VERSION "created by canmatrix"

NS_ :

BS_:

BU_: CEM HUT GW T_BOX XBOX_D DVR Tester

BO_ 482 HCU_HC8: 8 GW
 SG_ HCU_PhoneChrgnModeResp : 15|1@0+ (1,0) [0|1] ""  T_BOX
 SG_ HCU_PhoneChrgnReqResp : 14|1@0+ (1,0) [0|1] ""  T_BOX
 SG_ HCU_HUTChrgnModeResp : 13|1@0+ (1,0) [0|1] ""  T_BOX
 SG_ HCU_HUTChrgnReqResp : 12|1@0+ (1,0) [0|1] ""  T_BOX
 SG_ HCU_TboxEngStrtReq : 11|1@0+ (1,0) [0|1] ""  T_BOX
 SG_ HCU_TotalScore : 23|3@0+ (1,0) [0|5] ""  HUT
 SG_ HCU_HC8_0x1E2 : 0|64@1+ (1,0) [0|0] ""  HUT

BO_ 483 BMS_FD14: 8 GW
 SG_ BMS_ChrgTimResp : 9|1@0+ (1,0) [0|1] ""  HUT,T_BOX
 SG_ BMS_FD14_0x1E3 : 0|64@1+ (1,0) [0|0] ""  HUT

BO_ 510 T_BOX_FD9: 8 T_BOX
 SG_ T_BOX_RemtDrvSeatHeatgLvlSet_Nin : 11|4@0+ (1,0) [0|15] ""  CEM
 SG_ T_BOX_RemtPassSeatHeatgLvlSet_Ni : 15|4@0+ (1,0) [0|15] ""  CEM
 SG_ T_BOX_RemtSecRowLeSeatHeatgLvlSe : 19|4@0+ (1,0) [0|15] ""  CEM
 SG_ T_BOX_RemtSecRowRiSeatHeatgLvlSe : 23|4@0+ (1,0) [0|15] ""  CEM
 SG_ T_BOX_ChrgTim_Hour : 39|5@0+ (1,0) [0|31] ""  GW
 SG_ T_BOX_ChrgTim_Minutes : 34|6@0+ (1,0) [0|63] ""  GW
 SG_ T_BOX_ChrgTim_Second : 44|6@0+ (1,0) [0|63] ""  GW
 SG_ T_BOX_ChrgTim_Year_Left : 31|4@0+ (1,0) [0|15] ""  GW
 SG_ T_BOX_ChrgTim_Year_Right : 27|4@0+ (1,0) [0|15] ""  GW
 SG_ T_BOX_ChrgTim_Month : 54|4@0+ (1,0) [0|15] ""  GW
 SG_ T_BOX_ChrgTim_Day : 50|5@0+ (1,0) [0|31] ""  GW,HUT
 SG_ T_BOX_FD9_0x1FE : 0|64@1+ (1,0) [0|0] ""  HUT

BO_ 513 HCU_HP5: 8 GW
 SG_ HCU_V2LReminder : 19|2@0+ (1,0) [0|3] ""  HUT
 SG_ HCU_SOCMngmntSts : 55|1@0+ (1,0) [0|1] ""  HUT
 SG_ HCU_ARFSts : 54|1@0+ (1,0) [0|1] ""  HUT
 SG_ HCU_ASFCSts : 53|1@0+ (1,0) [0|1] ""  HUT
 SG_ HCU_AGSSts : 52|1@0+ (1,0) [0|1] ""  HUT
 SG_ PDCU_AvailabilityOfARF : 51|4@0+ (1,0) [0|5] ""  HUT
 SG_ PDCU_lossenPedalPrompt : 63|1@0+ (1,0) [0|1] ""  HUT
 SG_ PDCU_EvSave_disl : 62|1@0+ (1,0) [0|1] ""  HUT
 SG_ HCU_HP5_0x201 : 0|64@1+ (1,0) [0|0] ""  HUT

BO_ 515 HUT_FD2: 64 HUT
 SG_ HUT_OD_Obj0_ID : 15|4@0+ (1,0) [0|9] "" Vector__XXX
 SG_ HUT_OD_Obj0_type : 23|3@0+ (1,0) [0|7] "" Vector__XXX
 SG_ HUT_OD_Obj0_Confidence : 11|4@0+ (0.1,0) [0|1] "" Vector__XXX
 SG_ HUT_OD_Obj0_width : 20|7@0+ (0.1,0) [0|12.6] "m" Vector__XXX
 SG_ HUT_OD_Obj0_Ground_Pos_X : 39|12@0+ (0.01,0) [0|40] "m" Vector__XXX
 SG_ HUT_OD_Obj0_Ground_Pos_Y : 43|12@0+ (0.01,-20) [-20|20] "m" Vector__XXX
 SG_ HTU_OD_Obj1_ID : 79|4@0+ (1,0) [0|9] "" Vector__XXX
 SG_ HUT_OD_Obj1_type : 87|3@0+ (1,0) [0|7] "" Vector__XXX
 SG_ HUT_OD_Obj1_Confidence : 75|4@0+ (0.1,0) [0|1] "" Vector__XXX
 SG_ HUT_OD_Obj1_width : 84|7@0+ (0.1,0) [0|12.6] "m" Vector__XXX
 SG_ HUT_OD_Obj1_Ground_Pos_X : 103|12@0+ (0.01,0) [0|40] "m" Vector__XXX
 SG_ HUT_OD_Obj1_Ground_Pos_Y : 107|12@0+ (0.01,-20) [-20|20] "m" Vector__XXX
 SG_ HUT_OD_Obj2_ID : 143|4@0+ (1,0) [0|9] "" Vector__XXX
 SG_ HUT_OD_Obj2_type : 151|3@0+ (1,0) [0|7] "" Vector__XXX
 SG_ HUT_OD_Obj2_Confidence : 139|4@0+ (0.1,0) [0|1] "" Vector__XXX
 SG_ HUT_OD_Obj2_width : 148|7@0+ (0.1,0) [0|12.6] "m" Vector__XXX
 SG_ HUT_OD_Obj2_Ground_Pos_X : 167|12@0+ (0.01,0) [0|40] "m" Vector__XXX
 SG_ HUT_OD_Obj2_Ground_Pos_Y : 171|12@0+ (0.01,-20) [-20|20] "m" Vector__XXX
 SG_ HUT_OD_Obj3_ID : 207|4@0+ (1,0) [0|9] "" Vector__XXX
 SG_ HUT_OD_Obj3_type : 215|3@0+ (1,0) [0|7] "" Vector__XXX
 SG_ HUT_OD_Obj3_Confidence : 203|4@0+ (0.1,0) [0|1] "" Vector__XXX
 SG_ HUT_OD_Obj3_width : 212|7@0+ (0.1,0) [0|12.6] "m" Vector__XXX
 SG_ HUT_OD_Obj3_Ground_Pos_X : 231|12@0+ (0.01,0) [0|40] "m" Vector__XXX
 SG_ HUT_OD_Obj3_Ground_Pos_Y : 235|12@0+ (0.01,-20) [-20|20] "m" Vector__XXX
 SG_ HUT_OD_Obj4_ID : 271|4@0+ (1,0) [0|9] "" Vector__XXX
 SG_ HUT_OD_Obj4_type : 279|3@0+ (1,0) [0|7] "" Vector__XXX
 SG_ HUT_OD_Obj4_Confidence : 267|4@0+ (0.1,0) [0|1] "" Vector__XXX
 SG_ HUT_OD_Obj4_width : 276|7@0+ (0.1,0) [0|12.6] "m" Vector__XXX
 SG_ HUT_OD_Obj4_Ground_Pos_X : 295|12@0+ (0.01,0) [0|40] "m" Vector__XXX
 SG_ HUT_OD_Obj4_Ground_Pos_Y : 299|12@0+ (0.01,-20) [-20|20] "m" Vector__XXX
 SG_ HUT_OD_Obj5_ID : 335|4@0+ (1,0) [0|9] "" Vector__XXX
 SG_ HUT_OD_Obj5_type : 343|3@0+ (1,0) [0|7] "" Vector__XXX
 SG_ HUT_OD_Obj5_Confidence : 331|4@0+ (0.1,0) [0|1] "" Vector__XXX
 SG_ HUT_OD_Obj5_width : 340|7@0+ (0.1,0) [0|12.6] "m" Vector__XXX
 SG_ HUT_OD_Obj5_Ground_Pos_X : 359|12@0+ (0.01,0) [0|40] "m" Vector__XXX
 SG_ HUT_OD_Obj5_Ground_Pos_Y : 363|12@0+ (0.01,-20) [-20|20] "m" Vector__XXX
 SG_ HUT_OD_Obj6_ID : 399|4@0+ (1,0) [0|9] "" Vector__XXX
 SG_ HUT_OD_Obj6_type : 407|3@0+ (1,0) [0|7] "" Vector__XXX
 SG_ HUT_OD_Obj6_Confidence : 395|4@0+ (0.1,0) [0|1] "" Vector__XXX
 SG_ HUT_OD_Obj6_width : 404|7@0+ (0.1,0) [0|12.6] "m" Vector__XXX
 SG_ HUT_OD_Obj6_Ground_Pos_X : 423|12@0+ (0.01,0) [0|40] "m" Vector__XXX
 SG_ HUT_OD_Obj6_Ground_Pos_Y : 427|12@0+ (0.01,-20) [-20|20] "m" Vector__XXX
 SG_ HUT_FD2_0x203 : 0|512@1+ (1,0) [0|0] "" Vector__XXX

BO_ 616 HCU_HC3: 8 GW
 SG_ HCU_ChrgDchrgSts : 39|2@0+ (1,0) [0|3] ""  T_BOX
 SG_ HCU_BattLowTempWarn : 51|2@0+ (1,0) [0|3] ""  HUT
 SG_ HCU_BattLowTempHeatSts : 49|2@0+ (1,0) [0|3] ""  HUT
 SG_ HCU_HC3_0x268 : 0|64@1+ (1,0) [0|0] ""  HUT

BO_ 645 BMS8: 8 GW
 SG_ BMS_BattHeatRunaway : 61|2@0+ (1,0) [0|3] ""  HUT,T_BOX
 SG_ BMS_DisSOC1 : 31|8@0+ (1,0) [0|100] "%"  HUT,T_BOX
 SG_ BMS8_0x285 : 0|64@1+ (1,0) [0|0] ""  HUT

BO_ 690 HUT27: 8 HUT
 SG_ ExpertModReq_HUT_HCU : 62|2@0+ (1,0) [0|3] ""  GW
 SG_ HUT27_0x2B2 : 0|64@1+ (1,0) [0|0] "" Vector__XXX

BO_ 708 BMS35: 8 GW
 SG_ BMS_BattSOCLimResp : 42|3@0+ (1,0) [0|7] ""  HUT
 SG_ BMS35_0x2C4 : 0|64@1+ (1,0) [0|0] ""  HUT

BO_ 743 BCM10: 16 CEM
 SG_ RFPosnLmpWorkCmd : 15|1@0+ (1,0) [0|1] ""  T_BOX
 SG_ LFPosnLmpWorkCmd : 12|1@0+ (1,0) [0|1] ""  T_BOX
 SG_ HiBeamWorkCmd : 11|1@0+ (1,0) [0|1] ""  T_BOX
 SG_ LowBeamWorkCmd : 10|1@0+ (1,0) [0|1] ""  T_BOX
 SG_ RTurnLmpWorkCmd : 9|1@0+ (1,0) [0|1] ""  T_BOX
 SG_ LTurnLampWorkCmd : 8|1@0+ (1,0) [0|1] ""  T_BOX
 SG_ RDayRunngLmpWorkCmd : 21|1@0+ (1,0) [0|1] ""  T_BOX
 SG_ LDayRunngLmpWorkCmd : 20|1@0+ (1,0) [0|1] ""  T_BOX
 SG_ RFFogLmpWorkCmd : 19|1@0+ (1,0) [0|1] ""  T_BOX
 SG_ LFFogLmpWorkCmd : 18|1@0+ (1,0) [0|1] ""  T_BOX
 SG_ LicPlateLmpWorkCmd : 27|1@0+ (1,0) [0|1] ""  T_BOX
 SG_ ReversLampWorkCmd : 26|1@0+ (1,0) [0|1] ""  T_BOX
 SG_ BrkLmpWorkCmd : 25|1@0+ (1,0) [0|1] ""  T_BOX
 SG_ RFogLmpWorkCmd : 24|1@0+ (1,0) [0|1] ""  T_BOX
 SG_ RRPosnLmpWorkCmd : 47|1@0+ (1,0) [0|1] ""  T_BOX
 SG_ LRPosnLmpWorkCmd : 46|1@0+ (1,0) [0|1] ""  T_BOX

BO_ 788 HCU_HC6: 8 GW
 SG_ HCU_ACLineDisconnect : 33|2@0+ (1,0) [0|3] ""  HUT,T_BOX
 SG_ HCU_ChargSts : 47|3@0+ (1,0) [0|7] ""  HUT,T_BOX
 SG_ HCU_IntelBattTempMagSts : 37|1@0+ (1,0) [0|1] ""  HUT
 SG_ HCU_HC6_0x314 : 0|64@1+ (1,0) [0|0] ""  HUT

BO_ 790 OBC1: 8 GW
 SG_ OBC_ModSts : 19|4@0+ (1,0) [0|15] ""  HUT
 SG_ OBC1_0x316 : 0|64@1+ (1,0) [0|0] ""  HUT

BO_ 791 OBC2: 8 GW
 SG_ OBC_ConnectSts : 15|2@0+ (1,0) [0|3] ""  HUT,T_BOX
 SG_ OBC2_0x317 : 0|64@1+ (1,0) [0|0] ""  HUT

BO_ 829 T_BOX_FD6: 16 T_BOX
 SG_ T_BOX_RemtLRTempSet : 21|6@0+ (0.5,16) [16.5|31.5] "Ã‚Â°C"  GW
 SG_ T_BOX_RemtRRTempSet : 29|6@0+ (0.5,16) [16.5|31.5] "Ã‚Â°C" Vector__XXX
 SG_ T_BOX_RemtRearAutoCtrl : 47|2@0+ (1,0) [0|3] ""  GW
 SG_ T_BOX_RemtSecRowLeSeatVentnLvlSe : 10|3@0+ (1,0) [0|7] ""  CEM
 SG_ T_BOX_RemtSecRowRiSeatVentnLvlSe : 13|3@0+ (1,0) [0|7] ""  CEM
 SG_ T_BOX_MbrMonrEnReq : 35|2@0+ (1,0) [0|3] "" Vector__XXX
 SG_ ReleAlarm_APP : 33|2@0+ (1,0) [0|3] "" Vector__XXX
 SG_ T_BOX_RemtSteerWheelHeatCtrl : 15|2@0+ (1,0) [0|3] ""  GW
 SG_ T_BOX_AVPActvReq : 3|2@0+ (1,0) [0|3] ""  GW

BO_ 850 BMS19: 8 GW
 SG_ BMS_IntelEngIdlChrgnSts : 45|2@0+ (1,0) [0|3] ""  HUT
 SG_ BMS_BattKeepTempSts : 18|1@0+ (1,0) [0|1] ""  HUT
 SG_ BMS19_0x352 : 0|64@1+ (1,0) [0|0] ""  HUT

BO_ 865 HCU_FD6: 64 GW
 SG_ HCU_HVILSts : 218|2@0+ (1,0) [0|3] ""  T_BOX
 SG_ HCU_BMSSleepCmd : 216|1@0+ (1,0) [0|1] ""  T_BOX
 SG_ HCU_P2MActHvDcCurr_RM : 263|16@0+ (0.1,-1000) [-1000|1000] "A"  T_BOX
 SG_ HCU_P2MActHvDcVolt_RM : 279|16@0+ (0.1,0) [0|6000] "V"  T_BOX
 SG_ HCU_DTCNumber1 : 295|10@0+ (1,0) [0|1023] ""  T_BOX
 SG_ HCU_DTCNumber2 : 301|10@0+ (1,0) [0|1023] ""  T_BOX
 SG_ HCU_MotorAmount_RM : 335|8@0+ (1,0) [1|253] ""  T_BOX

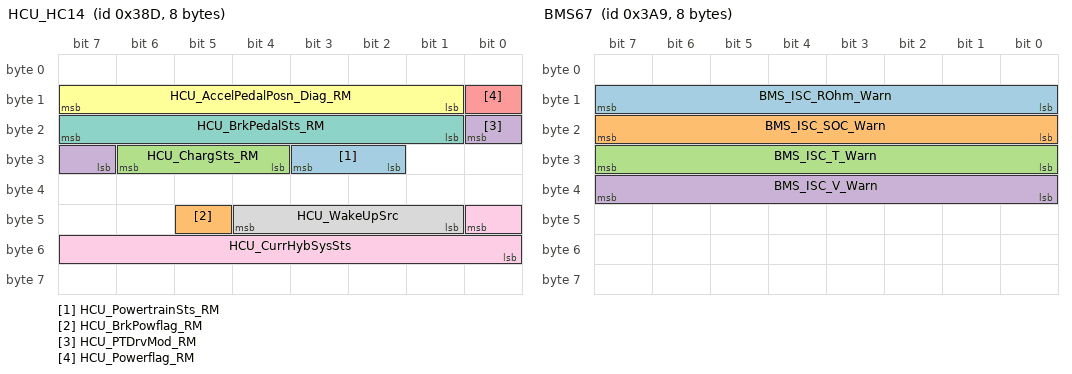
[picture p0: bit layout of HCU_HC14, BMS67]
BO_ 909 HCU_HC14: 8 GW
 SG_ HCU_PowertrainSts_RM : 27|2@0+ (1,0) [0|3] ""  T_BOX
 SG_ HCU_BrkPowflag_RM : 45|1@0+ (1,0) [0|1] ""  T_BOX
 SG_ HCU_ChargSts_RM : 30|3@0+ (1,0) [0|7] ""  T_BOX
 SG_ HCU_PTDrvMod_RM : 16|2@0+ (1,0) [0|3] ""  T_BOX
 SG_ HCU_Powerflag_RM : 8|1@0+ (1,0) [0|1] ""  T_BOX
 SG_ HCU_AccelPedalPosn_Diag_RM : 15|7@0+ (1,0) [0|100] "%"  T_BOX
 SG_ HCU_BrkPedalSts_RM : 23|7@0+ (1,0) [0|101] ""  T_BOX
 SG_ HCU_WakeUpSrc : 44|4@0+ (1,0) [0|15] ""  T_BOX
 SG_ HCU_CurrHybSysSts : 40|9@0+ (1,0) [0|500] ""  T_BOX

BO_ 937 BMS67: 8 GW
 SG_ BMS_ISC_ROhm_Warn : 15|8@0+ (0.1,0) [0|5] ""  T_BOX
 SG_ BMS_ISC_SOC_Warn : 23|8@0+ (1,0) [0|100] ""  T_BOX
 SG_ BMS_ISC_T_Warn : 31|8@0+ (1,-40) [-40|125] "Ã‚Â°C"  T_BOX
 SG_ BMS_ISC_V_Warn : 39|8@0+ (0.1,0) [0|5] "V"  T_BOX

BO_ 942 BMS66: 8 GW
 SG_ BMS_SocJumpWarn_RM : 7|1@0+ (1,0) [0|1] ""  HUT,T_BOX
 SG_ BMS_PackOverChrgWarn_RM : 6|1@0+ (1,0) [0|1] ""  HUT,T_BOX
 SG_ BMS_ChrgSts_RM : 5|3@0+ (1,0) [0|7] ""  HUT,T_BOX
 SG_ BMS_IsolationRValue_RM : 15|16@0+ (1,0) [0|60000] "Kohm"  HUT,T_BOX
 SG_ BMS_PackCurr_RM : 31|15@0+ (0.1,-1000) [-1000|1000] "A"  HUT,T_BOX
 SG_ BMS_SocOverWarn_RM : 32|1@0+ (1,0) [0|1] ""  HUT,T_BOX
 SG_ BMS_BattOverTempRank_RM : 47|1@0+ (1,0) [0|1] ""  HUT,T_BOX
 SG_ BMS_BattOverVoltRank_RM : 46|1@0+ (1,0) [0|1] ""  HUT,T_BOX
 SG_ BMS_BattSOCLowRank_RM : 45|1@0+ (1,0) [0|1] ""  HUT,T_BOX
 SG_ BMS_VCUIsolateErr_RM : 44|1@0+ (1,0) [0|1] ""  HUT,T_BOX
 SG_ BMS_BattUnderVoltRank_RM : 43|1@0+ (1,0) [0|1] ""  HUT,T_BOX
 SG_ BMS_CellDeltaVoltRank_RM : 42|1@0+ (1,0) [0|1] ""  HUT,T_BOX
 SG_ BMS_CellOverVoltRank_RM : 41|1@0+ (1,0) [0|1] ""  HUT,T_BOX
 SG_ BMS_CellUnderVoltRank_RM : 40|1@0+ (1,0) [0|1] ""  HUT,T_BOX
 SG_ BMS_DeltaTempRank_RM : 55|1@0+ (1,0) [0|1] ""  HUT,T_BOX
 SG_ BMS_PackMismatchWarn_RM : 54|1@0+ (1,0) [0|1] ""  HUT,T_BOX
 SG_ BMS_PackVolt_RM : 53|14@0+ (0.1,0) [0|1000] "V"  HUT,T_BOX
 SG_ BMS66_0x3AE : 0|64@1+ (1,0) [0|0] ""  HUT

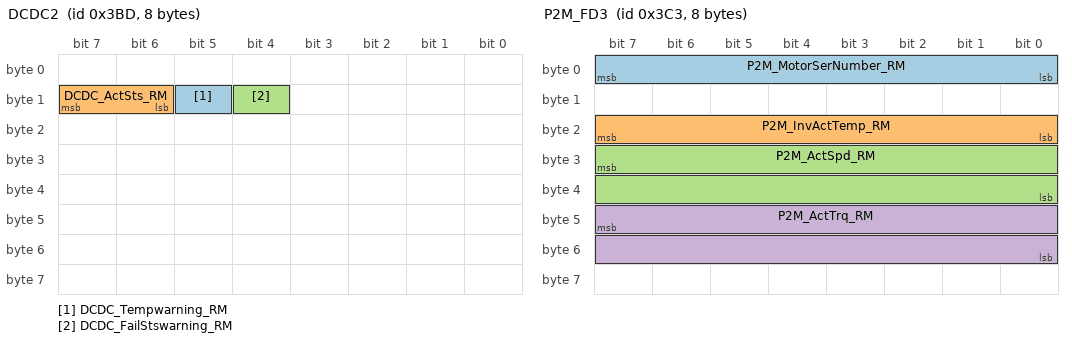
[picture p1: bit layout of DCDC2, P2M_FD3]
BO_ 957 DCDC2: 8 GW
 SG_ DCDC_Tempwarning_RM : 13|1@0+ (1,0) [0|1] ""  T_BOX
 SG_ DCDC_ActSts_RM : 15|2@0+ (1,0) [0|3] ""  T_BOX
 SG_ DCDC_FailStswarning_RM : 12|1@0+ (1,0) [0|1] ""  T_BOX

BO_ 959 BMS22: 8 GW
 SG_ BMS_ChrgDurationTime : 47|10@0+ (1,0) [0|1022] "minute"  HUT,T_BOX
 SG_ BMS22_0x3BF : 0|64@1+ (1,0) [0|0] ""  HUT

BO_ 963 P2M_FD3: 8 GW
 SG_ P2M_MotorSerNumber_RM : 7|8@0+ (1,0) [1|253] ""  T_BOX
 SG_ P2M_InvActTemp_RM : 23|8@0+ (1,-40) [-40|210] "Ã‚Â°C"  T_BOX
 SG_ P2M_ActSpd_RM : 31|16@0+ (1,-20000) [-20000|45531] "rpm"  T_BOX
 SG_ P2M_ActTrq_RM : 47|16@0+ (0.1,-2000) [-2000|4553.1] "Nm"  T_BOX

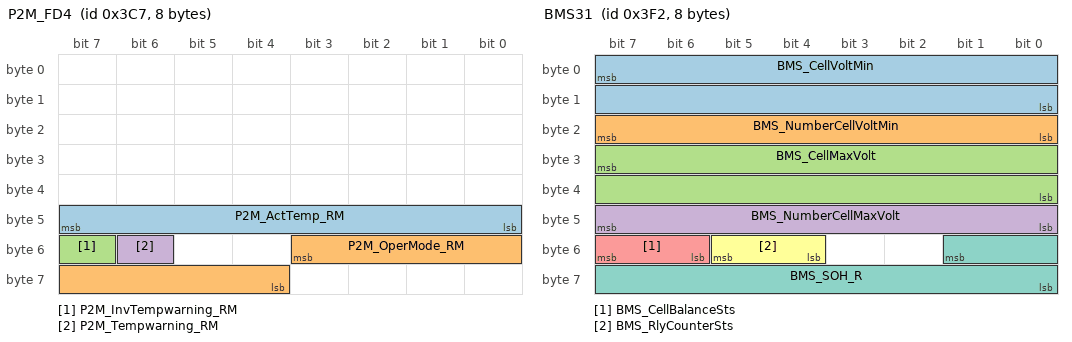
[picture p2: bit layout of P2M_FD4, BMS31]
BO_ 967 P2M_FD4: 8 GW
 SG_ P2M_ActTemp_RM : 47|8@0+ (1,-40) [-40|210] "Ã‚Â°C"  T_BOX
 SG_ P2M_OperMode_RM : 51|8@0+ (1,0) [0|255] ""  T_BOX
 SG_ P2M_InvTempwarning_RM : 55|1@0+ (1,0) [0|1] ""  T_BOX
 SG_ P2M_Tempwarning_RM : 54|1@0+ (1,0) [0|1] ""  T_BOX

BO_ 976 BMS26: 8 GW
 SG_ BMS_BattTempMax : 15|8@0+ (1,-40) [-40|90] "Ã‚Â°C"  T_BOX
 SG_ BMS_BattTempMin : 23|8@0+ (1,-40) [-40|90] "Ã‚Â°C"  T_BOX

BO_ 977 BMS_FD5: 64 GW
 SG_ BMS_SingleCellVolt_1 : 263|16@0+ (0.001,0) [0|60] "V"  T_BOX
 SG_ BMS_SingleCellVolt_2 : 279|16@0+ (0.001,0) [0|60] "V"  T_BOX
 SG_ BMS_SingleCellVolt_3 : 295|16@0+ (0.001,0) [0|60] "V"  T_BOX
 SG_ BMS_SingleCellVolt_4 : 311|16@0+ (0.001,0) [0|60] "V"  T_BOX
 SG_ BMS_SingleCellVolt_5 : 327|16@0+ (0.001,0) [0|60] "V"  T_BOX
 SG_ BMS_SingleCellVolt_6 : 343|16@0+ (0.001,0) [0|60] "V"  T_BOX
 SG_ BMS_SingleCellVolt_7 : 359|16@0+ (0.001,0) [0|60] "V"  T_BOX
 SG_ BMS_SingleCellVolt_8 : 375|16@0+ (0.001,0) [0|60] "V"  T_BOX
 SG_ BMS_SingleCellVolt_9 : 391|16@0+ (0.001,0) [0|60] "V"  T_BOX
 SG_ BMS_SingleCellVolt_10 : 407|16@0+ (0.001,0) [0|60] "V"  T_BOX
 SG_ BMS_SingleCellVolt_11 : 423|16@0+ (0.001,0) [0|60] "V"  T_BOX
 SG_ BMS_SingleCellVolt_12 : 439|16@0+ (0.001,0) [0|60] "V"  T_BOX
 SG_ BMS_BattModuleTe_11 : 135|8@0+ (1,-40) [-40|125] "Ã‚Â°C"  T_BOX
 SG_ BMS_BattModuleTe_12 : 143|8@0+ (1,-40) [-40|125] "Ã‚Â°C"  T_BOX
 SG_ BMS_BattModuleTe_21 : 151|8@0+ (1,-40) [-40|125] "Ã‚Â°C"  T_BOX
 SG_ BMS_BattModuleTe_22 : 159|8@0+ (1,-40) [-40|125] "Ã‚Â°C"  T_BOX
 SG_ BMS_BattModuleTe_31 : 167|8@0+ (1,-40) [-40|125] "Ã‚Â°C"  T_BOX
 SG_ BMS_BattModuleTe_32 : 175|8@0+ (1,-40) [-40|125] "Ã‚Â°C"  T_BOX
 SG_ BMS_BattModuleTe_41 : 183|8@0+ (1,-40) [-40|125] "Ã‚Â°C"  T_BOX
 SG_ BMS_BattModuleTe_42 : 191|8@0+ (1,-40) [-40|125] "Ã‚Â°C"  T_BOX
 SG_ BMS_BattModuleTe_51 : 71|8@0+ (1,-40) [-40|125] "Ã‚ÂºC"  T_BOX
 SG_ BMS_BattModuleTe_52 : 79|8@0+ (1,-40) [-40|125] "Ã‚ÂºC"  T_BOX
 SG_ BMS_BattModuleTe_61 : 87|8@0+ (1,-40) [-40|125] "Ã‚ÂºC"  T_BOX
 SG_ BMS_BattModuleTe_62 : 95|8@0+ (1,-40) [-40|125] "Ã‚ÂºC"  T_BOX
 SG_ BMS_BattModuleTe_71 : 103|8@0+ (1,-40) [-40|125] "Ã‚ÂºC"  T_BOX
 SG_ BMS_BattModuleTe_72 : 111|8@0+ (1,-40) [-40|125] "Ã‚ÂºC"  T_BOX
 SG_ BMS_BattModuleTe_81 : 119|8@0+ (1,-40) [-40|125] "Ã‚ÂºC"  T_BOX
 SG_ BMS_BattModuleTe_82 : 127|8@0+ (1,-40) [-40|125] "Ã‚ÂºC"  T_BOX

BO_ 978 BMS_FD6: 64 GW
 SG_ BMS_SingleCellVolt_13 : 7|16@0+ (0.001,0) [0|60] "V"  T_BOX
 SG_ BMS_SingleCellVolt_14 : 23|16@0+ (0.001,0) [0|60] "V"  T_BOX
 SG_ BMS_SingleCellVolt_15 : 39|16@0+ (0.001,0) [0|60] "V"  T_BOX
 SG_ BMS_SingleCellVolt_16 : 55|16@0+ (0.001,0) [0|60] "V"  T_BOX
 SG_ BMS_SingleCellVolt_17 : 71|16@0+ (0.001,0) [0|60] "V"  T_BOX
 SG_ BMS_SingleCellVolt_18 : 87|16@0+ (0.001,0) [0|60] "V"  T_BOX
 SG_ BMS_SingleCellVolt_19 : 103|16@0+ (0.001,0) [0|60] "V"  T_BOX
 SG_ BMS_SingleCellVolt_20 : 119|16@0+ (0.001,0) [0|60] "V"  T_BOX
 SG_ BMS_SingleCellVolt_21 : 135|16@0+ (0.001,0) [0|60] "V"  T_BOX
 SG_ BMS_SingleCellVolt_22 : 151|16@0+ (0.001,0) [0|60] "V"  T_BOX
 SG_ BMS_SingleCellVolt_23 : 167|16@0+ (0.001,0) [0|60] "V"  T_BOX
 SG_ BMS_SingleCellVolt_24 : 183|16@0+ (0.001,0) [0|60] "V"  T_BOX
 SG_ BMS_SingleCellVolt_25 : 199|16@0+ (0.001,0) [0|60] "V"  T_BOX
 SG_ BMS_SingleCellVolt_26 : 215|16@0+ (0.001,0) [0|60] "V"  T_BOX
 SG_ BMS_SingleCellVolt_27 : 231|16@0+ (0.001,0) [0|60] "V"  T_BOX
 SG_ BMS_SingleCellVolt_28 : 247|16@0+ (0.001,0) [0|60] "V"  T_BOX
 SG_ BMS_SingleCellVolt_29 : 263|16@0+ (0.001,0) [0|60] "V"  T_BOX
 SG_ BMS_SingleCellVolt_30 : 279|16@0+ (0.001,0) [0|60] "V"  T_BOX
 SG_ BMS_SingleCellVolt_31 : 295|16@0+ (0.001,0) [0|60] "V"  T_BOX
 SG_ BMS_SingleCellVolt_32 : 311|16@0+ (0.001,0) [0|60] "V"  T_BOX
 SG_ BMS_SingleCellVolt_33 : 327|16@0+ (0.001,0) [0|60] "V"  T_BOX
 SG_ BMS_SingleCellVolt_34 : 343|16@0+ (0.001,0) [0|60] "V"  T_BOX
 SG_ BMS_SingleCellVolt_35 : 359|16@0+ (0.001,0) [0|60] "V"  T_BOX
 SG_ BMS_SingleCellVolt_36 : 375|16@0+ (0.001,0) [0|60] "V"  T_BOX
 SG_ BMS_SingleCellVolt_37 : 391|16@0+ (0.001,0) [0|60] "V"  T_BOX
 SG_ BMS_SingleCellVolt_38 : 407|16@0+ (0.001,0) [0|60] "V"  T_BOX
 SG_ BMS_SingleCellVolt_39 : 423|16@0+ (0.001,0) [0|60] "V"  T_BOX
 SG_ BMS_SingleCellVolt_40 : 439|16@0+ (0.001,0) [0|60] "V"  T_BOX

BO_ 979 BMS_FD7: 64 GW
 SG_ BMS_SingleCellVolt_41 : 7|16@0+ (0.001,0) [0|60] "V"  T_BOX
 SG_ BMS_SingleCellVolt_42 : 23|16@0+ (0.001,0) [0|60] "V"  T_BOX
 SG_ BMS_SingleCellVolt_43 : 39|16@0+ (0.001,0) [0|60] "V"  T_BOX
 SG_ BMS_SingleCellVolt_44 : 55|16@0+ (0.001,0) [0|60] "V"  T_BOX
 SG_ BMS_SingleCellVolt_45 : 71|16@0+ (0.001,0) [0|60] "V"  T_BOX
 SG_ BMS_SingleCellVolt_46 : 87|16@0+ (0.001,0) [0|60] "V"  T_BOX
 SG_ BMS_SingleCellVolt_47 : 103|16@0+ (0.001,0) [0|60] "V"  T_BOX
 SG_ BMS_SingleCellVolt_48 : 119|16@0+ (0.001,0) [0|60] "V"  T_BOX
 SG_ BMS_SingleCellVolt_49 : 135|16@0+ (0.001,0) [0|60] "V"  T_BOX
 SG_ BMS_SingleCellVolt_50 : 151|16@0+ (0.001,0) [0|60] "V"  T_BOX
 SG_ BMS_SingleCellVolt_51 : 167|16@0+ (0.001,0) [0|60] "V"  T_BOX
 SG_ BMS_SingleCellVolt_52 : 183|16@0+ (0.001,0) [0|60] "V"  T_BOX
 SG_ BMS_SingleCellVolt_53 : 199|16@0+ (0.001,0) [0|60] "V"  T_BOX
 SG_ BMS_SingleCellVolt_54 : 215|16@0+ (0.001,0) [0|60] "V"  T_BOX
 SG_ BMS_SingleCellVolt_55 : 231|16@0+ (0.001,0) [0|60] "V"  T_BOX
 SG_ BMS_SingleCellVolt_56 : 247|16@0+ (0.001,0) [0|60] "V"  T_BOX
 SG_ BMS_SingleCellVolt_57 : 263|16@0+ (0.001,0) [0|60] "V"  T_BOX
 SG_ BMS_SingleCellVolt_58 : 279|16@0+ (0.001,0) [0|60] "V"  T_BOX
 SG_ BMS_SingleCellVolt_59 : 295|16@0+ (0.001,0) [0|60] "V"  T_BOX
 SG_ BMS_SingleCellVolt_60 : 311|16@0+ (0.001,0) [0|60] "V"  T_BOX
 SG_ BMS_SingleCellVolt_61 : 327|16@0+ (0.001,0) [0|60] "V"  T_BOX
 SG_ BMS_SingleCellVolt_62 : 343|16@0+ (0.001,0) [0|60] "V"  T_BOX
 SG_ BMS_SingleCellVolt_63 : 359|16@0+ (0.001,0) [0|60] "V"  T_BOX
 SG_ BMS_SingleCellVolt_64 : 375|16@0+ (0.001,0) [0|60] "V"  T_BOX
 SG_ BMS_SingleCellVolt_65 : 391|16@0+ (0.001,0) [0|60] "V"  T_BOX
 SG_ BMS_SingleCellVolt_66 : 407|16@0+ (0.001,0) [0|60] "V"  T_BOX
 SG_ BMS_SingleCellVolt_67 : 423|16@0+ (0.001,0) [0|60] "V"  T_BOX
 SG_ BMS_SingleCellVolt_68 : 439|16@0+ (0.001,0) [0|60] "V"  T_BOX

BO_ 980 BMS_FD8: 64 GW
 SG_ BMS_SingleCellVolt_69 : 7|16@0+ (0.001,0) [0|60] "V"  T_BOX
 SG_ BMS_SingleCellVolt_70 : 23|16@0+ (0.001,0) [0|60] "V"  T_BOX
 SG_ BMS_SingleCellVolt_71 : 39|16@0+ (0.001,0) [0|60] "V"  T_BOX
 SG_ BMS_SingleCellVolt_72 : 55|16@0+ (0.001,0) [0|60] "V"  T_BOX
 SG_ BMS_SingleCellVolt_73 : 71|16@0+ (0.001,0) [0|60] "V"  T_BOX
 SG_ BMS_SingleCellVolt_74 : 87|16@0+ (0.001,0) [0|60] "V"  T_BOX
 SG_ BMS_SingleCellVolt_75 : 103|16@0+ (0.001,0) [0|60] "V"  T_BOX
 SG_ BMS_SingleCellVolt_76 : 119|16@0+ (0.001,0) [0|60] "V"  T_BOX
 SG_ BMS_SingleCellVolt_77 : 135|16@0+ (0.001,0) [0|60] "V"  T_BOX
 SG_ BMS_SingleCellVolt_78 : 151|16@0+ (0.001,0) [0|60] "V"  T_BOX
 SG_ BMS_SingleCellVolt_79 : 167|16@0+ (0.001,0) [0|60] "V"  T_BOX
 SG_ BMS_SingleCellVolt_80 : 183|16@0+ (0.001,0) [0|60] "V"  T_BOX
 SG_ BMS_SingleCellVolt_81 : 199|16@0+ (0.001,0) [0|60] "V"  T_BOX
 SG_ BMS_SingleCellVolt_82 : 215|16@0+ (0.001,0) [0|60] "V"  T_BOX
 SG_ BMS_SingleCellVolt_83 : 231|16@0+ (0.001,0) [0|60] "V"  T_BOX
 SG_ BMS_SingleCellVolt_84 : 247|16@0+ (0.001,0) [0|60] "V"  T_BOX
 SG_ BMS_SingleCellVolt_85 : 263|16@0+ (0.001,0) [0|60] "V"  T_BOX
 SG_ BMS_SingleCellVolt_86 : 279|16@0+ (0.001,0) [0|60] "V"  T_BOX
 SG_ BMS_SingleCellVolt_87 : 295|16@0+ (0.001,0) [0|60] "V"  T_BOX
 SG_ BMS_SingleCellVolt_88 : 311|16@0+ (0.001,0) [0|60] "V"  T_BOX
 SG_ BMS_SingleCellVolt_89 : 327|16@0+ (0.001,0) [0|60] "V"  T_BOX
 SG_ BMS_SingleCellVolt_90 : 343|16@0+ (0.001,0) [0|60] "V"  T_BOX
 SG_ BMS_SingleCellVolt_91 : 359|16@0+ (0.001,0) [0|60] "V"  T_BOX
 SG_ BMS_SingleCellVolt_92 : 375|16@0+ (0.001,0) [0|60] "V"  T_BOX
 SG_ BMS_SingleCellVolt_93 : 391|16@0+ (0.001,0) [0|60] "V"  T_BOX
 SG_ BMS_SingleCellVolt_94 : 407|16@0+ (0.001,0) [0|60] "V"  T_BOX
 SG_ BMS_SingleCellVolt_95 : 423|16@0+ (0.001,0) [0|60] "V"  T_BOX
 SG_ BMS_SingleCellVolt_96 : 439|16@0+ (0.001,0) [0|60] "V"  T_BOX

BO_ 981 BMS_FD9: 64 GW
 SG_ BMS_SingleCellVolt_97 : 7|16@0+ (0.001,0) [0|60] "V"  T_BOX
 SG_ BMS_SingleCellVolt_98 : 23|16@0+ (0.001,0) [0|60] "V"  T_BOX
 SG_ BMS_SingleCellVolt_99 : 39|16@0+ (0.001,0) [0|60] "V"  T_BOX
 SG_ BMS_SingleCellVolt_100 : 55|16@0+ (0.001,0) [0|60] "V"  T_BOX
 SG_ BMS_SingleCellVolt_101 : 71|16@0+ (0.001,0) [0|60] "V"  T_BOX
 SG_ BMS_SingleCellVolt_102 : 87|16@0+ (0.001,0) [0|60] "V"  T_BOX
 SG_ BMS_SingleCellVolt_103 : 103|16@0+ (0.001,0) [0|60] "V"  T_BOX
 SG_ BMS_SingleCellVolt_104 : 119|16@0+ (0.001,0) [0|60] "V"  T_BOX
 SG_ BMS_SingleCellVolt_105 : 135|16@0+ (0.001,0) [0|60] "V"  T_BOX
 SG_ BMS_SingleCellVolt_106 : 151|16@0+ (0.001,0) [0|60] "V"  T_BOX
 SG_ BMS_SingleCellVolt_107 : 167|16@0+ (0.001,0) [0|60] "V"  T_BOX
 SG_ BMS_SingleCellVolt_108 : 183|16@0+ (0.001,0) [0|60] "V"  T_BOX
 SG_ BMS_BattModuleTe_13 : 391|8@0+ (1,-40) [-40|125] "Ã‚Â°C"  T_BOX
 SG_ BMS_BattModuleTe_23 : 399|8@0+ (1,-40) [-40|125] "Ã‚Â°C"  T_BOX
 SG_ BMS_BattModuleTe_33 : 407|8@0+ (1,-40) [-40|125] "Ã‚Â°C"  T_BOX
 SG_ BMS_DTCNumber : 279|9@0+ (1,0) [0|501] ""  T_BOX
 SG_ BMS_BattModuleTe_91 : 263|8@0+ (1,-40) [-40|125] "Ã‚Â°C"  T_BOX
 SG_ BMS_BattModuleTe_92 : 271|8@0+ (1,-40) [-40|125] "Ã‚Â°C"  T_BOX
 SG_ BMS_DTCNumber1 : 335|9@0+ (1,0) [0|500] ""  T_BOX
 SG_ BMS_DTCNumber2 : 342|9@0+ (1,0) [0|500] ""  T_BOX

BO_ 1009 BMS30: 8 GW
 SG_ BMS_SOCLowWarn : 31|1@0+ (1,0) [0|1] ""  HUT
 SG_ BMS_CellUnderVolt : 15|1@0+ (1,0) [0|1] ""  T_BOX
 SG_ BMS_CellOverVolt : 14|1@0+ (1,0) [0|1] ""  T_BOX
 SG_ BMS_CellDeltaVolt : 13|1@0+ (1,0) [0|1] ""  T_BOX
 SG_ BMS_BattUnderVolt : 12|1@0+ (1,0) [0|1] ""  T_BOX
 SG_ BMS_BattOverVolt : 11|1@0+ (1,0) [0|1] ""  T_BOX
 SG_ BMS_BattUnderTemp : 10|1@0+ (1,0) [0|1] ""  T_BOX
 SG_ BMS_SOC_Plaucheck : 9|1@0+ (1,0) [0|1] ""  T_BOX
 SG_ BMS_DeltaTemp : 8|1@0+ (1,0) [0|1] ""  T_BOX
 SG_ BMS_CANComErr : 23|1@0+ (1,0) [0|1] ""  T_BOX
 SG_ BMS_BattSOCLow : 22|1@0+ (1,0) [0|1] ""  T_BOX
 SG_ BMS_BattSOCTooLow : 21|1@0+ (1,0) [0|1] ""  T_BOX
 SG_ BMS_BattSOCHigh : 20|1@0+ (1,0) [0|1] ""  T_BOX
 SG_ BMS_ChrgnCurrLager : 19|1@0+ (1,0) [0|1] ""  T_BOX
 SG_ BMS_DischrgnCurrLager : 18|1@0+ (1,0) [0|1] ""  T_BOX
 SG_ BMS_ModuleMismatchWarn : 17|1@0+ (1,0) [0|1] ""  T_BOX
 SG_ BMS_cohrnc : 16|1@0+ (1,0) [0|1] ""  T_BOX
 SG_ BMS_moduleNumber : 43|4@0+ (1,1) [1|8] ""  T_BOX
 SG_ BMS_NumModuleTempSnsr : 28|5@0+ (1,1) [1|15] ""  T_BOX
 SG_ BMS_NumCell : 39|8@0+ (1,1) [1|108] ""  T_BOX
 SG_ BMS30_0x3F1 : 0|64@1+ (1,0) [0|0] ""  HUT

BO_ 1010 BMS31: 8 GW
 SG_ BMS_CellVoltMin : 7|16@0+ (0.001,0) [0|5] "V"  T_BOX
 SG_ BMS_NumberCellVoltMin : 23|8@0+ (1,1) [1|108] ""  T_BOX
 SG_ BMS_CellMaxVolt : 31|16@0+ (0.001,0) [0|5] "V"  T_BOX
 SG_ BMS_NumberCellMaxVolt : 47|8@0+ (1,1) [1|108] ""  T_BOX
 SG_ BMS_CellBalanceSts : 55|2@0+ (1,0) [0|1] ""  T_BOX
 SG_ BMS_RlyCounterSts : 53|2@0+ (1,0) [0|3] ""  T_BOX
 SG_ BMS_SOH_R : 49|10@0+ (0.1,100) [100|200] "%"  T_BOX

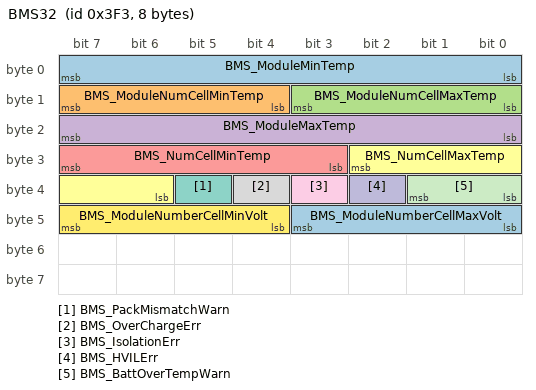
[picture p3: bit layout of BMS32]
BO_ 1011 BMS32: 8 GW
 SG_ BMS_ModuleMinTemp : 7|8@0+ (1,-40) [-40|90] "Ã‚ÂºC"  T_BOX
 SG_ BMS_ModuleNumCellMinTemp : 15|4@0+ (1,1) [1|9] ""  T_BOX
 SG_ BMS_ModuleNumCellMaxTemp : 11|4@0+ (1,1) [1|9] ""  T_BOX
 SG_ BMS_ModuleMaxTemp : 23|8@0+ (1,-40) [-40|90] "Ã‚ÂºC"  T_BOX
 SG_ BMS_NumCellMinTemp : 31|5@0+ (1,1) [1|18] "_"  T_BOX
 SG_ BMS_NumCellMaxTemp : 26|5@0+ (1,1) [1|18] "_"  T_BOX
 SG_ BMS_PackMismatchWarn : 37|1@0+ (1,0) [0|1] ""  T_BOX
 SG_ BMS_OverChargeErr : 36|1@0+ (1,0) [0|1] ""  T_BOX
 SG_ BMS_IsolationErr : 35|1@0+ (1,0) [0|1] ""  T_BOX
 SG_ BMS_HVILErr : 34|1@0+ (1,0) [0|1] ""  T_BOX
 SG_ BMS_BattOverTempWarn : 33|2@0+ (1,0) [0|3] ""  T_BOX
 SG_ BMS_ModuleNumberCellMinVolt : 47|4@0+ (1,1) [1|9] ""  T_BOX
 SG_ BMS_ModuleNumberCellMaxVolt : 43|4@0+ (1,1) [1|9] ""  T_BOX

BO_ 130 ECM4: 8 GW
 SG_ NetEngTrq : 15|16@0+ (0.0030518,-100) [-100|99.9966612] "%"  HUT
 SG_ DrvEngTrqReq : 31|16@0+ (0.0030518,-100) [-100|99.999713] "%"  HUT
 SG_ ECM4_0x82 : 0|64@1+ (1,0) [0|0] ""  HUT

BO_ 132 ECM7: 8 GW
 SG_ HCU_RaceLaunchAvail_0x84 : 61|2@0+ (1,0) [0|3] ""  HUT
 SG_ HCU_RaceLaunchSts_0x84 : 23|3@0+ (1,0) [0|7] ""  HUT
 SG_ ECM7_0x84 : 0|64@1+ (1,0) [0|0] ""  HUT

BO_ 158 HCU_HC16: 8 GW
 SG_ HCU_PowertrainSts_0x9e : 33|4@0+ (1,0) [0|15] ""  HUT,T_BOX
 SG_ HCU_TotDrvReqPower_0x9e : 25|8@0+ (1,-100) [-100|100] "%"  HUT
 SG_ TgtRcprtnTrqSts : 45|2@0+ (1,0) [0|3] ""  HUT
 SG_ HCU_HC16_0x9E : 0|64@1+ (1,0) [0|0] ""  HUT

BO_ 258 ECM9: 8 GW
 SG_ AccelPedlPosnDiagc : 39|8@0+ (0.3937,0) [0|100.3935] "%"  HUT
 SG_ ECM9_0x102 : 0|64@1+ (1,0) [0|0] ""  HUT

BO_ 335 BMS65: 8 GW
 SG_ BMS_BattSOC_P0 : 33|10@0+ (0.1,0) [0|100] "%"  HUT
 SG_ BMS65_0x14F : 0|64@1+ (1,0) [0|0] ""  HUT

BO_ 486 HUT36: 8 HUT
 SG_ MultiColorNr1 : 7|7@0+ (1,0) [0|64] ""  CEM
 SG_ MultiColorNr2 : 15|7@0+ (1,0) [0|64] ""  CEM
 SG_ MultiColorNr3 : 23|7@0+ (1,0) [0|64] ""  CEM
 SG_ MultiColorNr4 : 31|7@0+ (1,0) [0|64] ""  CEM
 SG_ MultiColorNr5 : 39|7@0+ (1,0) [0|64] ""  CEM
 SG_ MultiColorNr6 : 47|7@0+ (1,0) [0|64] ""  CEM
 SG_ MultiColorNr7 : 55|7@0+ (1,0) [0|64] ""  CEM
 SG_ MultiColorNr8 : 63|7@0+ (1,0) [0|64] ""  CEM
 SG_ HUT36_0x1E6 : 0|64@1+ (1,0) [0|0] "" Vector__XXX

BO_ 492 HUT37: 8 HUT
 SG_ MultiColorNr9 : 7|7@0+ (1,0) [0|64] ""  CEM
 SG_ MultiColorNr10 : 15|7@0+ (1,0) [0|64] ""  CEM
 SG_ MultiColorNr11 : 23|7@0+ (1,0) [0|64] ""  CEM
 SG_ MultiColorNr12 : 31|7@0+ (1,0) [0|64] ""  CEM
 SG_ MultiColorNr13 : 39|7@0+ (1,0) [0|64] ""  CEM
 SG_ MultiColorNr14 : 47|7@0+ (1,0) [0|64] ""  CEM
 SG_ MultiColorNr15 : 55|7@0+ (1,0) [0|64] ""  CEM
 SG_ MultiColorNr16 : 63|7@0+ (1,0) [0|64] ""  CEM
 SG_ HUT37_0x1EC : 0|64@1+ (1,0) [0|0] "" Vector__XXX

BO_ 724 ECM16: 8 GW
 SG_ DPF_Warning : 62|3@0+ (1,0) [0|7] ""  HUT
 SG_ WIFSensorFailSts : 51|2@0+ (1,0) [0|3] ""  HUT
 SG_ GlowPlugLmpCmd : 53|2@0+ (1,0) [0|3] ""  HUT
 SG_ UreaLampCmd : 27|2@0+ (1,0) [0|3] ""  HUT
 SG_ Urea_Level : 39|5@0+ (5,0) [0|100] "%"  HUT
 SG_ UreaRemainDist : 11|12@0+ (1,0) [0|4095] "Km"  HUT
 SG_ SCRSysWarnDisplay : 31|4@0+ (1,0) [0|15] ""  HUT
 SG_ WIFFullLmpCmd : 25|2@0+ (1,0) [0|3] ""  HUT
 SG_ DPF_Activation : 55|2@0+ (1,0) [0|3] ""  HUT
 SG_ ECM16_0x2D4 : 0|64@1+ (1,0) [0|0] ""  HUT

BO_ 763 VMDR1: 8 GW
 SG_ VMDR_TmpMonFctnSts : 29|1@0+ (1,0) [0|1] ""  HUT
 SG_ VMDR_InitAlarmDlySetSts : 28|1@0+ (1,0) [0|1] ""  HUT
 SG_ VMDR_FctnSts : 26|2@0+ (1,0) [0|3] ""  HUT
 SG_ VMDR1_0x2FB : 0|64@1+ (1,0) [0|0] ""  HUT

BO_ 848 ECM24: 8 GW
 SG_ EngOilLvlWrn : 31|2@0+ (1,0) [0|3] ""  HUT
 SG_ EngOilLowPresWrn : 16|1@0+ (1,0) [0|1] ""  HUT
 SG_ EngOilPres : 23|7@0+ (0.1,0) [0|12] "Bar"  HUT
 SG_ EngOilTemp : 15|8@0+ (1,-40) [-40|160] "Ã¢Â„Âƒ"  HUT
 SG_ ECM24_0x350 : 0|64@1+ (1,0) [0|0] ""  HUT

BO_ 1560 DVR_Phy_Req: 8 Tester
 SG_ DVR_Phy_Req : 7|64@0+ (1,0) [0|1.84467440737096E+019] ""  GW,DVR

BO_ 1561 DVR_Phy_Resp: 8 DVR
 SG_ DVR_Phy_Resp : 7|64@0+ (1,0) [0|1.84467440737096E+019] ""  GW,Tester

BO_ 1303 DVR_NM: 8 DVR
 SG_ Destination_DVR_NM : 7|8@0+ (1,0) [0|255] ""  CEM,T_BOX,XBOX_D,HUT
 SG_ OpCode_DVR_NM : 15|8@0+ (1,0) [0|255] ""  CEM,T_BOX,XBOX_D,HUT

CM_ SG_ 482 HCU_PhoneChrgnModeResp "After HCU received signal\"Phone_ChrgnMode\" , HCU shall make a Response to TBOX to confirm wether received successful or not";
CM_ SG_ 482 HCU_PhoneChrgnReqResp "After HCU received signal\"Phone_ChrgnReq\" , HCU shall make a Response to TBOX to confirm wether received successful or not";
CM_ SG_ 482 HCU_HUTChrgnModeResp "After HCU received signal\"HUT_ChrgnMode\" , HCU shall make a Response to TBOX to confirm wether received successful or not";
CM_ SG_ 482 HCU_HUTChrgnReqResp "After HCU received signal\"HUT_ChrgnReq\" , HCU shall make a Response to TBOX to confirm wether received successful or not";
CM_ SG_ 482 HCU_TboxEngStrtReq "Start engine request by Cellphone operation for Intelligent Engine";
CM_ SG_ 482 HCU_TotalScore "the Total score of the  driverÃ¢Â€Â˜s drive style and  energy consumption in this dirve cycle";
CM_ SG_ 483 BMS_ChrgTimResp "Charg Time Response";
CM_ SG_ 510 T_BOX_RemtDrvSeatHeatgLvlSet_Nin "Remote driver seat heating 9 level  set";
CM_ SG_ 510 T_BOX_RemtPassSeatHeatgLvlSet_Ni "Remote passenger seat heating 9 level  set";
CM_ SG_ 510 T_BOX_RemtSecRowLeSeatHeatgLvlSe "Remote second row left seat heating 9 level set";
CM_ SG_ 510 T_BOX_RemtSecRowRiSeatHeatgLvlSe "Remote second row right seat  heating  9 level set";
CM_ SG_ 510 T_BOX_ChrgTim_Hour "The Charge Time for hoursHC_CAN:To PDCU";
CM_ SG_ 510 T_BOX_ChrgTim_Minutes "The Charge Time for minutesHC_CAN:To PDCU";
CM_ SG_ 510 T_BOX_ChrgTim_Second "The Charge Time for secondsHC_CAN:To PDCU";
CM_ SG_ 510 T_BOX_ChrgTim_Year_Left "The Charge Time for yearsHC_CAN:To PDCU";
CM_ SG_ 510 T_BOX_ChrgTim_Year_Right "The Charge Time for yearsHC_CAN:To PDCU";
CM_ SG_ 510 T_BOX_ChrgTim_Month "The Charge Time for monthsHC_CAN:To PDCU";
CM_ SG_ 510 T_BOX_ChrgTim_Day "The Charge Time for daysHC_CAN:To PDCU";
CM_ SG_ 513 HCU_V2LReminder "V2L relevant
tips";
CM_ SG_ 513 HCU_SOCMngmntSts "The status of Soc management function";
CM_ SG_ 513 HCU_ARFSts "The status of adaptive recuperation function";
CM_ SG_ 513 HCU_ASFCSts "The status of adaptive startstop control function";
CM_ SG_ 513 HCU_AGSSts "The status of adaptive gear shifting function";
CM_ SG_ 513 PDCU_AvailabilityOfARF "the current availability status of the ARF function for display";
CM_ SG_ 513 PDCU_lossenPedalPrompt "the display signal about loosenthe accelerator pedal to IP for display at prompt time";
CM_ SG_ 513 PDCU_EvSave_disl "Inform the driver of Currently in 4L mode,EVSAVE mode is not availableÃ¢Â€Â";
CM_ SG_ 515 HUT_OD_Obj0_ID "ID of the Target obstacle";
CM_ SG_ 515 HUT_OD_Obj0_type "OD_typeADAS-CANFD To:PAS,RPAS";
CM_ SG_ 515 HUT_OD_Obj0_Confidence "Confidence of the Target obstacleADAS-CANFD To:PAS,RPAS";
CM_ SG_ 515 HUT_OD_Obj0_width "Width of the Target obstacleADAS-CANFD To:PAS,RPAS";
CM_ SG_ 515 HUT_OD_Obj0_Ground_Pos_X "X-Axis Position of the Target obstacleADAS-CANFD To:PAS,RPAS";
CM_ SG_ 515 HUT_OD_Obj0_Ground_Pos_Y "Y-Axis Position of the Target obstacleADAS-CANFD To:PAS,RPAS";
CM_ SG_ 515 HTU_OD_Obj1_ID "ID of the Target obstacleADAS-CANFD To:PAS,RPAS";
CM_ SG_ 515 HUT_OD_Obj1_type "OD_typeADAS-CANFD To:PAS,RPAS";
CM_ SG_ 515 HUT_OD_Obj1_Confidence "Confidence of the Target obstacleADAS-CANFD To:PAS,RPAS";
CM_ SG_ 515 HUT_OD_Obj1_width "Width of the Target obstacleADAS-CANFD To:PAS,RPAS";
CM_ SG_ 515 HUT_OD_Obj1_Ground_Pos_X "X-Axis Position of the Target obstacleADAS-CANFD To:PAS,RPAS";
CM_ SG_ 515 HUT_OD_Obj1_Ground_Pos_Y "Y-Axis Position of the Target obstacleADAS-CANFD To:PAS,RPAS";
CM_ SG_ 515 HUT_OD_Obj2_ID "ID of the Target obstacleADAS-CANFD To:PAS,RPAS";
CM_ SG_ 515 HUT_OD_Obj2_type "OD_typeADAS-CANFD To:PAS,RPAS";
CM_ SG_ 515 HUT_OD_Obj2_Confidence "Confidence of the Target obstacleADAS-CANFD To:PAS,RPAS";
CM_ SG_ 515 HUT_OD_Obj2_width "Width of the Target obstacleADAS-CANFD To:PAS,RPAS";
CM_ SG_ 515 HUT_OD_Obj2_Ground_Pos_X "X-Axis Position of the Target obstacleADAS-CANFD To:PAS,RPAS";
CM_ SG_ 515 HUT_OD_Obj2_Ground_Pos_Y "Y-Axis Position of the Target obstacleADAS-CANFD To:PAS,RPAS";
CM_ SG_ 515 HUT_OD_Obj3_ID "ID of the Target obstacleADAS-CANFD To:PAS,RPAS";
CM_ SG_ 515 HUT_OD_Obj3_type "OD_typeADAS-CANFD To:PAS,RPAS";
CM_ SG_ 515 HUT_OD_Obj3_Confidence "Confidence of the Target obstacleADAS-CANFD To:PAS,RPAS";
CM_ SG_ 515 HUT_OD_Obj3_width "Width of the Target obstacleADAS-CANFD To:PAS,RPAS";
CM_ SG_ 515 HUT_OD_Obj3_Ground_Pos_X "X-Axis Position of the Target obstacleADAS-CANFD To:PAS,RPAS";
CM_ SG_ 515 HUT_OD_Obj3_Ground_Pos_Y "Y-Axis Position of the Target obstacleADAS-CANFD To:PAS,RPAS";
CM_ SG_ 515 HUT_OD_Obj4_ID "ID of the Target obstacleADAS-CANFD To:PAS,RPAS";
CM_ SG_ 515 HUT_OD_Obj4_type "OD_typeADAS-CANFD To:PAS,RPAS";
CM_ SG_ 515 HUT_OD_Obj4_Confidence "Confidence of the Target obstacleADAS-CANFD To:PAS,RPAS";
CM_ SG_ 515 HUT_OD_Obj4_width "Width of the Target obstacleADAS-CANFD To:PAS,RPAS";
CM_ SG_ 515 HUT_OD_Obj4_Ground_Pos_X "X-Axis Position of the Target obstacleADAS-CANFD To:PAS,RPAS";
CM_ SG_ 515 HUT_OD_Obj4_Ground_Pos_Y "Y-Axis Position of the Target obstacleADAS-CANFD To:PAS,RPAS";
CM_ SG_ 515 HUT_OD_Obj5_ID "ID of the Target obstacleADAS-CANFD To:PAS,RPAS";
CM_ SG_ 515 HUT_OD_Obj5_type "OD_typeADAS-CANFD To:PAS,RPAS";
CM_ SG_ 515 HUT_OD_Obj5_Confidence "Confidence of the Target obstacleADAS-CANFD To:PAS,RPAS";
CM_ SG_ 515 HUT_OD_Obj5_width "Width of the Target obstacleADAS-CANFD To:PAS,RPAS";
CM_ SG_ 515 HUT_OD_Obj5_Ground_Pos_X "X-Axis Position of the Target obstacleADAS-CANFD To:PAS,RPAS";
CM_ SG_ 515 HUT_OD_Obj5_Ground_Pos_Y "Y-Axis Position of the Target obstacleADAS-CANFD To:PAS,RPAS";
CM_ SG_ 515 HUT_OD_Obj6_ID "ID of the Target obstacleADAS-CANFD To:PAS,RPAS";
CM_ SG_ 515 HUT_OD_Obj6_type "OD_typeADAS-CANFD To:PAS,RPAS";
CM_ SG_ 515 HUT_OD_Obj6_Confidence "Confidence of the Target obstacleADAS-CANFD To:PAS,RPAS";
CM_ SG_ 515 HUT_OD_Obj6_width "Width of the Target obstacleADAS-CANFD To:PAS,RPAS";
CM_ SG_ 515 HUT_OD_Obj6_Ground_Pos_X "X-Axis Position of the Target obstacleADAS-CANFD To:PAS,RPAS";
CM_ SG_ 515 HUT_OD_Obj6_Ground_Pos_Y "Y-Axis Position of the Target obstacleADAS-CANFD To:PAS,RPAS";
CM_ SG_ 616 HCU_ChrgDchrgSts "Chargingdischarging status";
CM_ SG_ 616 HCU_BattLowTempWarn "Battery low temperature low warn";
CM_ SG_ 616 HCU_BattLowTempHeatSts "Low temperature heating state of battery";
CM_ SG_ 645 BMS_BattHeatRunaway "Battery  Heat  Runaway";
CM_ SG_ 645 BMS_DisSOC1 "display battery SOC";
CM_ SG_ 690 ExpertModReq_HUT_HCU "HCU mode  request by HUTPT_CAN:To PDCU";
CM_ SG_ 708 BMS_BattSOCLimResp "After BMS received signal\"BattSOCLim\" , BMS shall make a Response to confirm wether received successful or not";
CM_ SG_ 743 RFPosnLmpWorkCmd "Right front position lamp work command";
CM_ SG_ 743 LFPosnLmpWorkCmd "Left front position lamp work command";
CM_ SG_ 743 HiBeamWorkCmd "High Beam Command";
CM_ SG_ 743 LowBeamWorkCmd "Low Beam Command";
CM_ SG_ 743 RTurnLmpWorkCmd "Right turn lamp command request";
CM_ SG_ 743 LTurnLampWorkCmd "Left turn lamp command request";
CM_ SG_ 743 RDayRunngLmpWorkCmd "Right day run lamp work command";
CM_ SG_ 743 LDayRunngLmpWorkCmd "Left day run lamp work command";
CM_ SG_ 743 RFFogLmpWorkCmd "Right front fog lamp work command";
CM_ SG_ 743 LFFogLmpWorkCmd "Left front fog lamp work command";
CM_ SG_ 743 LicPlateLmpWorkCmd "License plate lamp work command";
CM_ SG_ 743 ReversLampWorkCmd "Revers Lamp Work  command";
CM_ SG_ 743 BrkLmpWorkCmd "Brake Lamp Work command";
CM_ SG_ 743 RFogLmpWorkCmd "rear  fog lamp work command";
CM_ SG_ 743 RRPosnLmpWorkCmd "Right rear position lamp work command";
CM_ SG_ 743 LRPosnLmpWorkCmd "Left rear position lamp work command";
CM_ SG_ 788 HCU_ACLineDisconnect "AC Line Disconnect";
CM_ SG_ 788 HCU_ChargSts "Charging  statue  displayIPHUT Received";
CM_ SG_ 788 HCU_IntelBattTempMagSts "Intelligent Battery Temperature Management stateSC_CAN:To HUT";
CM_ SG_ 790 OBC_ModSts "mode status of charger";
CM_ SG_ 791 OBC_ConnectSts "OBC charge connect statusIP Received";
CM_ SG_ 829 T_BOX_RemtLRTempSet "Remote Left  Rear side temperature setBD1_CAN:To AC";
CM_ SG_ 829 T_BOX_RemtRRTempSet "Remote  Right Rear side temperature set";
CM_ SG_ 829 T_BOX_RemtRearAutoCtrl "Remote Rear auto mode controlBD1_CAN:To AC";
CM_ SG_ 829 T_BOX_RemtSecRowLeSeatVentnLvlSe "Remote second row left seat ventilation set";
CM_ SG_ 829 T_BOX_RemtSecRowRiSeatVentnLvlSe "Remote second row right seat ventilation set";
CM_ SG_ 829 T_BOX_MbrMonrEnReq "Member monitoring enable request from TBOX";
CM_ SG_ 829 ReleAlarm_APP "Relieve  alarm form app";
CM_ SG_ 829 T_BOX_RemtSteerWheelHeatCtrl "Remote  Steer Wheel Heat ControlBD1-CAN To:CSA";
CM_ SG_ 829 T_BOX_AVPActvReq "T_BOX AVP Active RequestADAS_CAN:To IDC1.5";
CM_ SG_ 850 BMS_IntelEngIdlChrgnSts "Intelligent Engine Idle Charging statusSC_CAN:To HUT";
CM_ SG_ 850 BMS_BattKeepTempSts "Battery Keep Temperature stateSC_CAN:To HUT";
CM_ SG_ 865 HCU_HVILSts "Hcu HVIL(High voltage interaction loop) statusTSP signal";
CM_ SG_ 865 HCU_BMSSleepCmd "sleep command during power down processTSP signal";
CM_ SG_ 865 HCU_P2MActHvDcCurr_RM "Actual HV DC(High Voltage Direct Current link) Current of P2MTSP signal";
CM_ SG_ 865 HCU_P2MActHvDcVolt_RM "Actual HV DC(High Voltage Direct Current) voltage of P2MTSP signal";
CM_ SG_ 865 HCU_DTCNumber1 "HCU DTC number";
CM_ SG_ 865 HCU_DTCNumber2 "HCU DTC number";
CM_ SG_ 865 HCU_MotorAmount_RM "Actual amount of E-motor for  remote monitorTSP signal";
CM_ SG_ 909 HCU_PowertrainSts_RM "Powertrain Status.";
CM_ SG_ 909 HCU_BrkPowflag_RM "Brake Power flag to Tbox";
CM_ SG_ 909 HCU_ChargSts_RM "Charging  statue";
CM_ SG_ 909 HCU_PTDrvMod_RM "Powertrain current drive mode";
CM_ SG_ 909 HCU_Powerflag_RM "Power flag";
CM_ SG_ 909 HCU_AccelPedalPosn_Diag_RM "Physical acceleration pedal position.
it represents the physical value of acceleration pedal even in CCACC case, in which case normal acceleration pedal is replaced by virtual pedal position.";
CM_ SG_ 909 HCU_BrkPedalSts_RM "indicates the brake pedal is pressed or not or incorrect for
plausibility check.";
CM_ SG_ 909 HCU_WakeUpSrc "the wake up source of power up";
CM_ SG_ 909 HCU_CurrHybSysSts "Current vehicle hybrid system status";
CM_ SG_ 937 BMS_ISC_ROhm_Warn "Battery Internal short circuit of resistance";
CM_ SG_ 937 BMS_ISC_SOC_Warn "Battery Internal short circuit of SOC";
CM_ SG_ 937 BMS_ISC_T_Warn "Battery Internal short circuit of Temperature";
CM_ SG_ 937 BMS_ISC_V_Warn "Battery Internal short circuit of Voltage";
CM_ SG_ 942 BMS_SocJumpWarn_RM "BMS_SocJumpWarn Rank";
CM_ SG_ 942 BMS_PackOverChrgWarn_RM "BMS_Pack Over Charge warning Rank";
CM_ SG_ 942 BMS_ChrgSts_RM "BMS Charge status";
CM_ SG_ 942 BMS_IsolationRValue_RM "Isolation resistance value";
CM_ SG_ 942 BMS_PackCurr_RM "Pack Current";
CM_ SG_ 942 BMS_SocOverWarn_RM "BMS_Soc over warning Rank";
CM_ SG_ 942 BMS_BattOverTempRank_RM "battery temperature is too higher";
CM_ SG_ 942 BMS_BattOverVoltRank_RM "battery pack over voltage Rank";
CM_ SG_ 942 BMS_BattSOCLowRank_RM "SOC low Rank";
CM_ SG_ 942 BMS_VCUIsolateErr_RM "BMS_VCU Isolate  Error";
CM_ SG_ 942 BMS_BattUnderVoltRank_RM "battery pack under voltage Rank";
CM_ SG_ 942 BMS_CellDeltaVoltRank_RM "cell delta voltage Rank";
CM_ SG_ 942 BMS_CellOverVoltRank_RM "cell over voltage Rank";
CM_ SG_ 942 BMS_CellUnderVoltRank_RM "cell under voltage Rank";
CM_ SG_ 942 BMS_DeltaTempRank_RM "delta temperature Rank";
CM_ SG_ 942 BMS_PackMismatchWarn_RM "BMS_Pack Mismatchwarning Rank";
CM_ SG_ 942 BMS_PackVolt_RM "Pack Voltage";
CM_ SG_ 957 DCDC_Tempwarning_RM "DCDC temperapure warning for  remote monitor";
CM_ SG_ 957 DCDC_ActSts_RM "DCDC states";
CM_ SG_ 957 DCDC_FailStswarning_RM "DCDC state warning for  remote monitor";
CM_ SG_ 959 BMS_ChrgDurationTime "Charge Duration Time in minute";
CM_ SG_ 963 P2M_MotorSerNumber_RM "Actual serial number of E-motor for  remote monitor";
CM_ SG_ 963 P2M_InvActTemp_RM "Actual Virtual Junction Temperature state of hottest Inverter Power-Semiconductor";
CM_ SG_ 963 P2M_ActSpd_RM "Actual mechanical speed of EM(Electric Motor)";
CM_ SG_ 963 P2M_ActTrq_RM "Actual torque at EM(Electric Motor)   shaft";
CM_ SG_ 967 P2M_ActTemp_RM "Actual Temperature of hottest sensor element in EM(Electric Motor)  Winding";
CM_ SG_ 967 P2M_OperMode_RM "Actual operation mode of Actuation Motor";
CM_ SG_ 967 P2M_InvTempwarning_RM "Actual Temperature warrning of hottest sensor element in EM Inverter(Electric Motor)  Winding";
CM_ SG_ 967 P2M_Tempwarning_RM "Actual Temperature warrning of hottest sensor element in EM(Electric Motor)  Winding";
CM_ SG_ 976 BMS_BattTempMax "Battery max temperature of module temperature";
CM_ SG_ 976 BMS_BattTempMin "Battery min temperature of module temperature";
CM_ SG_ 977 BMS_SingleCellVolt_1 "Single cell vlotage of power battery1";
CM_ SG_ 977 BMS_SingleCellVolt_2 "Single cell vlotage of power battery2";
CM_ SG_ 977 BMS_SingleCellVolt_3 "Single cell vlotage of power battery3";
CM_ SG_ 977 BMS_SingleCellVolt_4 "Single cell vlotage of power battery4";
CM_ SG_ 977 BMS_SingleCellVolt_5 "Single cell vlotage of power battery5";
CM_ SG_ 977 BMS_SingleCellVolt_6 "Single cell vlotage of power battery6";
CM_ SG_ 977 BMS_SingleCellVolt_7 "Single cell vlotage of power battery7";
CM_ SG_ 977 BMS_SingleCellVolt_8 "Single cell vlotage of power battery8";
CM_ SG_ 977 BMS_SingleCellVolt_9 "Single cell vlotage of power battery9";
CM_ SG_ 977 BMS_SingleCellVolt_10 "Single cell vlotage of power battery10";
CM_ SG_ 977 BMS_SingleCellVolt_11 "Single cell vlotage of power battery11";
CM_ SG_ 977 BMS_SingleCellVolt_12 "Single cell vlotage of power battery12";
CM_ SG_ 977 BMS_BattModuleTe_11 "module temperature of power battery_1";
CM_ SG_ 977 BMS_BattModuleTe_12 "module temperature of power battery_1";
CM_ SG_ 977 BMS_BattModuleTe_21 "module temperature of power battery_2";
CM_ SG_ 977 BMS_BattModuleTe_22 "module temperature of power battery_2";
CM_ SG_ 977 BMS_BattModuleTe_31 "module temperature of power battery_3";
CM_ SG_ 977 BMS_BattModuleTe_32 "module temperature of power battery_3";
CM_ SG_ 977 BMS_BattModuleTe_41 "module temperature of power battery_4";
CM_ SG_ 977 BMS_BattModuleTe_42 "module temperature of power battery_4";
CM_ SG_ 977 BMS_BattModuleTe_51 "module temperature of power battery_5";
CM_ SG_ 977 BMS_BattModuleTe_52 "module temperature of power battery_5";
CM_ SG_ 977 BMS_BattModuleTe_61 "module temperature of power battery_6";
CM_ SG_ 977 BMS_BattModuleTe_62 "module temperature of power battery_6";
CM_ SG_ 977 BMS_BattModuleTe_71 "module temperature of power battery_7";
CM_ SG_ 977 BMS_BattModuleTe_72 "module temperature of power battery_7";
CM_ SG_ 977 BMS_BattModuleTe_81 "module temperature of power battery_8";
CM_ SG_ 977 BMS_BattModuleTe_82 "module temperature of power battery_8";
CM_ SG_ 978 BMS_SingleCellVolt_13 "Single cell vlotage of power battery13";
CM_ SG_ 978 BMS_SingleCellVolt_14 "Single cell vlotage of power battery14";
CM_ SG_ 978 BMS_SingleCellVolt_15 "Single cell vlotage of power battery15";
CM_ SG_ 978 BMS_SingleCellVolt_16 "Single cell vlotage of power battery16";
CM_ SG_ 978 BMS_SingleCellVolt_17 "Single cell vlotage of power battery17";
CM_ SG_ 978 BMS_SingleCellVolt_18 "Single cell vlotage of power battery18";
CM_ SG_ 978 BMS_SingleCellVolt_19 "Single cell vlotage of power battery19";
CM_ SG_ 978 BMS_SingleCellVolt_20 "Single cell vlotage of power battery20";
CM_ SG_ 978 BMS_SingleCellVolt_21 "Single cell vlotage of power battery21";
CM_ SG_ 978 BMS_SingleCellVolt_22 "Single cell vlotage of power battery22";
CM_ SG_ 978 BMS_SingleCellVolt_23 "Single cell vlotage of power battery23";
CM_ SG_ 978 BMS_SingleCellVolt_24 "Single cell vlotage of power battery24";
CM_ SG_ 978 BMS_SingleCellVolt_25 "Single cell vlotage of power battery25";
CM_ SG_ 978 BMS_SingleCellVolt_26 "Single cell vlotage of power battery26";
CM_ SG_ 978 BMS_SingleCellVolt_27 "Single cell vlotage of power battery27";
CM_ SG_ 978 BMS_SingleCellVolt_28 "Single cell vlotage of power battery28";
CM_ SG_ 978 BMS_SingleCellVolt_29 "Single cell vlotage of power battery29";
CM_ SG_ 978 BMS_SingleCellVolt_30 "Single cell vlotage of power battery30";
CM_ SG_ 978 BMS_SingleCellVolt_31 "Single cell vlotage of power battery31";
CM_ SG_ 978 BMS_SingleCellVolt_32 "Single cell vlotage of power battery32";
CM_ SG_ 978 BMS_SingleCellVolt_33 "Single cell vlotage of power battery33";
CM_ SG_ 978 BMS_SingleCellVolt_34 "Single cell vlotage of power battery34";
CM_ SG_ 978 BMS_SingleCellVolt_35 "Single cell vlotage of power battery35";
CM_ SG_ 978 BMS_SingleCellVolt_36 "Single cell vlotage of power battery36";
CM_ SG_ 978 BMS_SingleCellVolt_37 "Single cell vlotage of power battery37";
CM_ SG_ 978 BMS_SingleCellVolt_38 "Single cell vlotage of power battery38";
CM_ SG_ 978 BMS_SingleCellVolt_39 "Single cell vlotage of power battery39";
CM_ SG_ 978 BMS_SingleCellVolt_40 "Single cell vlotage of power battery40";
CM_ SG_ 979 BMS_SingleCellVolt_41 "Single cell vlotage of power battery41";
CM_ SG_ 979 BMS_SingleCellVolt_42 "Single cell vlotage of power battery42";
CM_ SG_ 979 BMS_SingleCellVolt_43 "Single cell vlotage of power battery43";
CM_ SG_ 979 BMS_SingleCellVolt_44 "Single cell vlotage of power battery44";
CM_ SG_ 979 BMS_SingleCellVolt_45 "Single cell vlotage of power battery45";
CM_ SG_ 979 BMS_SingleCellVolt_46 "Single cell vlotage of power battery46";
CM_ SG_ 979 BMS_SingleCellVolt_47 "Single cell vlotage of power battery47";
CM_ SG_ 979 BMS_SingleCellVolt_48 "Single cell vlotage of power battery48";
CM_ SG_ 979 BMS_SingleCellVolt_49 "Single cell vlotage of power battery49";
CM_ SG_ 979 BMS_SingleCellVolt_50 "Single cell vlotage of power battery50";
CM_ SG_ 979 BMS_SingleCellVolt_51 "Single cell vlotage of power battery51";
CM_ SG_ 979 BMS_SingleCellVolt_52 "Single cell vlotage of power battery52";
CM_ SG_ 979 BMS_SingleCellVolt_53 "Single cell vlotage of power battery53";
CM_ SG_ 979 BMS_SingleCellVolt_54 "Single cell vlotage of power battery54";
CM_ SG_ 979 BMS_SingleCellVolt_55 "Single cell vlotage of power battery55";
CM_ SG_ 979 BMS_SingleCellVolt_56 "Single cell vlotage of power battery56";
CM_ SG_ 979 BMS_SingleCellVolt_57 "Single cell vlotage of power battery57";
CM_ SG_ 979 BMS_SingleCellVolt_58 "Single cell vlotage of power battery58";
CM_ SG_ 979 BMS_SingleCellVolt_59 "Single cell vlotage of power battery59";
CM_ SG_ 979 BMS_SingleCellVolt_60 "Single cell vlotage of power battery60";
CM_ SG_ 979 BMS_SingleCellVolt_61 "Single cell vlotage of power battery61";
CM_ SG_ 979 BMS_SingleCellVolt_62 "Single cell vlotage of power battery62";
CM_ SG_ 979 BMS_SingleCellVolt_63 "Single cell vlotage of power battery63";
CM_ SG_ 979 BMS_SingleCellVolt_64 "Single cell vlotage of power battery64";
CM_ SG_ 979 BMS_SingleCellVolt_65 "Single cell vlotage of power battery65";
CM_ SG_ 979 BMS_SingleCellVolt_66 "Single cell vlotage of power battery66";
CM_ SG_ 979 BMS_SingleCellVolt_67 "Single cell vlotage of power battery67";
CM_ SG_ 979 BMS_SingleCellVolt_68 "Single cell vlotage of power battery68";
CM_ SG_ 980 BMS_SingleCellVolt_69 "Single cell vlotage of power battery69";
CM_ SG_ 980 BMS_SingleCellVolt_70 "Single cell vlotage of power battery70";
CM_ SG_ 980 BMS_SingleCellVolt_71 "Single cell vlotage of power battery71";
CM_ SG_ 980 BMS_SingleCellVolt_72 "Single cell vlotage of power battery72";
CM_ SG_ 980 BMS_SingleCellVolt_73 "Single cell vlotage of power battery73";
CM_ SG_ 980 BMS_SingleCellVolt_74 "Single cell vlotage of power battery74";
CM_ SG_ 980 BMS_SingleCellVolt_75 "Single cell vlotage of power battery75";
CM_ SG_ 980 BMS_SingleCellVolt_76 "Single cell vlotage of power battery76";
CM_ SG_ 980 BMS_SingleCellVolt_77 "Single cell vlotage of power battery77";
CM_ SG_ 980 BMS_SingleCellVolt_78 "Single cell vlotage of power battery78";
CM_ SG_ 980 BMS_SingleCellVolt_79 "Single cell vlotage of power battery79";
CM_ SG_ 980 BMS_SingleCellVolt_80 "Single cell vlotage of power battery80";
CM_ SG_ 980 BMS_SingleCellVolt_81 "Single cell vlotage of power battery81";
CM_ SG_ 980 BMS_SingleCellVolt_82 "Single cell vlotage of power battery82";
CM_ SG_ 980 BMS_SingleCellVolt_83 "Single cell vlotage of power battery83";
CM_ SG_ 980 BMS_SingleCellVolt_84 "Single cell vlotage of power battery84";
CM_ SG_ 980 BMS_SingleCellVolt_85 "Single cell vlotage of power battery85";
CM_ SG_ 980 BMS_SingleCellVolt_86 "Single cell vlotage of power battery86";
CM_ SG_ 980 BMS_SingleCellVolt_87 "Single cell vlotage of power battery87";
CM_ SG_ 980 BMS_SingleCellVolt_88 "Single cell vlotage of power battery88";
CM_ SG_ 980 BMS_SingleCellVolt_89 "Single cell vlotage of power battery89";
CM_ SG_ 980 BMS_SingleCellVolt_90 "Single cell vlotage of power battery90";
CM_ SG_ 980 BMS_SingleCellVolt_91 "Single cell vlotage of power battery91";
CM_ SG_ 980 BMS_SingleCellVolt_92 "Single cell vlotage of power battery92";
CM_ SG_ 980 BMS_SingleCellVolt_93 "Single cell vlotage of power battery93";
CM_ SG_ 980 BMS_SingleCellVolt_94 "Single cell vlotage of power battery94";
CM_ SG_ 980 BMS_SingleCellVolt_95 "Single cell vlotage of power battery95";
CM_ SG_ 980 BMS_SingleCellVolt_96 "Single cell vlotage of power battery96";
CM_ SG_ 981 BMS_SingleCellVolt_97 "Single cell vlotage of power battery97";
CM_ SG_ 981 BMS_SingleCellVolt_98 "Single cell vlotage of power battery98";
CM_ SG_ 981 BMS_SingleCellVolt_99 "Single cell vlotage of power battery99";
CM_ SG_ 981 BMS_SingleCellVolt_100 "Single cell vlotage of power battery100";
CM_ SG_ 981 BMS_SingleCellVolt_101 "Single cell vlotage of power battery101";
CM_ SG_ 981 BMS_SingleCellVolt_102 "Single cell vlotage of power battery102";
CM_ SG_ 981 BMS_SingleCellVolt_103 "Single cell vlotage of power battery103";
CM_ SG_ 981 BMS_SingleCellVolt_104 "Single cell vlotage of power battery104";
CM_ SG_ 981 BMS_SingleCellVolt_105 "Single cell vlotage of power battery105";
CM_ SG_ 981 BMS_SingleCellVolt_106 "Single cell vlotage of power battery106";
CM_ SG_ 981 BMS_SingleCellVolt_107 "Single cell vlotage of power battery107";
CM_ SG_ 981 BMS_SingleCellVolt_108 "Single cell vlotage of power battery108";
CM_ SG_ 981 BMS_BattModuleTe_13 "module temperature of power battery_1";
CM_ SG_ 981 BMS_BattModuleTe_23 "module temperature of power battery_2";
CM_ SG_ 981 BMS_BattModuleTe_33 "module temperature of power battery_3";
CM_ SG_ 981 BMS_DTCNumber "BMS DTC Number
Ã§Â”ÂµÃ¦Â±Â Ã¤Â¸ÂŠÃ¦ÂŠÂ¥Ã§ÂšÂ„DTCÃ§ÂŠÂ¶Ã¦Â€Â";
CM_ SG_ 981 BMS_BattModuleTe_91 "module temperature of power battery_9";
CM_ SG_ 981 BMS_BattModuleTe_92 "module temperature of power battery_9";
CM_ SG_ 981 BMS_DTCNumber1 "BMS_DTCNumber1";
CM_ SG_ 981 BMS_DTCNumber2 "BMS_DTCNumber2";
CM_ SG_ 1009 BMS_SOCLowWarn "SOC is too low,need to charge,IP need light the lamp.IP receive";
CM_ SG_ 1009 BMS_CellUnderVolt "cell under voltage";
CM_ SG_ 1009 BMS_CellOverVolt "cell over voltage warning";
CM_ SG_ 1009 BMS_CellDeltaVolt "cell delta voltage is too larger";
CM_ SG_ 1009 BMS_BattUnderVolt "pack under voltage";
CM_ SG_ 1009 BMS_BattOverVolt "pack over voltage";
CM_ SG_ 1009 BMS_BattUnderTemp "battery temperature is too lower";
CM_ SG_ 1009 BMS_SOC_Plaucheck "Compared with last cycle SOC";
CM_ SG_ 1009 BMS_DeltaTemp "delta temperature is too big";
CM_ SG_ 1009 BMS_CANComErr "BMS CAN communication fault";
CM_ SG_ 1009 BMS_BattSOCLow "SOC is lower";
CM_ SG_ 1009 BMS_BattSOCTooLow "SOC is too lower";
CM_ SG_ 1009 BMS_BattSOCHigh "SOC is too higher";
CM_ SG_ 1009 BMS_ChrgnCurrLager "charging current is too larger";
CM_ SG_ 1009 BMS_DischrgnCurrLager "discharging current is too larger";
CM_ SG_ 1009 BMS_ModuleMismatchWarn "mismatch warning of module";
CM_ SG_ 1009 BMS_cohrnc "coherence of power battery is bad";
CM_ SG_ 1009 BMS_moduleNumber "number of module";
CM_ SG_ 1009 BMS_NumModuleTempSnsr "number of module temperature sensor";
CM_ SG_ 1009 BMS_NumCell "number of cell";
CM_ SG_ 1010 BMS_CellVoltMin "minimal voltage of cell";
CM_ SG_ 1010 BMS_NumberCellVoltMin "number of minimal voltage of cell";
CM_ SG_ 1010 BMS_CellMaxVolt "maximal voltage of cell";
CM_ SG_ 1010 BMS_NumberCellMaxVolt "number of maximal voltage of cell";
CM_ SG_ 1010 BMS_CellBalanceSts "cell balance state";
CM_ SG_ 1010 BMS_RlyCounterSts "BMS relay counter status";
CM_ SG_ 1010 BMS_SOH_R "SOH( resistance) value";
CM_ SG_ 1011 BMS_ModuleMinTemp "minimal temperature of module";
CM_ SG_ 1011 BMS_ModuleNumCellMinTemp "module number of minimal temperature of cell";
CM_ SG_ 1011 BMS_ModuleNumCellMaxTemp "module number of maximal temperature of cell";
CM_ SG_ 1011 BMS_ModuleMaxTemp "maximal temperature of module";
CM_ SG_ 1011 BMS_NumCellMinTemp "number of minimal temperature of Cell";
CM_ SG_ 1011 BMS_NumCellMaxTemp "number of maximal temperature of Cell";
CM_ SG_ 1011 BMS_PackMismatchWarn "Pack mismatch warning of module";
CM_ SG_ 1011 BMS_OverChargeErr "Battery over charging error";
CM_ SG_ 1011 BMS_IsolationErr "Isolation resistance error";
CM_ SG_ 1011 BMS_HVILErr "HVIL(High voltage interaction loop) error";
CM_ SG_ 1011 BMS_BattOverTempWarn "battery temperature is too higher";
CM_ SG_ 1011 BMS_ModuleNumberCellMinVolt "module number of minimal voltage of cell";
CM_ SG_ 1011 BMS_ModuleNumberCellMaxVolt "module number of minimal voltage of cell";
CM_ SG_ 130 NetEngTrq "Current engine flywheel torque.";
CM_ SG_ 130 DrvEngTrqReq "Torque request from ACCeleration pedal or from CCACC.
It is burning torque, without any torque limitation, without filtering, without  consideration of external intervention, with idle controller, no torque intervention, not minus engine loss.Sub_CAN:To HUD";
CM_ SG_ 132 HCU_RaceLaunchAvail_0x84 "HCU Race Launch Avail";
CM_ SG_ 132 HCU_RaceLaunchSts_0x84 "Race Launch function is active or deactivate";
CM_ SG_ 158 HCU_PowertrainSts_0x9e "Powertrain Status.";
CM_ SG_ 158 HCU_TotDrvReqPower_0x9e "total driver request PowerIP Received";
CM_ SG_ 158 TgtRcprtnTrqSts "Status of Target Recuperation torque of Generator";
CM_ SG_ 258 AccelPedlPosnDiagc "Physical acceleration pedal position.IP Received";
CM_ SG_ 335 BMS_BattSOC_P0 "Battery SOCIP Received";
CM_ SG_ 486 MultiColorNr1 "Multi color number1";
CM_ SG_ 486 MultiColorNr2 "Multi color number2";
CM_ SG_ 486 MultiColorNr3 "Multi color number3";
CM_ SG_ 486 MultiColorNr4 "Multi color number4";
CM_ SG_ 486 MultiColorNr5 "Multi color number5";
CM_ SG_ 486 MultiColorNr6 "Multi color number6";
CM_ SG_ 486 MultiColorNr7 "Multi color number7";
CM_ SG_ 486 MultiColorNr8 "Multi color number8";
CM_ SG_ 492 MultiColorNr9 "Multi color number9";
CM_ SG_ 492 MultiColorNr10 "Multi color number10";
CM_ SG_ 492 MultiColorNr11 "Multi color number11";
CM_ SG_ 492 MultiColorNr12 "Multi color number12";
CM_ SG_ 492 MultiColorNr13 "Multi color number13";
CM_ SG_ 492 MultiColorNr14 "Multi color number14";
CM_ SG_ 492 MultiColorNr15 "Multi color number15";
CM_ SG_ 492 MultiColorNr16 "Multi color number16";
CM_ SG_ 724 DPF_Warning "This signal is used for IP to dispalay the regeneration state of the DPF(Disel Particulate Filter).IP Received";
CM_ SG_ 724 WIFSensorFailSts "Fuel water box sensor failure statusIP Received";
CM_ SG_ 724 GlowPlugLmpCmd "Glow plug working statusIP Received";
CM_ SG_ 724 UreaLampCmd "This signal is a indicator to display the AUS system working stateIP Received";
CM_ SG_ 724 Urea_Level "This signal is a indicator to display the remain AUS solution in the tank. This signal is from ECU, and in ECU It is computed throuth the AUS tank volume and the signal from DCU.
The level display will be 0%Ã£Â€Â5%Ã£Â€Â10%Ã£Â€Â15%Ã£Â€Â20%Ã£Â€Â25%Ã£Â€Â30%Ã£Â€Â35%Ã£Â€Â40%Ã£Â€Â45%Ã£Â€Â50%Ã£Â€Â55%Ã£Â€Â60%Ã£Â€Â65%Ã£Â€Â70%Ã£Â€Â75%Ã£Â€Â80%Ã£Â€Â85%Ã£Â€Â90%Ã£Â€Â95%Ã£Â€Â100%IP Received";
CM_ SG_ 724 UreaRemainDist "This signal is used to display the estimated remain distance due to the Urea volume in tank.IP Received";
CM_ SG_ 724 SCRSysWarnDisplay "This signal is used to display the messages of SCR system failure mode,to inform the driver to operate in time to avold system damage and keep the vehicle performance.IP Received";
CM_ SG_ 724 WIFFullLmpCmd "Fuel water box statusIP Received";
CM_ SG_ 724 DPF_Activation "This signal is used for HUT to activate the regeneration keys of the DPF(Diesel Particulate Filter)";
CM_ SG_ 763 VMDR_TmpMonFctnSts "VMDR Temporary monitoring function status";
CM_ SG_ 763 VMDR_InitAlarmDlySetSts "VMDR Initial alarm delay set status";
CM_ SG_ 763 VMDR_FctnSts "VMDR Function status";
CM_ SG_ 848 EngOilLvlWrn "Engine oil  warning";
CM_ SG_ 848 EngOilLowPresWrn "Engine oil low pressure warning";
CM_ SG_ 848 EngOilPres "Engine oil pressure";
CM_ SG_ 848 EngOilTemp "Engine oil temperature";
BA_DEF_ BO_  "DiagRequest" ENUM  "No","Yes";
BA_DEF_ BO_  "DiagResponse" ENUM  "No","Yes";
BA_DEF_ BO_  "DiagState" ENUM  "No","Yes";
BA_DEF_ BO_  "GenMsgCycleTime" INT 0 65535;
BA_DEF_ BO_  "GenMsgCycleTimeFast" INT 0 65535;
BA_DEF_ BO_  "GenMsgILSupport" ENUM  "No","Yes";
BA_DEF_ BO_  "GenMsgNrOfRepetition" INT 0 65535;
BA_DEF_ BO_  "GenMsgSendType" ENUM  "Cyclic","CyclicAndSpontanX","Event";
BA_DEF_ BO_  "NmAsrMessage" ENUM  "No","Yes";
BA_DEF_ BO_  "OriginFrame" STRING ;
BA_DEF_ BO_  "SCP_AuthInfoTxLength" INT 0 512;
BA_DEF_ BO_  "SCP_DataId" INT 0 65535;
BA_DEF_ BO_  "SCP_FreshnessValueLength" INT 0 512;
BA_DEF_ BO_  "SCP_FreshnessValueTxLength" INT 0 512;
BA_DEF_ BO_  "SC_Message" ENUM  "NO","YES";
BA_DEF_ BO_  "VFrameFormat" ENUM  "StandardCAN","ExtendedCAN","reserved","reserved","reserved","reserved","reserved","reserved","reserved","reserved","reserved","reserved","reserved","reserved","StandardCAN_FD","ExtendedCAN_FD";
BA_DEF_ SG_  "GenSigCycleTime" INT 0 65535;
BA_DEF_ SG_  "GenSigSendType" ENUM  "Cyclic","OnWrite","OnWriteWithRepetition","OnChange","OnChangeWithRepetition","NotUsed","NotUsed","NoSigSendType";
BA_DEF_ SG_  "GenSigStartValue" FLOAT 0 100000000000;
BA_DEF_ SG_  "Match" STRING ;
BA_DEF_ SG_  "Origin" STRING ;
BA_DEF_ SG_  "TransparentInitValue" STRING ;
BA_DEF_ SG_  "SystemSignalLongSymbol" STRING ;
BA_DEF_DEF_  "DiagRequest" "No";
BA_DEF_DEF_  "DiagResponse" "No";
BA_DEF_DEF_  "DiagState" "No";
BA_DEF_DEF_  "GenMsgCycleTime" 0;
BA_DEF_DEF_  "GenMsgCycleTimeFast" 0;
BA_DEF_DEF_  "GenMsgILSupport" "No";
BA_DEF_DEF_  "GenMsgNrOfRepetition" 0;
BA_DEF_DEF_  "GenMsgSendType" "Cyclic";
BA_DEF_DEF_  "NmAsrMessage" "No";
BA_DEF_DEF_  "OriginFrame" "";
BA_DEF_DEF_  "SCP_AuthInfoTxLength" 0;
BA_DEF_DEF_  "SCP_DataId" 0;
BA_DEF_DEF_  "SCP_FreshnessValueLength" 0;
BA_DEF_DEF_  "SCP_FreshnessValueTxLength" 0;
BA_DEF_DEF_  "SC_Message" "NO";
BA_DEF_DEF_  "VFrameFormat" "";
BA_DEF_DEF_  "GenSigCycleTime" 0;
BA_DEF_DEF_  "GenSigSendType" "Cyclic";
BA_DEF_DEF_  "GenSigStartValue" 0;
BA_DEF_DEF_  "Match" "";
BA_DEF_DEF_  "Origin" "";
BA_DEF_DEF_  "TransparentInitValue" "";
BA_DEF_DEF_  "SystemSignalLongSymbol" "";
BA_ "OriginFrame" BO_ 482 "ev";
BA_ "GenMsgSendType" BO_ 482 2;
BA_ "GenMsgNrOfRepetition" BO_ 482 5;
BA_ "GenMsgILSupport" BO_ 482 1;
BA_ "GenMsgCycleTimeFast" BO_ 482 20;
BA_ "VFrameFormat" BO_ 482 14;
BA_ "OriginFrame" BO_ 483 "ev";
BA_ "GenMsgSendType" BO_ 483 2;
BA_ "GenMsgNrOfRepetition" BO_ 483 5;
BA_ "GenMsgILSupport" BO_ 483 1;
BA_ "GenMsgCycleTimeFast" BO_ 483 20;
BA_ "VFrameFormat" BO_ 483 14;
BA_ "OriginFrame" BO_ 510 "ev";
BA_ "GenMsgSendType" BO_ 510 2;
BA_ "GenMsgNrOfRepetition" BO_ 510 5;
BA_ "GenMsgILSupport" BO_ 510 1;
BA_ "GenMsgCycleTimeFast" BO_ 510 20;
BA_ "VFrameFormat" BO_ 510 14;
BA_ "OriginFrame" BO_ 513 "ev";
BA_ "GenMsgILSupport" BO_ 513 1;
BA_ "GenMsgCycleTime" BO_ 513 50;
BA_ "VFrameFormat" BO_ 513 14;
BA_ "OriginFrame" BO_ 515 "ev";
BA_ "GenMsgILSupport" BO_ 515 1;
BA_ "GenMsgCycleTime" BO_ 515 50;
BA_ "VFrameFormat" BO_ 515 14;
BA_ "OriginFrame" BO_ 616 "ev";
BA_ "GenMsgILSupport" BO_ 616 1;
BA_ "GenMsgCycleTime" BO_ 616 50;
BA_ "VFrameFormat" BO_ 616 14;
BA_ "OriginFrame" BO_ 645 "ev";
BA_ "GenMsgILSupport" BO_ 645 1;
BA_ "GenMsgCycleTime" BO_ 645 100;
BA_ "VFrameFormat" BO_ 645 14;
BA_ "OriginFrame" BO_ 690 "ev";
BA_ "GenMsgILSupport" BO_ 690 1;
BA_ "GenMsgCycleTime" BO_ 690 100;
BA_ "VFrameFormat" BO_ 690 14;
BA_ "OriginFrame" BO_ 708 "ev";
BA_ "GenMsgILSupport" BO_ 708 1;
BA_ "GenMsgCycleTime" BO_ 708 100;
BA_ "VFrameFormat" BO_ 708 14;
BA_ "OriginFrame" BO_ 743 "ev";
BA_ "GenMsgILSupport" BO_ 743 1;
BA_ "GenMsgCycleTime" BO_ 743 50;
BA_ "VFrameFormat" BO_ 743 14;
BA_ "OriginFrame" BO_ 788 "ev";
BA_ "GenMsgILSupport" BO_ 788 1;
BA_ "GenMsgCycleTime" BO_ 788 200;
BA_ "VFrameFormat" BO_ 788 14;
BA_ "OriginFrame" BO_ 790 "ev";
BA_ "GenMsgILSupport" BO_ 790 1;
BA_ "GenMsgCycleTime" BO_ 790 200;
BA_ "VFrameFormat" BO_ 790 14;
BA_ "OriginFrame" BO_ 791 "ev";
BA_ "GenMsgILSupport" BO_ 791 1;
BA_ "GenMsgCycleTime" BO_ 791 200;
BA_ "VFrameFormat" BO_ 791 14;
BA_ "OriginFrame" BO_ 829 "ev";
BA_ "GenMsgSendType" BO_ 829 2;
BA_ "GenMsgNrOfRepetition" BO_ 829 5;
BA_ "GenMsgILSupport" BO_ 829 1;
BA_ "GenMsgCycleTimeFast" BO_ 829 20;
BA_ "VFrameFormat" BO_ 829 14;
BA_ "OriginFrame" BO_ 850 "ev";
BA_ "GenMsgILSupport" BO_ 850 1;
BA_ "GenMsgCycleTime" BO_ 850 500;
BA_ "VFrameFormat" BO_ 850 14;
BA_ "OriginFrame" BO_ 865 "ev";
BA_ "GenMsgILSupport" BO_ 865 1;
BA_ "GenMsgCycleTime" BO_ 865 500;
BA_ "VFrameFormat" BO_ 865 14;
BA_ "OriginFrame" BO_ 909 "ev";
BA_ "GenMsgILSupport" BO_ 909 1;
BA_ "GenMsgCycleTime" BO_ 909 1000;
BA_ "VFrameFormat" BO_ 909 14;
BA_ "OriginFrame" BO_ 937 "ev";
BA_ "GenMsgILSupport" BO_ 937 1;
BA_ "GenMsgCycleTime" BO_ 937 1000;
BA_ "VFrameFormat" BO_ 937 14;
BA_ "OriginFrame" BO_ 942 "ev";
BA_ "GenMsgILSupport" BO_ 942 1;
BA_ "GenMsgCycleTime" BO_ 942 1000;
BA_ "VFrameFormat" BO_ 942 14;
BA_ "OriginFrame" BO_ 957 "ev";
BA_ "GenMsgILSupport" BO_ 957 1;
BA_ "GenMsgCycleTime" BO_ 957 1000;
BA_ "VFrameFormat" BO_ 957 14;
BA_ "OriginFrame" BO_ 959 "ev";
BA_ "GenMsgILSupport" BO_ 959 1;
BA_ "GenMsgCycleTime" BO_ 959 1000;
BA_ "VFrameFormat" BO_ 959 14;
BA_ "OriginFrame" BO_ 963 "ev";
BA_ "GenMsgILSupport" BO_ 963 1;
BA_ "GenMsgCycleTime" BO_ 963 1000;
BA_ "VFrameFormat" BO_ 963 14;
BA_ "OriginFrame" BO_ 967 "ev";
BA_ "GenMsgILSupport" BO_ 967 1;
BA_ "GenMsgCycleTime" BO_ 967 1000;
BA_ "VFrameFormat" BO_ 967 14;
BA_ "OriginFrame" BO_ 976 "ev";
BA_ "GenMsgILSupport" BO_ 976 1;
BA_ "GenMsgCycleTime" BO_ 976 1000;
BA_ "VFrameFormat" BO_ 976 14;
BA_ "OriginFrame" BO_ 977 "ev";
BA_ "GenMsgILSupport" BO_ 977 1;
BA_ "GenMsgCycleTime" BO_ 977 1000;
BA_ "VFrameFormat" BO_ 977 14;
BA_ "OriginFrame" BO_ 978 "ev";
BA_ "GenMsgILSupport" BO_ 978 1;
BA_ "GenMsgCycleTime" BO_ 978 1000;
BA_ "VFrameFormat" BO_ 978 14;
BA_ "OriginFrame" BO_ 979 "ev";
BA_ "GenMsgILSupport" BO_ 979 1;
BA_ "GenMsgCycleTime" BO_ 979 1000;
BA_ "VFrameFormat" BO_ 979 14;
BA_ "OriginFrame" BO_ 980 "ev";
BA_ "GenMsgILSupport" BO_ 980 1;
BA_ "GenMsgCycleTime" BO_ 980 1000;
BA_ "VFrameFormat" BO_ 980 14;
BA_ "OriginFrame" BO_ 981 "ev";
BA_ "GenMsgILSupport" BO_ 981 1;
BA_ "GenMsgCycleTime" BO_ 981 1000;
BA_ "VFrameFormat" BO_ 981 14;
BA_ "OriginFrame" BO_ 1009 "ev";
BA_ "GenMsgILSupport" BO_ 1009 1;
BA_ "GenMsgCycleTime" BO_ 1009 1000;
BA_ "VFrameFormat" BO_ 1009 14;
BA_ "OriginFrame" BO_ 1010 "ev";
BA_ "GenMsgILSupport" BO_ 1010 1;
BA_ "GenMsgCycleTime" BO_ 1010 1000;
BA_ "VFrameFormat" BO_ 1010 14;
BA_ "OriginFrame" BO_ 1011 "ev";
BA_ "GenMsgILSupport" BO_ 1011 1;
BA_ "GenMsgCycleTime" BO_ 1011 1000;
BA_ "VFrameFormat" BO_ 1011 14;
BA_ "OriginFrame" BO_ 130 "fuel";
BA_ "GenMsgILSupport" BO_ 130 1;
BA_ "GenMsgCycleTime" BO_ 130 10;
BA_ "VFrameFormat" BO_ 130 14;
BA_ "OriginFrame" BO_ 132 "fuel";
BA_ "GenMsgILSupport" BO_ 132 1;
BA_ "GenMsgCycleTime" BO_ 132 10;
BA_ "VFrameFormat" BO_ 132 14;
BA_ "OriginFrame" BO_ 158 "fuel";
BA_ "GenMsgILSupport" BO_ 158 1;
BA_ "GenMsgCycleTime" BO_ 158 10;
BA_ "VFrameFormat" BO_ 158 14;
BA_ "OriginFrame" BO_ 258 "fuel";
BA_ "GenMsgILSupport" BO_ 258 1;
BA_ "GenMsgCycleTime" BO_ 258 20;
BA_ "VFrameFormat" BO_ 258 14;
BA_ "OriginFrame" BO_ 335 "fuel";
BA_ "GenMsgILSupport" BO_ 335 1;
BA_ "GenMsgCycleTime" BO_ 335 20;
BA_ "VFrameFormat" BO_ 335 14;
BA_ "OriginFrame" BO_ 486 "fuel";
BA_ "GenMsgSendType" BO_ 486 2;
BA_ "GenMsgNrOfRepetition" BO_ 486 5;
BA_ "GenMsgILSupport" BO_ 486 1;
BA_ "GenMsgCycleTimeFast" BO_ 486 50;
BA_ "VFrameFormat" BO_ 486 14;
BA_ "OriginFrame" BO_ 492 "fuel";
BA_ "GenMsgSendType" BO_ 492 2;
BA_ "GenMsgNrOfRepetition" BO_ 492 5;
BA_ "GenMsgILSupport" BO_ 492 1;
BA_ "GenMsgCycleTimeFast" BO_ 492 50;
BA_ "VFrameFormat" BO_ 492 14;
BA_ "OriginFrame" BO_ 724 "fuel";
BA_ "GenMsgILSupport" BO_ 724 1;
BA_ "GenMsgCycleTime" BO_ 724 100;
BA_ "VFrameFormat" BO_ 724 14;
BA_ "OriginFrame" BO_ 763 "fuel";
BA_ "GenMsgILSupport" BO_ 763 1;
BA_ "GenMsgCycleTime" BO_ 763 100;
BA_ "VFrameFormat" BO_ 763 14;
BA_ "OriginFrame" BO_ 848 "fuel";
BA_ "GenMsgILSupport" BO_ 848 1;
BA_ "GenMsgCycleTime" BO_ 848 500;
BA_ "VFrameFormat" BO_ 848 14;
BA_ "OriginFrame" BO_ 1560 "fuel";
BA_ "GenMsgSendType" BO_ 1560 2;
BA_ "DiagRequest" BO_ 1560 1;
BA_ "VFrameFormat" BO_ 1560 14;
BA_ "OriginFrame" BO_ 1561 "fuel";
BA_ "GenMsgSendType" BO_ 1561 2;
BA_ "DiagResponse" BO_ 1561 1;
BA_ "VFrameFormat" BO_ 1561 14;
BA_ "VFrameFormat" BO_ 1303 0;
BA_ "OriginFrame" BO_ 1303 "fuel";
BA_ "NmAsrMessage" BO_ 1303 1;
BA_ "GenMsgSendType" BO_ 1303 2;
BA_ "Origin" SG_ 482 HCU_PhoneChrgnModeResp "ev";
BA_ "Match" SG_ 482 HCU_PhoneChrgnModeResp "HCU_PhoneChrgnModeResp";
BA_ "GenSigSendType" SG_ 482 HCU_PhoneChrgnModeResp 2;
BA_ "Origin" SG_ 482 HCU_PhoneChrgnReqResp "ev";
BA_ "Match" SG_ 482 HCU_PhoneChrgnReqResp "HCU_PhoneChrgnReqResp";
BA_ "GenSigSendType" SG_ 482 HCU_PhoneChrgnReqResp 2;
BA_ "Origin" SG_ 482 HCU_HUTChrgnModeResp "ev";
BA_ "Match" SG_ 482 HCU_HUTChrgnModeResp "HCU_HUTChrgnModeResp";
BA_ "GenSigSendType" SG_ 482 HCU_HUTChrgnModeResp 2;
BA_ "Origin" SG_ 482 HCU_HUTChrgnReqResp "ev";
BA_ "Match" SG_ 482 HCU_HUTChrgnReqResp "HCU_HUTChrgnReqResp";
BA_ "GenSigSendType" SG_ 482 HCU_HUTChrgnReqResp 2;
BA_ "Origin" SG_ 482 HCU_TboxEngStrtReq "ev";
BA_ "Match" SG_ 482 HCU_TboxEngStrtReq "HCU_TboxEngStrtReq";
BA_ "GenSigSendType" SG_ 482 HCU_TboxEngStrtReq 2;
BA_ "Origin" SG_ 482 HCU_TotalScore "ev";
BA_ "Match" SG_ 482 HCU_TotalScore "HCU_TotalScore";
BA_ "GenSigSendType" SG_ 482 HCU_TotalScore 2;
BA_ "TransparentInitValue" SG_ 482 HCU_HC8_0x1E2 "0 0 0 0 0 0 0 0 ";
BA_ "GenSigSendType" SG_ 482 HCU_HC8_0x1E2 2;
BA_ "Origin" SG_ 483 BMS_ChrgTimResp "ev";
BA_ "Match" SG_ 483 BMS_ChrgTimResp "BMS_ChrgTimResp";
BA_ "GenSigSendType" SG_ 483 BMS_ChrgTimResp 2;
BA_ "TransparentInitValue" SG_ 483 BMS_FD14_0x1E3 "0 0 0 0 0 0 0 0 ";
BA_ "GenSigSendType" SG_ 483 BMS_FD14_0x1E3 2;
BA_ "Origin" SG_ 510 T_BOX_RemtDrvSeatHeatgLvlSet_Nin "ev";
BA_ "Match" SG_ 510 T_BOX_RemtDrvSeatHeatgLvlSet_Nin "T_BOX_RemtDrvSeatHeatgLvlSet_Nine";
BA_ "GenSigSendType" SG_ 510 T_BOX_RemtDrvSeatHeatgLvlSet_Nin 2;
BA_ "SystemSignalLongSymbol" SG_ 510 T_BOX_RemtDrvSeatHeatgLvlSet_Nin "T_BOX_RemtDrvSeatHeatgLvlSet_Nine";
BA_ "Origin" SG_ 510 T_BOX_RemtPassSeatHeatgLvlSet_Ni "ev";
BA_ "Match" SG_ 510 T_BOX_RemtPassSeatHeatgLvlSet_Ni "T_BOX_RemtPassSeatHeatgLvlSet_Nine";
BA_ "GenSigSendType" SG_ 510 T_BOX_RemtPassSeatHeatgLvlSet_Ni 2;
BA_ "SystemSignalLongSymbol" SG_ 510 T_BOX_RemtPassSeatHeatgLvlSet_Ni "T_BOX_RemtPassSeatHeatgLvlSet_Nine";
BA_ "Origin" SG_ 510 T_BOX_RemtSecRowLeSeatHeatgLvlSe "ev";
BA_ "Match" SG_ 510 T_BOX_RemtSecRowLeSeatHeatgLvlSe "T_BOX_RemtSecRowLeSeatHeatgLvlSet_Nine";
BA_ "GenSigSendType" SG_ 510 T_BOX_RemtSecRowLeSeatHeatgLvlSe 2;
BA_ "SystemSignalLongSymbol" SG_ 510 T_BOX_RemtSecRowLeSeatHeatgLvlSe "T_BOX_RemtSecRowLeSeatHeatgLvlSet_Nine";
BA_ "Origin" SG_ 510 T_BOX_RemtSecRowRiSeatHeatgLvlSe "ev";
BA_ "Match" SG_ 510 T_BOX_RemtSecRowRiSeatHeatgLvlSe "T_BOX_RemtSecRowRiSeatHeatgLvlSet_Nine";
BA_ "GenSigSendType" SG_ 510 T_BOX_RemtSecRowRiSeatHeatgLvlSe 2;
BA_ "SystemSignalLongSymbol" SG_ 510 T_BOX_RemtSecRowRiSeatHeatgLvlSe "T_BOX_RemtSecRowRiSeatHeatgLvlSet_Nine";
BA_ "Origin" SG_ 510 T_BOX_ChrgTim_Hour "ev";
BA_ "Match" SG_ 510 T_BOX_ChrgTim_Hour "T_BOX_ChrgTim_Hour";
BA_ "GenSigStartValue" SG_ 510 T_BOX_ChrgTim_Hour 31;
BA_ "GenSigSendType" SG_ 510 T_BOX_ChrgTim_Hour 2;
BA_ "Origin" SG_ 510 T_BOX_ChrgTim_Minutes "ev";
BA_ "Match" SG_ 510 T_BOX_ChrgTim_Minutes "T_BOX_ChrgTim_Minutes";
BA_ "GenSigStartValue" SG_ 510 T_BOX_ChrgTim_Minutes 63;
BA_ "GenSigSendType" SG_ 510 T_BOX_ChrgTim_Minutes 2;
BA_ "Origin" SG_ 510 T_BOX_ChrgTim_Second "ev";
BA_ "Match" SG_ 510 T_BOX_ChrgTim_Second "T_BOX_ChrgTim_Second";
BA_ "GenSigStartValue" SG_ 510 T_BOX_ChrgTim_Second 63;
BA_ "GenSigSendType" SG_ 510 T_BOX_ChrgTim_Second 2;
BA_ "Origin" SG_ 510 T_BOX_ChrgTim_Year_Left "ev";
BA_ "Match" SG_ 510 T_BOX_ChrgTim_Year_Left "T_BOX_ChrgTim_Year_Left";
BA_ "GenSigStartValue" SG_ 510 T_BOX_ChrgTim_Year_Left 15;
BA_ "GenSigSendType" SG_ 510 T_BOX_ChrgTim_Year_Left 2;
BA_ "Origin" SG_ 510 T_BOX_ChrgTim_Year_Right "ev";
BA_ "Match" SG_ 510 T_BOX_ChrgTim_Year_Right "T_BOX_ChrgTim_Year_Right";
BA_ "GenSigStartValue" SG_ 510 T_BOX_ChrgTim_Year_Right 15;
BA_ "GenSigSendType" SG_ 510 T_BOX_ChrgTim_Year_Right 2;
BA_ "Origin" SG_ 510 T_BOX_ChrgTim_Month "ev";
BA_ "Match" SG_ 510 T_BOX_ChrgTim_Month "T_BOX_ChrgTim_Month";
BA_ "GenSigSendType" SG_ 510 T_BOX_ChrgTim_Month 2;
BA_ "Origin" SG_ 510 T_BOX_ChrgTim_Day "ev";
BA_ "Match" SG_ 510 T_BOX_ChrgTim_Day "T_BOX_ChrgTim_Day";
BA_ "GenSigSendType" SG_ 510 T_BOX_ChrgTim_Day 2;
BA_ "TransparentInitValue" SG_ 510 T_BOX_FD9_0x1FE "0 0 0 255 255 255 128 0 ";
BA_ "GenSigSendType" SG_ 510 T_BOX_FD9_0x1FE 2;
BA_ "Origin" SG_ 513 HCU_V2LReminder "ev";
BA_ "Match" SG_ 513 HCU_V2LReminder "HCU_V2LReminder";
BA_ "GenSigCycleTime" SG_ 513 HCU_V2LReminder 50;
BA_ "Origin" SG_ 513 HCU_SOCMngmntSts "ev";
BA_ "Match" SG_ 513 HCU_SOCMngmntSts "HCU_SOCMngmntSts";
BA_ "GenSigCycleTime" SG_ 513 HCU_SOCMngmntSts 50;
BA_ "Origin" SG_ 513 HCU_ARFSts "ev";
BA_ "Match" SG_ 513 HCU_ARFSts "HCU_ARFSts";
BA_ "GenSigCycleTime" SG_ 513 HCU_ARFSts 50;
BA_ "Origin" SG_ 513 HCU_ASFCSts "ev";
BA_ "Match" SG_ 513 HCU_ASFCSts "HCU_ASFCSts";
BA_ "GenSigCycleTime" SG_ 513 HCU_ASFCSts 50;
BA_ "Origin" SG_ 513 HCU_AGSSts "ev";
BA_ "Match" SG_ 513 HCU_AGSSts "HCU_AGSSts";
BA_ "GenSigCycleTime" SG_ 513 HCU_AGSSts 50;
BA_ "Origin" SG_ 513 PDCU_AvailabilityOfARF "ev";
BA_ "Match" SG_ 513 PDCU_AvailabilityOfARF "PDCU_AvailabilityOfARF";
BA_ "GenSigCycleTime" SG_ 513 PDCU_AvailabilityOfARF 50;
BA_ "Origin" SG_ 513 PDCU_lossenPedalPrompt "ev";
BA_ "Match" SG_ 513 PDCU_lossenPedalPrompt "PDCU_lossenPedalPrompt";
BA_ "GenSigCycleTime" SG_ 513 PDCU_lossenPedalPrompt 50;
BA_ "Origin" SG_ 513 PDCU_EvSave_disl "ev";
BA_ "Match" SG_ 513 PDCU_EvSave_disl "PDCU_EvSave_disl";
BA_ "GenSigCycleTime" SG_ 513 PDCU_EvSave_disl 50;
BA_ "TransparentInitValue" SG_ 513 HCU_HP5_0x201 "0 0 0 0 0 0 0 0 ";
BA_ "GenSigCycleTime" SG_ 513 HCU_HP5_0x201 50;
BA_ "Origin" SG_ 515 HUT_OD_Obj0_ID "ev";
BA_ "Match" SG_ 515 HUT_OD_Obj0_ID "HUT_OD_Obj0_ID";
BA_ "GenSigCycleTime" SG_ 515 HUT_OD_Obj0_ID 50;
BA_ "Origin" SG_ 515 HUT_OD_Obj0_type "ev";
BA_ "Match" SG_ 515 HUT_OD_Obj0_type "HUT_OD_Obj0_type";
BA_ "GenSigCycleTime" SG_ 515 HUT_OD_Obj0_type 50;
BA_ "Origin" SG_ 515 HUT_OD_Obj0_Confidence "ev";
BA_ "Match" SG_ 515 HUT_OD_Obj0_Confidence "HUT_OD_Obj0_Confidence";
BA_ "GenSigCycleTime" SG_ 515 HUT_OD_Obj0_Confidence 50;
BA_ "Origin" SG_ 515 HUT_OD_Obj0_width "ev";
BA_ "Match" SG_ 515 HUT_OD_Obj0_width "HUT_OD_Obj0_width";
BA_ "GenSigCycleTime" SG_ 515 HUT_OD_Obj0_width 50;
BA_ "Origin" SG_ 515 HUT_OD_Obj0_Ground_Pos_X "ev";
BA_ "Match" SG_ 515 HUT_OD_Obj0_Ground_Pos_X "HUT_OD_Obj0_Ground_Pos_X";
BA_ "GenSigCycleTime" SG_ 515 HUT_OD_Obj0_Ground_Pos_X 50;
BA_ "Origin" SG_ 515 HUT_OD_Obj0_Ground_Pos_Y "ev";
BA_ "Match" SG_ 515 HUT_OD_Obj0_Ground_Pos_Y "HUT_OD_Obj0_Ground_Pos_Y";
BA_ "GenSigCycleTime" SG_ 515 HUT_OD_Obj0_Ground_Pos_Y 50;
BA_ "Origin" SG_ 515 HTU_OD_Obj1_ID "ev";
BA_ "Match" SG_ 515 HTU_OD_Obj1_ID "HTU_OD_Obj1_ID";
BA_ "GenSigCycleTime" SG_ 515 HTU_OD_Obj1_ID 50;
BA_ "Origin" SG_ 515 HUT_OD_Obj1_type "ev";
BA_ "Match" SG_ 515 HUT_OD_Obj1_type "HUT_OD_Obj1_type";
BA_ "GenSigCycleTime" SG_ 515 HUT_OD_Obj1_type 50;
BA_ "Origin" SG_ 515 HUT_OD_Obj1_Confidence "ev";
BA_ "Match" SG_ 515 HUT_OD_Obj1_Confidence "HUT_OD_Obj1_Confidence";
BA_ "GenSigCycleTime" SG_ 515 HUT_OD_Obj1_Confidence 50;
BA_ "Origin" SG_ 515 HUT_OD_Obj1_width "ev";
BA_ "Match" SG_ 515 HUT_OD_Obj1_width "HUT_OD_Obj1_width";
BA_ "GenSigCycleTime" SG_ 515 HUT_OD_Obj1_width 50;
BA_ "Origin" SG_ 515 HUT_OD_Obj1_Ground_Pos_X "ev";
BA_ "Match" SG_ 515 HUT_OD_Obj1_Ground_Pos_X "HUT_OD_Obj1_Ground_Pos_X";
BA_ "GenSigCycleTime" SG_ 515 HUT_OD_Obj1_Ground_Pos_X 50;
BA_ "Origin" SG_ 515 HUT_OD_Obj1_Ground_Pos_Y "ev";
BA_ "Match" SG_ 515 HUT_OD_Obj1_Ground_Pos_Y "HUT_OD_Obj1_Ground_Pos_Y";
BA_ "GenSigCycleTime" SG_ 515 HUT_OD_Obj1_Ground_Pos_Y 50;
BA_ "Origin" SG_ 515 HUT_OD_Obj2_ID "ev";
BA_ "Match" SG_ 515 HUT_OD_Obj2_ID "HUT_OD_Obj2_ID";
BA_ "GenSigCycleTime" SG_ 515 HUT_OD_Obj2_ID 50;
BA_ "Origin" SG_ 515 HUT_OD_Obj2_type "ev";
BA_ "Match" SG_ 515 HUT_OD_Obj2_type "HUT_OD_Obj2_type";
BA_ "GenSigCycleTime" SG_ 515 HUT_OD_Obj2_type 50;
BA_ "Origin" SG_ 515 HUT_OD_Obj2_Confidence "ev";
BA_ "Match" SG_ 515 HUT_OD_Obj2_Confidence "HUT_OD_Obj2_Confidence";
BA_ "GenSigCycleTime" SG_ 515 HUT_OD_Obj2_Confidence 50;
BA_ "Origin" SG_ 515 HUT_OD_Obj2_width "ev";
BA_ "Match" SG_ 515 HUT_OD_Obj2_width "HUT_OD_Obj2_width";
BA_ "GenSigCycleTime" SG_ 515 HUT_OD_Obj2_width 50;
BA_ "Origin" SG_ 515 HUT_OD_Obj2_Ground_Pos_X "ev";
BA_ "Match" SG_ 515 HUT_OD_Obj2_Ground_Pos_X "HUT_OD_Obj2_Ground_Pos_X";
BA_ "GenSigCycleTime" SG_ 515 HUT_OD_Obj2_Ground_Pos_X 50;
BA_ "Origin" SG_ 515 HUT_OD_Obj2_Ground_Pos_Y "ev";
BA_ "Match" SG_ 515 HUT_OD_Obj2_Ground_Pos_Y "HUT_OD_Obj2_Ground_Pos_Y";
BA_ "GenSigCycleTime" SG_ 515 HUT_OD_Obj2_Ground_Pos_Y 50;
BA_ "Origin" SG_ 515 HUT_OD_Obj3_ID "ev";
BA_ "Match" SG_ 515 HUT_OD_Obj3_ID "HUT_OD_Obj3_ID";
BA_ "GenSigCycleTime" SG_ 515 HUT_OD_Obj3_ID 50;
BA_ "Origin" SG_ 515 HUT_OD_Obj3_type "ev";
BA_ "Match" SG_ 515 HUT_OD_Obj3_type "HUT_OD_Obj3_type";
BA_ "GenSigCycleTime" SG_ 515 HUT_OD_Obj3_type 50;
BA_ "Origin" SG_ 515 HUT_OD_Obj3_Confidence "ev";
BA_ "Match" SG_ 515 HUT_OD_Obj3_Confidence "HUT_OD_Obj3_Confidence";
BA_ "GenSigCycleTime" SG_ 515 HUT_OD_Obj3_Confidence 50;
BA_ "Origin" SG_ 515 HUT_OD_Obj3_width "ev";
BA_ "Match" SG_ 515 HUT_OD_Obj3_width "HUT_OD_Obj3_width";
BA_ "GenSigCycleTime" SG_ 515 HUT_OD_Obj3_width 50;
BA_ "Origin" SG_ 515 HUT_OD_Obj3_Ground_Pos_X "ev";
BA_ "Match" SG_ 515 HUT_OD_Obj3_Ground_Pos_X "HUT_OD_Obj3_Ground_Pos_X";
BA_ "GenSigCycleTime" SG_ 515 HUT_OD_Obj3_Ground_Pos_X 50;
BA_ "Origin" SG_ 515 HUT_OD_Obj3_Ground_Pos_Y "ev";
BA_ "Match" SG_ 515 HUT_OD_Obj3_Ground_Pos_Y "HUT_OD_Obj3_Ground_Pos_Y";
BA_ "GenSigCycleTime" SG_ 515 HUT_OD_Obj3_Ground_Pos_Y 50;
BA_ "Origin" SG_ 515 HUT_OD_Obj4_ID "ev";
BA_ "Match" SG_ 515 HUT_OD_Obj4_ID "HUT_OD_Obj4_ID";
BA_ "GenSigCycleTime" SG_ 515 HUT_OD_Obj4_ID 50;
BA_ "Origin" SG_ 515 HUT_OD_Obj4_type "ev";
BA_ "Match" SG_ 515 HUT_OD_Obj4_type "HUT_OD_Obj4_type";
BA_ "GenSigCycleTime" SG_ 515 HUT_OD_Obj4_type 50;
BA_ "Origin" SG_ 515 HUT_OD_Obj4_Confidence "ev";
BA_ "Match" SG_ 515 HUT_OD_Obj4_Confidence "HUT_OD_Obj4_Confidence";
BA_ "GenSigCycleTime" SG_ 515 HUT_OD_Obj4_Confidence 50;
BA_ "Origin" SG_ 515 HUT_OD_Obj4_width "ev";
BA_ "Match" SG_ 515 HUT_OD_Obj4_width "HUT_OD_Obj4_width";
BA_ "GenSigCycleTime" SG_ 515 HUT_OD_Obj4_width 50;
BA_ "Origin" SG_ 515 HUT_OD_Obj4_Ground_Pos_X "ev";
BA_ "Match" SG_ 515 HUT_OD_Obj4_Ground_Pos_X "HUT_OD_Obj4_Ground_Pos_X";
BA_ "GenSigCycleTime" SG_ 515 HUT_OD_Obj4_Ground_Pos_X 50;
BA_ "Origin" SG_ 515 HUT_OD_Obj4_Ground_Pos_Y "ev";
BA_ "Match" SG_ 515 HUT_OD_Obj4_Ground_Pos_Y "HUT_OD_Obj4_Ground_Pos_Y";
BA_ "GenSigCycleTime" SG_ 515 HUT_OD_Obj4_Ground_Pos_Y 50;
BA_ "Origin" SG_ 515 HUT_OD_Obj5_ID "ev";
BA_ "Match" SG_ 515 HUT_OD_Obj5_ID "HUT_OD_Obj5_ID";
BA_ "GenSigCycleTime" SG_ 515 HUT_OD_Obj5_ID 50;
BA_ "Origin" SG_ 515 HUT_OD_Obj5_type "ev";
BA_ "Match" SG_ 515 HUT_OD_Obj5_type "HUT_OD_Obj5_type";
BA_ "GenSigCycleTime" SG_ 515 HUT_OD_Obj5_type 50;
BA_ "Origin" SG_ 515 HUT_OD_Obj5_Confidence "ev";
BA_ "Match" SG_ 515 HUT_OD_Obj5_Confidence "HUT_OD_Obj5_Confidence";
BA_ "GenSigCycleTime" SG_ 515 HUT_OD_Obj5_Confidence 50;
BA_ "Origin" SG_ 515 HUT_OD_Obj5_width "ev";
BA_ "Match" SG_ 515 HUT_OD_Obj5_width "HUT_OD_Obj5_width";
BA_ "GenSigCycleTime" SG_ 515 HUT_OD_Obj5_width 50;
BA_ "Origin" SG_ 515 HUT_OD_Obj5_Ground_Pos_X "ev";
BA_ "Match" SG_ 515 HUT_OD_Obj5_Ground_Pos_X "HUT_OD_Obj5_Ground_Pos_X";
BA_ "GenSigCycleTime" SG_ 515 HUT_OD_Obj5_Ground_Pos_X 50;
BA_ "Origin" SG_ 515 HUT_OD_Obj5_Ground_Pos_Y "ev";
BA_ "Match" SG_ 515 HUT_OD_Obj5_Ground_Pos_Y "HUT_OD_Obj5_Ground_Pos_Y";
BA_ "GenSigCycleTime" SG_ 515 HUT_OD_Obj5_Ground_Pos_Y 50;
BA_ "Origin" SG_ 515 HUT_OD_Obj6_ID "ev";
BA_ "Match" SG_ 515 HUT_OD_Obj6_ID "HUT_OD_Obj6_ID";
BA_ "GenSigCycleTime" SG_ 515 HUT_OD_Obj6_ID 50;
BA_ "Origin" SG_ 515 HUT_OD_Obj6_type "ev";
BA_ "Match" SG_ 515 HUT_OD_Obj6_type "HUT_OD_Obj6_type";
BA_ "GenSigCycleTime" SG_ 515 HUT_OD_Obj6_type 50;
BA_ "Origin" SG_ 515 HUT_OD_Obj6_Confidence "ev";
BA_ "Match" SG_ 515 HUT_OD_Obj6_Confidence "HUT_OD_Obj6_Confidence";
BA_ "GenSigCycleTime" SG_ 515 HUT_OD_Obj6_Confidence 50;
BA_ "Origin" SG_ 515 HUT_OD_Obj6_width "ev";
BA_ "Match" SG_ 515 HUT_OD_Obj6_width "HUT_OD_Obj6_width";
BA_ "GenSigCycleTime" SG_ 515 HUT_OD_Obj6_width 50;
BA_ "Origin" SG_ 515 HUT_OD_Obj6_Ground_Pos_X "ev";
BA_ "Match" SG_ 515 HUT_OD_Obj6_Ground_Pos_X "HUT_OD_Obj6_Ground_Pos_X";
BA_ "GenSigCycleTime" SG_ 515 HUT_OD_Obj6_Ground_Pos_X 50;
BA_ "Origin" SG_ 515 HUT_OD_Obj6_Ground_Pos_Y "ev";
BA_ "Match" SG_ 515 HUT_OD_Obj6_Ground_Pos_Y "HUT_OD_Obj6_Ground_Pos_Y";
BA_ "GenSigCycleTime" SG_ 515 HUT_OD_Obj6_Ground_Pos_Y 50;
BA_ "TransparentInitValue" SG_ 515 HUT_FD2_0x203 "0 0 0 0 0 0 0 0 0 0 0 0 0 0 0 0 0 0 0 0 0 0 0 0 0 0 0 0 0 0 0 0 0 0 0 0 0 0 0 0 0 0 0 0 0 0 0 0 0 0 0 0 0 0 0 0 0 0 0 0 0 0 0 0 ";
BA_ "GenSigCycleTime" SG_ 515 HUT_FD2_0x203 50;
BA_ "Origin" SG_ 616 HCU_ChrgDchrgSts "ev";
BA_ "Match" SG_ 616 HCU_ChrgDchrgSts "HCU_ChrgDchrgSts";
BA_ "GenSigStartValue" SG_ 616 HCU_ChrgDchrgSts 2;
BA_ "GenSigCycleTime" SG_ 616 HCU_ChrgDchrgSts 50;
BA_ "Origin" SG_ 616 HCU_BattLowTempWarn "ev";
BA_ "Match" SG_ 616 HCU_BattLowTempWarn "HCU_BattLowTempWarn";
BA_ "GenSigCycleTime" SG_ 616 HCU_BattLowTempWarn 50;
BA_ "Origin" SG_ 616 HCU_BattLowTempHeatSts "ev";
BA_ "Match" SG_ 616 HCU_BattLowTempHeatSts "HCU_BattLowTempHeatSts";
BA_ "GenSigCycleTime" SG_ 616 HCU_BattLowTempHeatSts 50;
BA_ "TransparentInitValue" SG_ 616 HCU_HC3_0x268 "0 0 0 0 128 0 0 0 ";
BA_ "GenSigCycleTime" SG_ 616 HCU_HC3_0x268 50;
BA_ "Origin" SG_ 645 BMS_BattHeatRunaway "ev";
BA_ "Match" SG_ 645 BMS_BattHeatRunaway "BMS_BattHeatRunaway";
BA_ "GenSigCycleTime" SG_ 645 BMS_BattHeatRunaway 100;
BA_ "Origin" SG_ 645 BMS_DisSOC1 "ev";
BA_ "Match" SG_ 645 BMS_DisSOC1 "BMS_DisSOC1";
BA_ "GenSigCycleTime" SG_ 645 BMS_DisSOC1 100;
BA_ "TransparentInitValue" SG_ 645 BMS8_0x285 "0 0 0 0 0 0 0 0 ";
BA_ "GenSigCycleTime" SG_ 645 BMS8_0x285 100;
BA_ "Origin" SG_ 690 ExpertModReq_HUT_HCU "ev";
BA_ "Match" SG_ 690 ExpertModReq_HUT_HCU "ExpertModReq_HUT_HCU";
BA_ "GenSigCycleTime" SG_ 690 ExpertModReq_HUT_HCU 100;
BA_ "TransparentInitValue" SG_ 690 HUT27_0x2B2 "0 0 0 0 0 0 0 0 ";
BA_ "GenSigCycleTime" SG_ 690 HUT27_0x2B2 100;
BA_ "Origin" SG_ 708 BMS_BattSOCLimResp "ev";
BA_ "Match" SG_ 708 BMS_BattSOCLimResp "BMS_BattSOCLimResp";
BA_ "GenSigStartValue" SG_ 708 BMS_BattSOCLimResp 6;
BA_ "GenSigCycleTime" SG_ 708 BMS_BattSOCLimResp 100;
BA_ "TransparentInitValue" SG_ 708 BMS35_0x2C4 "0 0 0 0 0 6 0 0 ";
BA_ "GenSigCycleTime" SG_ 708 BMS35_0x2C4 100;
BA_ "Origin" SG_ 743 RFPosnLmpWorkCmd "ev";
BA_ "Match" SG_ 743 RFPosnLmpWorkCmd "RFPosnLmpWorkCmd";
BA_ "GenSigCycleTime" SG_ 743 RFPosnLmpWorkCmd 50;
BA_ "Origin" SG_ 743 LFPosnLmpWorkCmd "ev";
BA_ "Match" SG_ 743 LFPosnLmpWorkCmd "LFPosnLmpWorkCmd";
BA_ "GenSigCycleTime" SG_ 743 LFPosnLmpWorkCmd 50;
BA_ "Origin" SG_ 743 HiBeamWorkCmd "ev";
BA_ "Match" SG_ 743 HiBeamWorkCmd "HiBeamWorkCmd";
BA_ "GenSigCycleTime" SG_ 743 HiBeamWorkCmd 50;
BA_ "Origin" SG_ 743 LowBeamWorkCmd "ev";
BA_ "Match" SG_ 743 LowBeamWorkCmd "LowBeamWorkCmd";
BA_ "GenSigCycleTime" SG_ 743 LowBeamWorkCmd 50;
BA_ "Origin" SG_ 743 RTurnLmpWorkCmd "ev";
BA_ "Match" SG_ 743 RTurnLmpWorkCmd "RTurnLmpWorkCmd";
BA_ "GenSigCycleTime" SG_ 743 RTurnLmpWorkCmd 50;
BA_ "Origin" SG_ 743 LTurnLampWorkCmd "ev";
BA_ "Match" SG_ 743 LTurnLampWorkCmd "LTurnLampWorkCmd";
BA_ "GenSigCycleTime" SG_ 743 LTurnLampWorkCmd 50;
BA_ "Origin" SG_ 743 RDayRunngLmpWorkCmd "ev";
BA_ "Match" SG_ 743 RDayRunngLmpWorkCmd "RDayRunngLmpWorkCmd";
BA_ "GenSigCycleTime" SG_ 743 RDayRunngLmpWorkCmd 50;
BA_ "Origin" SG_ 743 LDayRunngLmpWorkCmd "ev";
BA_ "Match" SG_ 743 LDayRunngLmpWorkCmd "LDayRunngLmpWorkCmd";
BA_ "GenSigCycleTime" SG_ 743 LDayRunngLmpWorkCmd 50;
BA_ "Origin" SG_ 743 RFFogLmpWorkCmd "ev";
BA_ "Match" SG_ 743 RFFogLmpWorkCmd "RFFogLmpWorkCmd";
BA_ "GenSigCycleTime" SG_ 743 RFFogLmpWorkCmd 50;
BA_ "Origin" SG_ 743 LFFogLmpWorkCmd "ev";
BA_ "Match" SG_ 743 LFFogLmpWorkCmd "LFFogLmpWorkCmd";
BA_ "GenSigCycleTime" SG_ 743 LFFogLmpWorkCmd 50;
BA_ "Origin" SG_ 743 LicPlateLmpWorkCmd "ev";
BA_ "Match" SG_ 743 LicPlateLmpWorkCmd "LicPlateLmpWorkCmd";
BA_ "GenSigCycleTime" SG_ 743 LicPlateLmpWorkCmd 50;
BA_ "Origin" SG_ 743 ReversLampWorkCmd "ev";
BA_ "Match" SG_ 743 ReversLampWorkCmd "ReversLampWorkCmd";
BA_ "GenSigCycleTime" SG_ 743 ReversLampWorkCmd 50;
BA_ "Origin" SG_ 743 BrkLmpWorkCmd "ev";
BA_ "Match" SG_ 743 BrkLmpWorkCmd "BrkLmpWorkCmd";
BA_ "GenSigCycleTime" SG_ 743 BrkLmpWorkCmd 50;
BA_ "Origin" SG_ 743 RFogLmpWorkCmd "ev";
BA_ "Match" SG_ 743 RFogLmpWorkCmd "RFogLmpWorkCmd";
BA_ "GenSigCycleTime" SG_ 743 RFogLmpWorkCmd 50;
BA_ "Origin" SG_ 743 RRPosnLmpWorkCmd "ev";
BA_ "Match" SG_ 743 RRPosnLmpWorkCmd "RRPosnLmpWorkCmd";
BA_ "GenSigCycleTime" SG_ 743 RRPosnLmpWorkCmd 50;
BA_ "Origin" SG_ 743 LRPosnLmpWorkCmd "ev";
BA_ "Match" SG_ 743 LRPosnLmpWorkCmd "LRPosnLmpWorkCmd";
BA_ "GenSigCycleTime" SG_ 743 LRPosnLmpWorkCmd 50;
BA_ "Origin" SG_ 788 HCU_ACLineDisconnect "ev";
BA_ "Match" SG_ 788 HCU_ACLineDisconnect "HCU_ACLineDisconnect";
BA_ "GenSigCycleTime" SG_ 788 HCU_ACLineDisconnect 200;
BA_ "Origin" SG_ 788 HCU_ChargSts "ev";
BA_ "Match" SG_ 788 HCU_ChargSts "HCU_ChargSts";
BA_ "GenSigCycleTime" SG_ 788 HCU_ChargSts 200;
BA_ "Origin" SG_ 788 HCU_IntelBattTempMagSts "ev";
BA_ "Match" SG_ 788 HCU_IntelBattTempMagSts "HCU_IntelBattTempMagSts";
BA_ "GenSigCycleTime" SG_ 788 HCU_IntelBattTempMagSts 200;
BA_ "TransparentInitValue" SG_ 788 HCU_HC6_0x314 "0 0 0 0 0 0 0 0 ";
BA_ "GenSigCycleTime" SG_ 788 HCU_HC6_0x314 200;
BA_ "Origin" SG_ 790 OBC_ModSts "ev";
BA_ "Match" SG_ 790 OBC_ModSts "OBC_ModSts";
BA_ "GenSigStartValue" SG_ 790 OBC_ModSts 1;
BA_ "GenSigCycleTime" SG_ 790 OBC_ModSts 200;
BA_ "TransparentInitValue" SG_ 790 OBC1_0x316 "0 0 1 0 0 0 0 0 ";
BA_ "GenSigCycleTime" SG_ 790 OBC1_0x316 200;
BA_ "Origin" SG_ 791 OBC_ConnectSts "ev";
BA_ "Match" SG_ 791 OBC_ConnectSts "OBC_ConnectSts";
BA_ "GenSigCycleTime" SG_ 791 OBC_ConnectSts 200;
BA_ "TransparentInitValue" SG_ 791 OBC2_0x317 "0 0 0 0 0 0 0 0 ";
BA_ "GenSigCycleTime" SG_ 791 OBC2_0x317 200;
BA_ "Origin" SG_ 829 T_BOX_RemtLRTempSet "ev";
BA_ "Match" SG_ 829 T_BOX_RemtLRTempSet "T_BOX_RemtLRTempSet";
BA_ "GenSigSendType" SG_ 829 T_BOX_RemtLRTempSet 2;
BA_ "Origin" SG_ 829 T_BOX_RemtRRTempSet "ev";
BA_ "Match" SG_ 829 T_BOX_RemtRRTempSet "T_BOX_RemtRRTempSet";
BA_ "GenSigSendType" SG_ 829 T_BOX_RemtRRTempSet 2;
BA_ "Origin" SG_ 829 T_BOX_RemtRearAutoCtrl "ev";
BA_ "Match" SG_ 829 T_BOX_RemtRearAutoCtrl "T_BOX_RemtRearAutoCtrl";
BA_ "GenSigSendType" SG_ 829 T_BOX_RemtRearAutoCtrl 2;
BA_ "Origin" SG_ 829 T_BOX_RemtSecRowLeSeatVentnLvlSe "ev";
BA_ "Match" SG_ 829 T_BOX_RemtSecRowLeSeatVentnLvlSe "T_BOX_RemtSecRowLeSeatVentnLvlSet";
BA_ "GenSigSendType" SG_ 829 T_BOX_RemtSecRowLeSeatVentnLvlSe 2;
BA_ "SystemSignalLongSymbol" SG_ 829 T_BOX_RemtSecRowLeSeatVentnLvlSe "T_BOX_RemtSecRowLeSeatVentnLvlSet";
BA_ "Origin" SG_ 829 T_BOX_RemtSecRowRiSeatVentnLvlSe "ev";
BA_ "Match" SG_ 829 T_BOX_RemtSecRowRiSeatVentnLvlSe "T_BOX_RemtSecRowRiSeatVentnLvlSet";
BA_ "GenSigSendType" SG_ 829 T_BOX_RemtSecRowRiSeatVentnLvlSe 2;
BA_ "SystemSignalLongSymbol" SG_ 829 T_BOX_RemtSecRowRiSeatVentnLvlSe "T_BOX_RemtSecRowRiSeatVentnLvlSet";
BA_ "Origin" SG_ 829 T_BOX_MbrMonrEnReq "ev";
BA_ "Match" SG_ 829 T_BOX_MbrMonrEnReq "T_BOX_MbrMonrEnReq";
BA_ "GenSigSendType" SG_ 829 T_BOX_MbrMonrEnReq 2;
BA_ "Origin" SG_ 829 ReleAlarm_APP "ev";
BA_ "Match" SG_ 829 ReleAlarm_APP "ReleAlarm_APP";
BA_ "GenSigSendType" SG_ 829 ReleAlarm_APP 2;
BA_ "Origin" SG_ 829 T_BOX_RemtSteerWheelHeatCtrl "ev";
BA_ "Match" SG_ 829 T_BOX_RemtSteerWheelHeatCtrl "T_BOX_RemtSteerWheelHeatCtrl";
BA_ "GenSigSendType" SG_ 829 T_BOX_RemtSteerWheelHeatCtrl 2;
BA_ "Origin" SG_ 829 T_BOX_AVPActvReq "ev";
BA_ "Match" SG_ 829 T_BOX_AVPActvReq "T_BOX_AVPActvReq";
BA_ "GenSigSendType" SG_ 829 T_BOX_AVPActvReq 2;
BA_ "Origin" SG_ 850 BMS_IntelEngIdlChrgnSts "ev";
BA_ "Match" SG_ 850 BMS_IntelEngIdlChrgnSts "BMS_IntelEngIdlChrgnSts";
BA_ "GenSigCycleTime" SG_ 850 BMS_IntelEngIdlChrgnSts 500;
BA_ "Origin" SG_ 850 BMS_BattKeepTempSts "ev";
BA_ "Match" SG_ 850 BMS_BattKeepTempSts "BMS_BattKeepTempSts";
BA_ "GenSigCycleTime" SG_ 850 BMS_BattKeepTempSts 500;
BA_ "TransparentInitValue" SG_ 850 BMS19_0x352 "0 0 0 0 0 0 0 0 ";
BA_ "GenSigCycleTime" SG_ 850 BMS19_0x352 500;
BA_ "Origin" SG_ 865 HCU_HVILSts "ev";
BA_ "Match" SG_ 865 HCU_HVILSts "HCU_HVILSts";
BA_ "GenSigCycleTime" SG_ 865 HCU_HVILSts 500;
BA_ "Origin" SG_ 865 HCU_BMSSleepCmd "ev";
BA_ "Match" SG_ 865 HCU_BMSSleepCmd "HCU_BMSSleepCmd";
BA_ "GenSigCycleTime" SG_ 865 HCU_BMSSleepCmd 500;
BA_ "Origin" SG_ 865 HCU_P2MActHvDcCurr_RM "ev";
BA_ "Match" SG_ 865 HCU_P2MActHvDcCurr_RM "HCU_P2MActHvDcCurr_RM";
BA_ "GenSigCycleTime" SG_ 865 HCU_P2MActHvDcCurr_RM 500;
BA_ "Origin" SG_ 865 HCU_P2MActHvDcVolt_RM "ev";
BA_ "Match" SG_ 865 HCU_P2MActHvDcVolt_RM "HCU_P2MActHvDcVolt_RM";
BA_ "GenSigCycleTime" SG_ 865 HCU_P2MActHvDcVolt_RM 500;
BA_ "Origin" SG_ 865 HCU_DTCNumber1 "ev";
BA_ "Match" SG_ 865 HCU_DTCNumber1 "HCU_DTCNumber1";
BA_ "GenSigCycleTime" SG_ 865 HCU_DTCNumber1 500;
BA_ "Origin" SG_ 865 HCU_DTCNumber2 "ev";
BA_ "Match" SG_ 865 HCU_DTCNumber2 "HCU_DTCNumber2";
BA_ "GenSigCycleTime" SG_ 865 HCU_DTCNumber2 500;
BA_ "Origin" SG_ 865 HCU_MotorAmount_RM "ev";
BA_ "Match" SG_ 865 HCU_MotorAmount_RM "HCU_MotorAmount_RM";
BA_ "GenSigCycleTime" SG_ 865 HCU_MotorAmount_RM 500;
BA_ "Origin" SG_ 909 HCU_PowertrainSts_RM "ev";
BA_ "Match" SG_ 909 HCU_PowertrainSts_RM "HCU_PowertrainSts_RM";
BA_ "GenSigCycleTime" SG_ 909 HCU_PowertrainSts_RM 1000;
BA_ "Origin" SG_ 909 HCU_BrkPowflag_RM "ev";
BA_ "Match" SG_ 909 HCU_BrkPowflag_RM "HCU_BrkPowflag_RM";
BA_ "GenSigCycleTime" SG_ 909 HCU_BrkPowflag_RM 1000;
BA_ "Origin" SG_ 909 HCU_ChargSts_RM "ev";
BA_ "Match" SG_ 909 HCU_ChargSts_RM "HCU_ChargSts_RM";
BA_ "GenSigStartValue" SG_ 909 HCU_ChargSts_RM 3;
BA_ "GenSigCycleTime" SG_ 909 HCU_ChargSts_RM 1000;
BA_ "Origin" SG_ 909 HCU_PTDrvMod_RM "ev";
BA_ "Match" SG_ 909 HCU_PTDrvMod_RM "HCU_PTDrvMod_RM";
BA_ "GenSigCycleTime" SG_ 909 HCU_PTDrvMod_RM 1000;
BA_ "Origin" SG_ 909 HCU_Powerflag_RM "ev";
BA_ "Match" SG_ 909 HCU_Powerflag_RM "HCU_Powerflag_RM";
BA_ "GenSigCycleTime" SG_ 909 HCU_Powerflag_RM 1000;
BA_ "Origin" SG_ 909 HCU_AccelPedalPosn_Diag_RM "ev";
BA_ "Match" SG_ 909 HCU_AccelPedalPosn_Diag_RM "HCU_AccelPedalPosn_Diag_RM";
BA_ "GenSigCycleTime" SG_ 909 HCU_AccelPedalPosn_Diag_RM 1000;
BA_ "Origin" SG_ 909 HCU_BrkPedalSts_RM "ev";
BA_ "Match" SG_ 909 HCU_BrkPedalSts_RM "HCU_BrkPedalSts_RM";
BA_ "GenSigCycleTime" SG_ 909 HCU_BrkPedalSts_RM 1000;
BA_ "Origin" SG_ 909 HCU_WakeUpSrc "ev";
BA_ "Match" SG_ 909 HCU_WakeUpSrc "HCU_WakeUpSrc";
BA_ "GenSigCycleTime" SG_ 909 HCU_WakeUpSrc 1000;
BA_ "Origin" SG_ 909 HCU_CurrHybSysSts "ev";
BA_ "Match" SG_ 909 HCU_CurrHybSysSts "HCU_CurrHybSysSts";
BA_ "GenSigCycleTime" SG_ 909 HCU_CurrHybSysSts 1000;
BA_ "Origin" SG_ 937 BMS_ISC_ROhm_Warn "ev";
BA_ "Match" SG_ 937 BMS_ISC_ROhm_Warn "BMS_ISC_ROhm_Warn";
BA_ "GenSigCycleTime" SG_ 937 BMS_ISC_ROhm_Warn 1000;
BA_ "Origin" SG_ 937 BMS_ISC_SOC_Warn "ev";
BA_ "Match" SG_ 937 BMS_ISC_SOC_Warn "BMS_ISC_SOC_Warn";
BA_ "GenSigCycleTime" SG_ 937 BMS_ISC_SOC_Warn 1000;
BA_ "Origin" SG_ 937 BMS_ISC_T_Warn "ev";
BA_ "Match" SG_ 937 BMS_ISC_T_Warn "BMS_ISC_T_Warn";
BA_ "GenSigCycleTime" SG_ 937 BMS_ISC_T_Warn 1000;
BA_ "Origin" SG_ 937 BMS_ISC_V_Warn "ev";
BA_ "Match" SG_ 937 BMS_ISC_V_Warn "BMS_ISC_V_Warn";
BA_ "GenSigCycleTime" SG_ 937 BMS_ISC_V_Warn 1000;
BA_ "Origin" SG_ 942 BMS_SocJumpWarn_RM "ev";
BA_ "Match" SG_ 942 BMS_SocJumpWarn_RM "BMS_SocJumpWarn_RM";
BA_ "GenSigCycleTime" SG_ 942 BMS_SocJumpWarn_RM 1000;
BA_ "Origin" SG_ 942 BMS_PackOverChrgWarn_RM "ev";
BA_ "Match" SG_ 942 BMS_PackOverChrgWarn_RM "BMS_PackOverChrgWarn_RM";
BA_ "GenSigCycleTime" SG_ 942 BMS_PackOverChrgWarn_RM 1000;
BA_ "Origin" SG_ 942 BMS_ChrgSts_RM "ev";
BA_ "Match" SG_ 942 BMS_ChrgSts_RM "BMS_ChrgSts_RM";
BA_ "GenSigStartValue" SG_ 942 BMS_ChrgSts_RM 1;
BA_ "GenSigCycleTime" SG_ 942 BMS_ChrgSts_RM 1000;
BA_ "Origin" SG_ 942 BMS_IsolationRValue_RM "ev";
BA_ "Match" SG_ 942 BMS_IsolationRValue_RM "BMS_IsolationRValue_RM";
BA_ "GenSigStartValue" SG_ 942 BMS_IsolationRValue_RM 10000;
BA_ "GenSigCycleTime" SG_ 942 BMS_IsolationRValue_RM 1000;
BA_ "Origin" SG_ 942 BMS_PackCurr_RM "ev";
BA_ "Match" SG_ 942 BMS_PackCurr_RM "BMS_PackCurr_RM";
BA_ "GenSigCycleTime" SG_ 942 BMS_PackCurr_RM 1000;
BA_ "Origin" SG_ 942 BMS_SocOverWarn_RM "ev";
BA_ "Match" SG_ 942 BMS_SocOverWarn_RM "BMS_SocOverWarn_RM";
BA_ "GenSigCycleTime" SG_ 942 BMS_SocOverWarn_RM 1000;
BA_ "Origin" SG_ 942 BMS_BattOverTempRank_RM "ev";
BA_ "Match" SG_ 942 BMS_BattOverTempRank_RM "BMS_BattOverTempRank_RM";
BA_ "GenSigCycleTime" SG_ 942 BMS_BattOverTempRank_RM 1000;
BA_ "Origin" SG_ 942 BMS_BattOverVoltRank_RM "ev";
BA_ "Match" SG_ 942 BMS_BattOverVoltRank_RM "BMS_BattOverVoltRank_RM";
BA_ "GenSigCycleTime" SG_ 942 BMS_BattOverVoltRank_RM 1000;
BA_ "Origin" SG_ 942 BMS_BattSOCLowRank_RM "ev";
BA_ "Match" SG_ 942 BMS_BattSOCLowRank_RM "BMS_BattSOCLowRank_RM";
BA_ "GenSigCycleTime" SG_ 942 BMS_BattSOCLowRank_RM 1000;
BA_ "Origin" SG_ 942 BMS_VCUIsolateErr_RM "ev";
BA_ "Match" SG_ 942 BMS_VCUIsolateErr_RM "BMS_VCUIsolateErr_RM";
BA_ "GenSigCycleTime" SG_ 942 BMS_VCUIsolateErr_RM 1000;
BA_ "Origin" SG_ 942 BMS_BattUnderVoltRank_RM "ev";
BA_ "Match" SG_ 942 BMS_BattUnderVoltRank_RM "BMS_BattUnderVoltRank_RM";
BA_ "GenSigCycleTime" SG_ 942 BMS_BattUnderVoltRank_RM 1000;
BA_ "Origin" SG_ 942 BMS_CellDeltaVoltRank_RM "ev";
BA_ "Match" SG_ 942 BMS_CellDeltaVoltRank_RM "BMS_CellDeltaVoltRank_RM";
BA_ "GenSigCycleTime" SG_ 942 BMS_CellDeltaVoltRank_RM 1000;
BA_ "Origin" SG_ 942 BMS_CellOverVoltRank_RM "ev";
BA_ "Match" SG_ 942 BMS_CellOverVoltRank_RM "BMS_CellOverVoltRank_RM";
BA_ "GenSigCycleTime" SG_ 942 BMS_CellOverVoltRank_RM 1000;
BA_ "Origin" SG_ 942 BMS_CellUnderVoltRank_RM "ev";
BA_ "Match" SG_ 942 BMS_CellUnderVoltRank_RM "BMS_CellUnderVoltRank_RM";
BA_ "GenSigCycleTime" SG_ 942 BMS_CellUnderVoltRank_RM 1000;
BA_ "Origin" SG_ 942 BMS_DeltaTempRank_RM "ev";
BA_ "Match" SG_ 942 BMS_DeltaTempRank_RM "BMS_DeltaTempRank_RM";
BA_ "GenSigCycleTime" SG_ 942 BMS_DeltaTempRank_RM 1000;
BA_ "Origin" SG_ 942 BMS_PackMismatchWarn_RM "ev";
BA_ "Match" SG_ 942 BMS_PackMismatchWarn_RM "BMS_PackMismatchWarn_RM";
BA_ "GenSigCycleTime" SG_ 942 BMS_PackMismatchWarn_RM 1000;
BA_ "Origin" SG_ 942 BMS_PackVolt_RM "ev";
BA_ "Match" SG_ 942 BMS_PackVolt_RM "BMS_PackVolt_RM";
BA_ "GenSigCycleTime" SG_ 942 BMS_PackVolt_RM 1000;
BA_ "TransparentInitValue" SG_ 942 BMS66_0x3AE "8 39 16 0 0 0 0 0 ";
BA_ "GenSigCycleTime" SG_ 942 BMS66_0x3AE 1000;
BA_ "Origin" SG_ 957 DCDC_Tempwarning_RM "ev";
BA_ "Match" SG_ 957 DCDC_Tempwarning_RM "DCDC_Tempwarning_RM";
BA_ "GenSigCycleTime" SG_ 957 DCDC_Tempwarning_RM 1000;
BA_ "Origin" SG_ 957 DCDC_ActSts_RM "ev";
BA_ "Match" SG_ 957 DCDC_ActSts_RM "DCDC_ActSts_RM";
BA_ "GenSigCycleTime" SG_ 957 DCDC_ActSts_RM 1000;
BA_ "Origin" SG_ 957 DCDC_FailStswarning_RM "ev";
BA_ "Match" SG_ 957 DCDC_FailStswarning_RM "DCDC_FailStswarning_RM";
BA_ "GenSigCycleTime" SG_ 957 DCDC_FailStswarning_RM 1000;
BA_ "Origin" SG_ 959 BMS_ChrgDurationTime "ev";
BA_ "Match" SG_ 959 BMS_ChrgDurationTime "BMS_ChrgDurationTime";
BA_ "GenSigCycleTime" SG_ 959 BMS_ChrgDurationTime 1000;
BA_ "TransparentInitValue" SG_ 959 BMS22_0x3BF "0 0 0 0 0 0 0 0 ";
BA_ "GenSigCycleTime" SG_ 959 BMS22_0x3BF 1000;
BA_ "Origin" SG_ 963 P2M_MotorSerNumber_RM "ev";
BA_ "Match" SG_ 963 P2M_MotorSerNumber_RM "P2M_MotorSerNumber_RM";
BA_ "GenSigCycleTime" SG_ 963 P2M_MotorSerNumber_RM 1000;
BA_ "Origin" SG_ 963 P2M_InvActTemp_RM "ev";
BA_ "Match" SG_ 963 P2M_InvActTemp_RM "P2M_InvActTemp_RM";
BA_ "GenSigStartValue" SG_ 963 P2M_InvActTemp_RM 65;
BA_ "GenSigCycleTime" SG_ 963 P2M_InvActTemp_RM 1000;
BA_ "Origin" SG_ 963 P2M_ActSpd_RM "ev";
BA_ "Match" SG_ 963 P2M_ActSpd_RM "P2M_ActSpd_RM";
BA_ "GenSigStartValue" SG_ 963 P2M_ActSpd_RM 20000;
BA_ "GenSigCycleTime" SG_ 963 P2M_ActSpd_RM 1000;
BA_ "Origin" SG_ 963 P2M_ActTrq_RM "ev";
BA_ "Match" SG_ 963 P2M_ActTrq_RM "P2M_ActTrq_RM";
BA_ "GenSigStartValue" SG_ 963 P2M_ActTrq_RM 20000;
BA_ "GenSigCycleTime" SG_ 963 P2M_ActTrq_RM 1000;
BA_ "Origin" SG_ 967 P2M_ActTemp_RM "ev";
BA_ "Match" SG_ 967 P2M_ActTemp_RM "P2M_ActTemp_RM";
BA_ "GenSigStartValue" SG_ 967 P2M_ActTemp_RM 65;
BA_ "GenSigCycleTime" SG_ 967 P2M_ActTemp_RM 1000;
BA_ "Origin" SG_ 967 P2M_OperMode_RM "ev";
BA_ "Match" SG_ 967 P2M_OperMode_RM "P2M_OperMode_RM";
BA_ "GenSigStartValue" SG_ 967 P2M_OperMode_RM 4;
BA_ "GenSigCycleTime" SG_ 967 P2M_OperMode_RM 1000;
BA_ "Origin" SG_ 967 P2M_InvTempwarning_RM "ev";
BA_ "Match" SG_ 967 P2M_InvTempwarning_RM "P2M_InvTempwarning_RM";
BA_ "GenSigCycleTime" SG_ 967 P2M_InvTempwarning_RM 1000;
BA_ "Origin" SG_ 967 P2M_Tempwarning_RM "ev";
BA_ "Match" SG_ 967 P2M_Tempwarning_RM "P2M_Tempwarning_RM";
BA_ "GenSigCycleTime" SG_ 967 P2M_Tempwarning_RM 1000;
BA_ "Origin" SG_ 976 BMS_BattTempMax "ev";
BA_ "Match" SG_ 976 BMS_BattTempMax "BMS_BattTempMax";
BA_ "GenSigStartValue" SG_ 976 BMS_BattTempMax 65;
BA_ "GenSigCycleTime" SG_ 976 BMS_BattTempMax 1000;
BA_ "Origin" SG_ 976 BMS_BattTempMin "ev";
BA_ "Match" SG_ 976 BMS_BattTempMin "BMS_BattTempMin";
BA_ "GenSigStartValue" SG_ 976 BMS_BattTempMin 65;
BA_ "GenSigCycleTime" SG_ 976 BMS_BattTempMin 1000;
BA_ "Origin" SG_ 977 BMS_SingleCellVolt_1 "ev";
BA_ "Match" SG_ 977 BMS_SingleCellVolt_1 "BMS_SingleCellVolt_1";
BA_ "GenSigCycleTime" SG_ 977 BMS_SingleCellVolt_1 1000;
BA_ "Origin" SG_ 977 BMS_SingleCellVolt_2 "ev";
BA_ "Match" SG_ 977 BMS_SingleCellVolt_2 "BMS_SingleCellVolt_2";
BA_ "GenSigCycleTime" SG_ 977 BMS_SingleCellVolt_2 1000;
BA_ "Origin" SG_ 977 BMS_SingleCellVolt_3 "ev";
BA_ "Match" SG_ 977 BMS_SingleCellVolt_3 "BMS_SingleCellVolt_3";
BA_ "GenSigCycleTime" SG_ 977 BMS_SingleCellVolt_3 1000;
BA_ "Origin" SG_ 977 BMS_SingleCellVolt_4 "ev";
BA_ "Match" SG_ 977 BMS_SingleCellVolt_4 "BMS_SingleCellVolt_4";
BA_ "GenSigCycleTime" SG_ 977 BMS_SingleCellVolt_4 1000;
BA_ "Origin" SG_ 977 BMS_SingleCellVolt_5 "ev";
BA_ "Match" SG_ 977 BMS_SingleCellVolt_5 "BMS_SingleCellVolt_5";
BA_ "GenSigCycleTime" SG_ 977 BMS_SingleCellVolt_5 1000;
BA_ "Origin" SG_ 977 BMS_SingleCellVolt_6 "ev";
BA_ "Match" SG_ 977 BMS_SingleCellVolt_6 "BMS_SingleCellVolt_6";
BA_ "GenSigCycleTime" SG_ 977 BMS_SingleCellVolt_6 1000;
BA_ "Origin" SG_ 977 BMS_SingleCellVolt_7 "ev";
BA_ "Match" SG_ 977 BMS_SingleCellVolt_7 "BMS_SingleCellVolt_7";
BA_ "GenSigCycleTime" SG_ 977 BMS_SingleCellVolt_7 1000;
BA_ "Origin" SG_ 977 BMS_SingleCellVolt_8 "ev";
BA_ "Match" SG_ 977 BMS_SingleCellVolt_8 "BMS_SingleCellVolt_8";
BA_ "GenSigCycleTime" SG_ 977 BMS_SingleCellVolt_8 1000;
BA_ "Origin" SG_ 977 BMS_SingleCellVolt_9 "ev";
BA_ "Match" SG_ 977 BMS_SingleCellVolt_9 "BMS_SingleCellVolt_9";
BA_ "GenSigCycleTime" SG_ 977 BMS_SingleCellVolt_9 1000;
BA_ "Origin" SG_ 977 BMS_SingleCellVolt_10 "ev";
BA_ "Match" SG_ 977 BMS_SingleCellVolt_10 "BMS_SingleCellVolt_10";
BA_ "GenSigCycleTime" SG_ 977 BMS_SingleCellVolt_10 1000;
BA_ "Origin" SG_ 977 BMS_SingleCellVolt_11 "ev";
BA_ "Match" SG_ 977 BMS_SingleCellVolt_11 "BMS_SingleCellVolt_11";
BA_ "GenSigCycleTime" SG_ 977 BMS_SingleCellVolt_11 1000;
BA_ "Origin" SG_ 977 BMS_SingleCellVolt_12 "ev";
BA_ "Match" SG_ 977 BMS_SingleCellVolt_12 "BMS_SingleCellVolt_12";
BA_ "GenSigCycleTime" SG_ 977 BMS_SingleCellVolt_12 1000;
BA_ "Origin" SG_ 977 BMS_BattModuleTe_11 "ev";
BA_ "Match" SG_ 977 BMS_BattModuleTe_11 "BMS_BattModuleTe_11";
BA_ "GenSigStartValue" SG_ 977 BMS_BattModuleTe_11 65;
BA_ "GenSigCycleTime" SG_ 977 BMS_BattModuleTe_11 1000;
BA_ "Origin" SG_ 977 BMS_BattModuleTe_12 "ev";
BA_ "Match" SG_ 977 BMS_BattModuleTe_12 "BMS_BattModuleTe_12";
BA_ "GenSigStartValue" SG_ 977 BMS_BattModuleTe_12 65;
BA_ "GenSigCycleTime" SG_ 977 BMS_BattModuleTe_12 1000;
BA_ "Origin" SG_ 977 BMS_BattModuleTe_21 "ev";
BA_ "Match" SG_ 977 BMS_BattModuleTe_21 "BMS_BattModuleTe_21";
BA_ "GenSigStartValue" SG_ 977 BMS_BattModuleTe_21 65;
BA_ "GenSigCycleTime" SG_ 977 BMS_BattModuleTe_21 1000;
BA_ "Origin" SG_ 977 BMS_BattModuleTe_22 "ev";
BA_ "Match" SG_ 977 BMS_BattModuleTe_22 "BMS_BattModuleTe_22";
BA_ "GenSigStartValue" SG_ 977 BMS_BattModuleTe_22 65;
BA_ "GenSigCycleTime" SG_ 977 BMS_BattModuleTe_22 1000;
BA_ "Origin" SG_ 977 BMS_BattModuleTe_31 "ev";
BA_ "Match" SG_ 977 BMS_BattModuleTe_31 "BMS_BattModuleTe_31";
BA_ "GenSigStartValue" SG_ 977 BMS_BattModuleTe_31 65;
BA_ "GenSigCycleTime" SG_ 977 BMS_BattModuleTe_31 1000;
BA_ "Origin" SG_ 977 BMS_BattModuleTe_32 "ev";
BA_ "Match" SG_ 977 BMS_BattModuleTe_32 "BMS_BattModuleTe_32";
BA_ "GenSigStartValue" SG_ 977 BMS_BattModuleTe_32 65;
BA_ "GenSigCycleTime" SG_ 977 BMS_BattModuleTe_32 1000;
BA_ "Origin" SG_ 977 BMS_BattModuleTe_41 "ev";
BA_ "Match" SG_ 977 BMS_BattModuleTe_41 "BMS_BattModuleTe_41";
BA_ "GenSigStartValue" SG_ 977 BMS_BattModuleTe_41 65;
BA_ "GenSigCycleTime" SG_ 977 BMS_BattModuleTe_41 1000;
BA_ "Origin" SG_ 977 BMS_BattModuleTe_42 "ev";
BA_ "Match" SG_ 977 BMS_BattModuleTe_42 "BMS_BattModuleTe_42";
BA_ "GenSigStartValue" SG_ 977 BMS_BattModuleTe_42 65;
BA_ "GenSigCycleTime" SG_ 977 BMS_BattModuleTe_42 1000;
BA_ "Origin" SG_ 977 BMS_BattModuleTe_51 "ev";
BA_ "Match" SG_ 977 BMS_BattModuleTe_51 "BMS_BattModuleTe_51";
BA_ "GenSigStartValue" SG_ 977 BMS_BattModuleTe_51 65;
BA_ "GenSigCycleTime" SG_ 977 BMS_BattModuleTe_51 1000;
BA_ "Origin" SG_ 977 BMS_BattModuleTe_52 "ev";
BA_ "Match" SG_ 977 BMS_BattModuleTe_52 "BMS_BattModuleTe_52";
BA_ "GenSigStartValue" SG_ 977 BMS_BattModuleTe_52 65;
BA_ "GenSigCycleTime" SG_ 977 BMS_BattModuleTe_52 1000;
BA_ "Origin" SG_ 977 BMS_BattModuleTe_61 "ev";
BA_ "Match" SG_ 977 BMS_BattModuleTe_61 "BMS_BattModuleTe_61";
BA_ "GenSigStartValue" SG_ 977 BMS_BattModuleTe_61 65;
BA_ "GenSigCycleTime" SG_ 977 BMS_BattModuleTe_61 1000;
BA_ "Origin" SG_ 977 BMS_BattModuleTe_62 "ev";
BA_ "Match" SG_ 977 BMS_BattModuleTe_62 "BMS_BattModuleTe_62";
BA_ "GenSigStartValue" SG_ 977 BMS_BattModuleTe_62 65;
BA_ "GenSigCycleTime" SG_ 977 BMS_BattModuleTe_62 1000;
BA_ "Origin" SG_ 977 BMS_BattModuleTe_71 "ev";
BA_ "Match" SG_ 977 BMS_BattModuleTe_71 "BMS_BattModuleTe_71";
BA_ "GenSigStartValue" SG_ 977 BMS_BattModuleTe_71 65;
BA_ "GenSigCycleTime" SG_ 977 BMS_BattModuleTe_71 1000;
BA_ "Origin" SG_ 977 BMS_BattModuleTe_72 "ev";
BA_ "Match" SG_ 977 BMS_BattModuleTe_72 "BMS_BattModuleTe_72";
BA_ "GenSigStartValue" SG_ 977 BMS_BattModuleTe_72 65;
BA_ "GenSigCycleTime" SG_ 977 BMS_BattModuleTe_72 1000;
BA_ "Origin" SG_ 977 BMS_BattModuleTe_81 "ev";
BA_ "Match" SG_ 977 BMS_BattModuleTe_81 "BMS_BattModuleTe_81";
BA_ "GenSigStartValue" SG_ 977 BMS_BattModuleTe_81 65;
BA_ "GenSigCycleTime" SG_ 977 BMS_BattModuleTe_81 1000;
BA_ "Origin" SG_ 977 BMS_BattModuleTe_82 "ev";
BA_ "Match" SG_ 977 BMS_BattModuleTe_82 "BMS_BattModuleTe_82";
BA_ "GenSigStartValue" SG_ 977 BMS_BattModuleTe_82 65;
BA_ "GenSigCycleTime" SG_ 977 BMS_BattModuleTe_82 1000;
BA_ "Origin" SG_ 978 BMS_SingleCellVolt_13 "ev";
BA_ "Match" SG_ 978 BMS_SingleCellVolt_13 "BMS_SingleCellVolt_13";
BA_ "GenSigCycleTime" SG_ 978 BMS_SingleCellVolt_13 1000;
BA_ "Origin" SG_ 978 BMS_SingleCellVolt_14 "ev";
BA_ "Match" SG_ 978 BMS_SingleCellVolt_14 "BMS_SingleCellVolt_14";
BA_ "GenSigCycleTime" SG_ 978 BMS_SingleCellVolt_14 1000;
BA_ "Origin" SG_ 978 BMS_SingleCellVolt_15 "ev";
BA_ "Match" SG_ 978 BMS_SingleCellVolt_15 "BMS_SingleCellVolt_15";
BA_ "GenSigCycleTime" SG_ 978 BMS_SingleCellVolt_15 1000;
BA_ "Origin" SG_ 978 BMS_SingleCellVolt_16 "ev";
BA_ "Match" SG_ 978 BMS_SingleCellVolt_16 "BMS_SingleCellVolt_16";
BA_ "GenSigCycleTime" SG_ 978 BMS_SingleCellVolt_16 1000;
BA_ "Origin" SG_ 978 BMS_SingleCellVolt_17 "ev";
BA_ "Match" SG_ 978 BMS_SingleCellVolt_17 "BMS_SingleCellVolt_17";
BA_ "GenSigCycleTime" SG_ 978 BMS_SingleCellVolt_17 1000;
BA_ "Origin" SG_ 978 BMS_SingleCellVolt_18 "ev";
BA_ "Match" SG_ 978 BMS_SingleCellVolt_18 "BMS_SingleCellVolt_18";
BA_ "GenSigCycleTime" SG_ 978 BMS_SingleCellVolt_18 1000;
BA_ "Origin" SG_ 978 BMS_SingleCellVolt_19 "ev";
BA_ "Match" SG_ 978 BMS_SingleCellVolt_19 "BMS_SingleCellVolt_19";
BA_ "GenSigCycleTime" SG_ 978 BMS_SingleCellVolt_19 1000;
BA_ "Origin" SG_ 978 BMS_SingleCellVolt_20 "ev";
BA_ "Match" SG_ 978 BMS_SingleCellVolt_20 "BMS_SingleCellVolt_20";
BA_ "GenSigCycleTime" SG_ 978 BMS_SingleCellVolt_20 1000;
BA_ "Origin" SG_ 978 BMS_SingleCellVolt_21 "ev";
BA_ "Match" SG_ 978 BMS_SingleCellVolt_21 "BMS_SingleCellVolt_21";
BA_ "GenSigCycleTime" SG_ 978 BMS_SingleCellVolt_21 1000;
BA_ "Origin" SG_ 978 BMS_SingleCellVolt_22 "ev";
BA_ "Match" SG_ 978 BMS_SingleCellVolt_22 "BMS_SingleCellVolt_22";
BA_ "GenSigCycleTime" SG_ 978 BMS_SingleCellVolt_22 1000;
BA_ "Origin" SG_ 978 BMS_SingleCellVolt_23 "ev";
BA_ "Match" SG_ 978 BMS_SingleCellVolt_23 "BMS_SingleCellVolt_23";
BA_ "GenSigCycleTime" SG_ 978 BMS_SingleCellVolt_23 1000;
BA_ "Origin" SG_ 978 BMS_SingleCellVolt_24 "ev";
BA_ "Match" SG_ 978 BMS_SingleCellVolt_24 "BMS_SingleCellVolt_24";
BA_ "GenSigCycleTime" SG_ 978 BMS_SingleCellVolt_24 1000;
BA_ "Origin" SG_ 978 BMS_SingleCellVolt_25 "ev";
BA_ "Match" SG_ 978 BMS_SingleCellVolt_25 "BMS_SingleCellVolt_25";
BA_ "GenSigCycleTime" SG_ 978 BMS_SingleCellVolt_25 1000;
BA_ "Origin" SG_ 978 BMS_SingleCellVolt_26 "ev";
BA_ "Match" SG_ 978 BMS_SingleCellVolt_26 "BMS_SingleCellVolt_26";
BA_ "GenSigCycleTime" SG_ 978 BMS_SingleCellVolt_26 1000;
BA_ "Origin" SG_ 978 BMS_SingleCellVolt_27 "ev";
BA_ "Match" SG_ 978 BMS_SingleCellVolt_27 "BMS_SingleCellVolt_27";
BA_ "GenSigCycleTime" SG_ 978 BMS_SingleCellVolt_27 1000;
BA_ "Origin" SG_ 978 BMS_SingleCellVolt_28 "ev";
BA_ "Match" SG_ 978 BMS_SingleCellVolt_28 "BMS_SingleCellVolt_28";
BA_ "GenSigCycleTime" SG_ 978 BMS_SingleCellVolt_28 1000;
BA_ "Origin" SG_ 978 BMS_SingleCellVolt_29 "ev";
BA_ "Match" SG_ 978 BMS_SingleCellVolt_29 "BMS_SingleCellVolt_29";
BA_ "GenSigCycleTime" SG_ 978 BMS_SingleCellVolt_29 1000;
BA_ "Origin" SG_ 978 BMS_SingleCellVolt_30 "ev";
BA_ "Match" SG_ 978 BMS_SingleCellVolt_30 "BMS_SingleCellVolt_30";
BA_ "GenSigCycleTime" SG_ 978 BMS_SingleCellVolt_30 1000;
BA_ "Origin" SG_ 978 BMS_SingleCellVolt_31 "ev";
BA_ "Match" SG_ 978 BMS_SingleCellVolt_31 "BMS_SingleCellVolt_31";
BA_ "GenSigCycleTime" SG_ 978 BMS_SingleCellVolt_31 1000;
BA_ "Origin" SG_ 978 BMS_SingleCellVolt_32 "ev";
BA_ "Match" SG_ 978 BMS_SingleCellVolt_32 "BMS_SingleCellVolt_32";
BA_ "GenSigCycleTime" SG_ 978 BMS_SingleCellVolt_32 1000;
BA_ "Origin" SG_ 978 BMS_SingleCellVolt_33 "ev";
BA_ "Match" SG_ 978 BMS_SingleCellVolt_33 "BMS_SingleCellVolt_33";
BA_ "GenSigCycleTime" SG_ 978 BMS_SingleCellVolt_33 1000;
BA_ "Origin" SG_ 978 BMS_SingleCellVolt_34 "ev";
BA_ "Match" SG_ 978 BMS_SingleCellVolt_34 "BMS_SingleCellVolt_34";
BA_ "GenSigCycleTime" SG_ 978 BMS_SingleCellVolt_34 1000;
BA_ "Origin" SG_ 978 BMS_SingleCellVolt_35 "ev";
BA_ "Match" SG_ 978 BMS_SingleCellVolt_35 "BMS_SingleCellVolt_35";
BA_ "GenSigCycleTime" SG_ 978 BMS_SingleCellVolt_35 1000;
BA_ "Origin" SG_ 978 BMS_SingleCellVolt_36 "ev";
BA_ "Match" SG_ 978 BMS_SingleCellVolt_36 "BMS_SingleCellVolt_36";
BA_ "GenSigCycleTime" SG_ 978 BMS_SingleCellVolt_36 1000;
BA_ "Origin" SG_ 978 BMS_SingleCellVolt_37 "ev";
BA_ "Match" SG_ 978 BMS_SingleCellVolt_37 "BMS_SingleCellVolt_37";
BA_ "GenSigCycleTime" SG_ 978 BMS_SingleCellVolt_37 1000;
BA_ "Origin" SG_ 978 BMS_SingleCellVolt_38 "ev";
BA_ "Match" SG_ 978 BMS_SingleCellVolt_38 "BMS_SingleCellVolt_38";
BA_ "GenSigCycleTime" SG_ 978 BMS_SingleCellVolt_38 1000;
BA_ "Origin" SG_ 978 BMS_SingleCellVolt_39 "ev";
BA_ "Match" SG_ 978 BMS_SingleCellVolt_39 "BMS_SingleCellVolt_39";
BA_ "GenSigCycleTime" SG_ 978 BMS_SingleCellVolt_39 1000;
BA_ "Origin" SG_ 978 BMS_SingleCellVolt_40 "ev";
BA_ "Match" SG_ 978 BMS_SingleCellVolt_40 "BMS_SingleCellVolt_40";
BA_ "GenSigCycleTime" SG_ 978 BMS_SingleCellVolt_40 1000;
BA_ "Origin" SG_ 979 BMS_SingleCellVolt_41 "ev";
BA_ "Match" SG_ 979 BMS_SingleCellVolt_41 "BMS_SingleCellVolt_41";
BA_ "GenSigCycleTime" SG_ 979 BMS_SingleCellVolt_41 1000;
BA_ "Origin" SG_ 979 BMS_SingleCellVolt_42 "ev";
BA_ "Match" SG_ 979 BMS_SingleCellVolt_42 "BMS_SingleCellVolt_42";
BA_ "GenSigCycleTime" SG_ 979 BMS_SingleCellVolt_42 1000;
BA_ "Origin" SG_ 979 BMS_SingleCellVolt_43 "ev";
BA_ "Match" SG_ 979 BMS_SingleCellVolt_43 "BMS_SingleCellVolt_43";
BA_ "GenSigCycleTime" SG_ 979 BMS_SingleCellVolt_43 1000;
BA_ "Origin" SG_ 979 BMS_SingleCellVolt_44 "ev";
BA_ "Match" SG_ 979 BMS_SingleCellVolt_44 "BMS_SingleCellVolt_44";
BA_ "GenSigCycleTime" SG_ 979 BMS_SingleCellVolt_44 1000;
BA_ "Origin" SG_ 979 BMS_SingleCellVolt_45 "ev";
BA_ "Match" SG_ 979 BMS_SingleCellVolt_45 "BMS_SingleCellVolt_45";
BA_ "GenSigCycleTime" SG_ 979 BMS_SingleCellVolt_45 1000;
BA_ "Origin" SG_ 979 BMS_SingleCellVolt_46 "ev";
BA_ "Match" SG_ 979 BMS_SingleCellVolt_46 "BMS_SingleCellVolt_46";
BA_ "GenSigCycleTime" SG_ 979 BMS_SingleCellVolt_46 1000;
BA_ "Origin" SG_ 979 BMS_SingleCellVolt_47 "ev";
BA_ "Match" SG_ 979 BMS_SingleCellVolt_47 "BMS_SingleCellVolt_47";
BA_ "GenSigCycleTime" SG_ 979 BMS_SingleCellVolt_47 1000;
BA_ "Origin" SG_ 979 BMS_SingleCellVolt_48 "ev";
BA_ "Match" SG_ 979 BMS_SingleCellVolt_48 "BMS_SingleCellVolt_48";
BA_ "GenSigCycleTime" SG_ 979 BMS_SingleCellVolt_48 1000;
BA_ "Origin" SG_ 979 BMS_SingleCellVolt_49 "ev";
BA_ "Match" SG_ 979 BMS_SingleCellVolt_49 "BMS_SingleCellVolt_49";
BA_ "GenSigCycleTime" SG_ 979 BMS_SingleCellVolt_49 1000;
BA_ "Origin" SG_ 979 BMS_SingleCellVolt_50 "ev";
BA_ "Match" SG_ 979 BMS_SingleCellVolt_50 "BMS_SingleCellVolt_50";
BA_ "GenSigCycleTime" SG_ 979 BMS_SingleCellVolt_50 1000;
BA_ "Origin" SG_ 979 BMS_SingleCellVolt_51 "ev";
BA_ "Match" SG_ 979 BMS_SingleCellVolt_51 "BMS_SingleCellVolt_51";
BA_ "GenSigCycleTime" SG_ 979 BMS_SingleCellVolt_51 1000;
BA_ "Origin" SG_ 979 BMS_SingleCellVolt_52 "ev";
BA_ "Match" SG_ 979 BMS_SingleCellVolt_52 "BMS_SingleCellVolt_52";
BA_ "GenSigCycleTime" SG_ 979 BMS_SingleCellVolt_52 1000;
BA_ "Origin" SG_ 979 BMS_SingleCellVolt_53 "ev";
BA_ "Match" SG_ 979 BMS_SingleCellVolt_53 "BMS_SingleCellVolt_53";
BA_ "GenSigCycleTime" SG_ 979 BMS_SingleCellVolt_53 1000;
BA_ "Origin" SG_ 979 BMS_SingleCellVolt_54 "ev";
BA_ "Match" SG_ 979 BMS_SingleCellVolt_54 "BMS_SingleCellVolt_54";
BA_ "GenSigCycleTime" SG_ 979 BMS_SingleCellVolt_54 1000;
BA_ "Origin" SG_ 979 BMS_SingleCellVolt_55 "ev";
BA_ "Match" SG_ 979 BMS_SingleCellVolt_55 "BMS_SingleCellVolt_55";
BA_ "GenSigCycleTime" SG_ 979 BMS_SingleCellVolt_55 1000;
BA_ "Origin" SG_ 979 BMS_SingleCellVolt_56 "ev";
BA_ "Match" SG_ 979 BMS_SingleCellVolt_56 "BMS_SingleCellVolt_56";
BA_ "GenSigCycleTime" SG_ 979 BMS_SingleCellVolt_56 1000;
BA_ "Origin" SG_ 979 BMS_SingleCellVolt_57 "ev";
BA_ "Match" SG_ 979 BMS_SingleCellVolt_57 "BMS_SingleCellVolt_57";
BA_ "GenSigCycleTime" SG_ 979 BMS_SingleCellVolt_57 1000;
BA_ "Origin" SG_ 979 BMS_SingleCellVolt_58 "ev";
BA_ "Match" SG_ 979 BMS_SingleCellVolt_58 "BMS_SingleCellVolt_58";
BA_ "GenSigCycleTime" SG_ 979 BMS_SingleCellVolt_58 1000;
BA_ "Origin" SG_ 979 BMS_SingleCellVolt_59 "ev";
BA_ "Match" SG_ 979 BMS_SingleCellVolt_59 "BMS_SingleCellVolt_59";
BA_ "GenSigCycleTime" SG_ 979 BMS_SingleCellVolt_59 1000;
BA_ "Origin" SG_ 979 BMS_SingleCellVolt_60 "ev";
BA_ "Match" SG_ 979 BMS_SingleCellVolt_60 "BMS_SingleCellVolt_60";
BA_ "GenSigCycleTime" SG_ 979 BMS_SingleCellVolt_60 1000;
BA_ "Origin" SG_ 979 BMS_SingleCellVolt_61 "ev";
BA_ "Match" SG_ 979 BMS_SingleCellVolt_61 "BMS_SingleCellVolt_61";
BA_ "GenSigCycleTime" SG_ 979 BMS_SingleCellVolt_61 1000;
BA_ "Origin" SG_ 979 BMS_SingleCellVolt_62 "ev";
BA_ "Match" SG_ 979 BMS_SingleCellVolt_62 "BMS_SingleCellVolt_62";
BA_ "GenSigCycleTime" SG_ 979 BMS_SingleCellVolt_62 1000;
BA_ "Origin" SG_ 979 BMS_SingleCellVolt_63 "ev";
BA_ "Match" SG_ 979 BMS_SingleCellVolt_63 "BMS_SingleCellVolt_63";
BA_ "GenSigCycleTime" SG_ 979 BMS_SingleCellVolt_63 1000;
BA_ "Origin" SG_ 979 BMS_SingleCellVolt_64 "ev";
BA_ "Match" SG_ 979 BMS_SingleCellVolt_64 "BMS_SingleCellVolt_64";
BA_ "GenSigCycleTime" SG_ 979 BMS_SingleCellVolt_64 1000;
BA_ "Origin" SG_ 979 BMS_SingleCellVolt_65 "ev";
BA_ "Match" SG_ 979 BMS_SingleCellVolt_65 "BMS_SingleCellVolt_65";
BA_ "GenSigCycleTime" SG_ 979 BMS_SingleCellVolt_65 1000;
BA_ "Origin" SG_ 979 BMS_SingleCellVolt_66 "ev";
BA_ "Match" SG_ 979 BMS_SingleCellVolt_66 "BMS_SingleCellVolt_66";
BA_ "GenSigCycleTime" SG_ 979 BMS_SingleCellVolt_66 1000;
BA_ "Origin" SG_ 979 BMS_SingleCellVolt_67 "ev";
BA_ "Match" SG_ 979 BMS_SingleCellVolt_67 "BMS_SingleCellVolt_67";
BA_ "GenSigCycleTime" SG_ 979 BMS_SingleCellVolt_67 1000;
BA_ "Origin" SG_ 979 BMS_SingleCellVolt_68 "ev";
BA_ "Match" SG_ 979 BMS_SingleCellVolt_68 "BMS_SingleCellVolt_68";
BA_ "GenSigCycleTime" SG_ 979 BMS_SingleCellVolt_68 1000;
BA_ "Origin" SG_ 980 BMS_SingleCellVolt_69 "ev";
BA_ "Match" SG_ 980 BMS_SingleCellVolt_69 "BMS_SingleCellVolt_69";
BA_ "GenSigCycleTime" SG_ 980 BMS_SingleCellVolt_69 1000;
BA_ "Origin" SG_ 980 BMS_SingleCellVolt_70 "ev";
BA_ "Match" SG_ 980 BMS_SingleCellVolt_70 "BMS_SingleCellVolt_70";
BA_ "GenSigCycleTime" SG_ 980 BMS_SingleCellVolt_70 1000;
BA_ "Origin" SG_ 980 BMS_SingleCellVolt_71 "ev";
BA_ "Match" SG_ 980 BMS_SingleCellVolt_71 "BMS_SingleCellVolt_71";
BA_ "GenSigCycleTime" SG_ 980 BMS_SingleCellVolt_71 1000;
BA_ "Origin" SG_ 980 BMS_SingleCellVolt_72 "ev";
BA_ "Match" SG_ 980 BMS_SingleCellVolt_72 "BMS_SingleCellVolt_72";
BA_ "GenSigCycleTime" SG_ 980 BMS_SingleCellVolt_72 1000;
BA_ "Origin" SG_ 980 BMS_SingleCellVolt_73 "ev";
BA_ "Match" SG_ 980 BMS_SingleCellVolt_73 "BMS_SingleCellVolt_73";
BA_ "GenSigCycleTime" SG_ 980 BMS_SingleCellVolt_73 1000;
BA_ "Origin" SG_ 980 BMS_SingleCellVolt_74 "ev";
BA_ "Match" SG_ 980 BMS_SingleCellVolt_74 "BMS_SingleCellVolt_74";
BA_ "GenSigCycleTime" SG_ 980 BMS_SingleCellVolt_74 1000;
BA_ "Origin" SG_ 980 BMS_SingleCellVolt_75 "ev";
BA_ "Match" SG_ 980 BMS_SingleCellVolt_75 "BMS_SingleCellVolt_75";
BA_ "GenSigCycleTime" SG_ 980 BMS_SingleCellVolt_75 1000;
BA_ "Origin" SG_ 980 BMS_SingleCellVolt_76 "ev";
BA_ "Match" SG_ 980 BMS_SingleCellVolt_76 "BMS_SingleCellVolt_76";
BA_ "GenSigCycleTime" SG_ 980 BMS_SingleCellVolt_76 1000;
BA_ "Origin" SG_ 980 BMS_SingleCellVolt_77 "ev";
BA_ "Match" SG_ 980 BMS_SingleCellVolt_77 "BMS_SingleCellVolt_77";
BA_ "GenSigCycleTime" SG_ 980 BMS_SingleCellVolt_77 1000;
BA_ "Origin" SG_ 980 BMS_SingleCellVolt_78 "ev";
BA_ "Match" SG_ 980 BMS_SingleCellVolt_78 "BMS_SingleCellVolt_78";
BA_ "GenSigCycleTime" SG_ 980 BMS_SingleCellVolt_78 1000;
BA_ "Origin" SG_ 980 BMS_SingleCellVolt_79 "ev";
BA_ "Match" SG_ 980 BMS_SingleCellVolt_79 "BMS_SingleCellVolt_79";
BA_ "GenSigCycleTime" SG_ 980 BMS_SingleCellVolt_79 1000;
BA_ "Origin" SG_ 980 BMS_SingleCellVolt_80 "ev";
BA_ "Match" SG_ 980 BMS_SingleCellVolt_80 "BMS_SingleCellVolt_80";
BA_ "GenSigCycleTime" SG_ 980 BMS_SingleCellVolt_80 1000;
BA_ "Origin" SG_ 980 BMS_SingleCellVolt_81 "ev";
BA_ "Match" SG_ 980 BMS_SingleCellVolt_81 "BMS_SingleCellVolt_81";
BA_ "GenSigCycleTime" SG_ 980 BMS_SingleCellVolt_81 1000;
BA_ "Origin" SG_ 980 BMS_SingleCellVolt_82 "ev";
BA_ "Match" SG_ 980 BMS_SingleCellVolt_82 "BMS_SingleCellVolt_82";
BA_ "GenSigCycleTime" SG_ 980 BMS_SingleCellVolt_82 1000;
BA_ "Origin" SG_ 980 BMS_SingleCellVolt_83 "ev";
BA_ "Match" SG_ 980 BMS_SingleCellVolt_83 "BMS_SingleCellVolt_83";
BA_ "GenSigCycleTime" SG_ 980 BMS_SingleCellVolt_83 1000;
BA_ "Origin" SG_ 980 BMS_SingleCellVolt_84 "ev";
BA_ "Match" SG_ 980 BMS_SingleCellVolt_84 "BMS_SingleCellVolt_84";
BA_ "GenSigCycleTime" SG_ 980 BMS_SingleCellVolt_84 1000;
BA_ "Origin" SG_ 980 BMS_SingleCellVolt_85 "ev";
BA_ "Match" SG_ 980 BMS_SingleCellVolt_85 "BMS_SingleCellVolt_85";
BA_ "GenSigCycleTime" SG_ 980 BMS_SingleCellVolt_85 1000;
BA_ "Origin" SG_ 980 BMS_SingleCellVolt_86 "ev";
BA_ "Match" SG_ 980 BMS_SingleCellVolt_86 "BMS_SingleCellVolt_86";
BA_ "GenSigCycleTime" SG_ 980 BMS_SingleCellVolt_86 1000;
BA_ "Origin" SG_ 980 BMS_SingleCellVolt_87 "ev";
BA_ "Match" SG_ 980 BMS_SingleCellVolt_87 "BMS_SingleCellVolt_87";
BA_ "GenSigCycleTime" SG_ 980 BMS_SingleCellVolt_87 1000;
BA_ "Origin" SG_ 980 BMS_SingleCellVolt_88 "ev";
BA_ "Match" SG_ 980 BMS_SingleCellVolt_88 "BMS_SingleCellVolt_88";
BA_ "GenSigCycleTime" SG_ 980 BMS_SingleCellVolt_88 1000;
BA_ "Origin" SG_ 980 BMS_SingleCellVolt_89 "ev";
BA_ "Match" SG_ 980 BMS_SingleCellVolt_89 "BMS_SingleCellVolt_89";
BA_ "GenSigCycleTime" SG_ 980 BMS_SingleCellVolt_89 1000;
BA_ "Origin" SG_ 980 BMS_SingleCellVolt_90 "ev";
BA_ "Match" SG_ 980 BMS_SingleCellVolt_90 "BMS_SingleCellVolt_90";
BA_ "GenSigCycleTime" SG_ 980 BMS_SingleCellVolt_90 1000;
BA_ "Origin" SG_ 980 BMS_SingleCellVolt_91 "ev";
BA_ "Match" SG_ 980 BMS_SingleCellVolt_91 "BMS_SingleCellVolt_91";
BA_ "GenSigCycleTime" SG_ 980 BMS_SingleCellVolt_91 1000;
BA_ "Origin" SG_ 980 BMS_SingleCellVolt_92 "ev";
BA_ "Match" SG_ 980 BMS_SingleCellVolt_92 "BMS_SingleCellVolt_92";
BA_ "GenSigCycleTime" SG_ 980 BMS_SingleCellVolt_92 1000;
BA_ "Origin" SG_ 980 BMS_SingleCellVolt_93 "ev";
BA_ "Match" SG_ 980 BMS_SingleCellVolt_93 "BMS_SingleCellVolt_93";
BA_ "GenSigCycleTime" SG_ 980 BMS_SingleCellVolt_93 1000;
BA_ "Origin" SG_ 980 BMS_SingleCellVolt_94 "ev";
BA_ "Match" SG_ 980 BMS_SingleCellVolt_94 "BMS_SingleCellVolt_94";
BA_ "GenSigCycleTime" SG_ 980 BMS_SingleCellVolt_94 1000;
BA_ "Origin" SG_ 980 BMS_SingleCellVolt_95 "ev";
BA_ "Match" SG_ 980 BMS_SingleCellVolt_95 "BMS_SingleCellVolt_95";
BA_ "GenSigCycleTime" SG_ 980 BMS_SingleCellVolt_95 1000;
BA_ "Origin" SG_ 980 BMS_SingleCellVolt_96 "ev";
BA_ "Match" SG_ 980 BMS_SingleCellVolt_96 "BMS_SingleCellVolt_96";
BA_ "GenSigCycleTime" SG_ 980 BMS_SingleCellVolt_96 1000;
BA_ "Origin" SG_ 981 BMS_SingleCellVolt_97 "ev";
BA_ "Match" SG_ 981 BMS_SingleCellVolt_97 "BMS_SingleCellVolt_97";
BA_ "GenSigCycleTime" SG_ 981 BMS_SingleCellVolt_97 1000;
BA_ "Origin" SG_ 981 BMS_SingleCellVolt_98 "ev";
BA_ "Match" SG_ 981 BMS_SingleCellVolt_98 "BMS_SingleCellVolt_98";
BA_ "GenSigCycleTime" SG_ 981 BMS_SingleCellVolt_98 1000;
BA_ "Origin" SG_ 981 BMS_SingleCellVolt_99 "ev";
BA_ "Match" SG_ 981 BMS_SingleCellVolt_99 "BMS_SingleCellVolt_99";
BA_ "GenSigCycleTime" SG_ 981 BMS_SingleCellVolt_99 1000;
BA_ "Origin" SG_ 981 BMS_SingleCellVolt_100 "ev";
BA_ "Match" SG_ 981 BMS_SingleCellVolt_100 "BMS_SingleCellVolt_100";
BA_ "GenSigCycleTime" SG_ 981 BMS_SingleCellVolt_100 1000;
BA_ "Origin" SG_ 981 BMS_SingleCellVolt_101 "ev";
BA_ "Match" SG_ 981 BMS_SingleCellVolt_101 "BMS_SingleCellVolt_101";
BA_ "GenSigCycleTime" SG_ 981 BMS_SingleCellVolt_101 1000;
BA_ "Origin" SG_ 981 BMS_SingleCellVolt_102 "ev";
BA_ "Match" SG_ 981 BMS_SingleCellVolt_102 "BMS_SingleCellVolt_102";
BA_ "GenSigCycleTime" SG_ 981 BMS_SingleCellVolt_102 1000;
BA_ "Origin" SG_ 981 BMS_SingleCellVolt_103 "ev";
BA_ "Match" SG_ 981 BMS_SingleCellVolt_103 "BMS_SingleCellVolt_103";
BA_ "GenSigCycleTime" SG_ 981 BMS_SingleCellVolt_103 1000;
BA_ "Origin" SG_ 981 BMS_SingleCellVolt_104 "ev";
BA_ "Match" SG_ 981 BMS_SingleCellVolt_104 "BMS_SingleCellVolt_104";
BA_ "GenSigCycleTime" SG_ 981 BMS_SingleCellVolt_104 1000;
BA_ "Origin" SG_ 981 BMS_SingleCellVolt_105 "ev";
BA_ "Match" SG_ 981 BMS_SingleCellVolt_105 "BMS_SingleCellVolt_105";
BA_ "GenSigCycleTime" SG_ 981 BMS_SingleCellVolt_105 1000;
BA_ "Origin" SG_ 981 BMS_SingleCellVolt_106 "ev";
BA_ "Match" SG_ 981 BMS_SingleCellVolt_106 "BMS_SingleCellVolt_106";
BA_ "GenSigCycleTime" SG_ 981 BMS_SingleCellVolt_106 1000;
BA_ "Origin" SG_ 981 BMS_SingleCellVolt_107 "ev";
BA_ "Match" SG_ 981 BMS_SingleCellVolt_107 "BMS_SingleCellVolt_107";
BA_ "GenSigCycleTime" SG_ 981 BMS_SingleCellVolt_107 1000;
BA_ "Origin" SG_ 981 BMS_SingleCellVolt_108 "ev";
BA_ "Match" SG_ 981 BMS_SingleCellVolt_108 "BMS_SingleCellVolt_108";
BA_ "GenSigCycleTime" SG_ 981 BMS_SingleCellVolt_108 1000;
BA_ "Origin" SG_ 981 BMS_BattModuleTe_13 "ev";
BA_ "Match" SG_ 981 BMS_BattModuleTe_13 "BMS_BattModuleTe_13";
BA_ "GenSigStartValue" SG_ 981 BMS_BattModuleTe_13 65;
BA_ "GenSigCycleTime" SG_ 981 BMS_BattModuleTe_13 1000;
BA_ "Origin" SG_ 981 BMS_BattModuleTe_23 "ev";
BA_ "Match" SG_ 981 BMS_BattModuleTe_23 "BMS_BattModuleTe_23";
BA_ "GenSigStartValue" SG_ 981 BMS_BattModuleTe_23 65;
BA_ "GenSigCycleTime" SG_ 981 BMS_BattModuleTe_23 1000;
BA_ "Origin" SG_ 981 BMS_BattModuleTe_33 "ev";
BA_ "Match" SG_ 981 BMS_BattModuleTe_33 "BMS_BattModuleTe_33";
BA_ "GenSigStartValue" SG_ 981 BMS_BattModuleTe_33 65;
BA_ "GenSigCycleTime" SG_ 981 BMS_BattModuleTe_33 1000;
BA_ "Origin" SG_ 981 BMS_DTCNumber "ev";
BA_ "Match" SG_ 981 BMS_DTCNumber "BMS_DTCNumber";
BA_ "GenSigCycleTime" SG_ 981 BMS_DTCNumber 1000;
BA_ "Origin" SG_ 981 BMS_BattModuleTe_91 "ev";
BA_ "Match" SG_ 981 BMS_BattModuleTe_91 "BMS_BattModuleTe_91";
BA_ "GenSigStartValue" SG_ 981 BMS_BattModuleTe_91 65;
BA_ "GenSigCycleTime" SG_ 981 BMS_BattModuleTe_91 1000;
BA_ "Origin" SG_ 981 BMS_BattModuleTe_92 "ev";
BA_ "Match" SG_ 981 BMS_BattModuleTe_92 "BMS_BattModuleTe_92";
BA_ "GenSigStartValue" SG_ 981 BMS_BattModuleTe_92 65;
BA_ "GenSigCycleTime" SG_ 981 BMS_BattModuleTe_92 1000;
BA_ "Origin" SG_ 981 BMS_DTCNumber1 "ev";
BA_ "Match" SG_ 981 BMS_DTCNumber1 "BMS_DTCNumber1";
BA_ "GenSigCycleTime" SG_ 981 BMS_DTCNumber1 1000;
BA_ "Origin" SG_ 981 BMS_DTCNumber2 "ev";
BA_ "Match" SG_ 981 BMS_DTCNumber2 "BMS_DTCNumber2";
BA_ "GenSigCycleTime" SG_ 981 BMS_DTCNumber2 1000;
BA_ "Origin" SG_ 1009 BMS_SOCLowWarn "ev";
BA_ "Match" SG_ 1009 BMS_SOCLowWarn "BMS_SOCLowWarn";
BA_ "GenSigCycleTime" SG_ 1009 BMS_SOCLowWarn 1000;
BA_ "Origin" SG_ 1009 BMS_CellUnderVolt "ev";
BA_ "Match" SG_ 1009 BMS_CellUnderVolt "BMS_CellUnderVolt";
BA_ "GenSigCycleTime" SG_ 1009 BMS_CellUnderVolt 1000;
BA_ "Origin" SG_ 1009 BMS_CellOverVolt "ev";
BA_ "Match" SG_ 1009 BMS_CellOverVolt "BMS_CellOverVolt";
BA_ "GenSigCycleTime" SG_ 1009 BMS_CellOverVolt 1000;
BA_ "Origin" SG_ 1009 BMS_CellDeltaVolt "ev";
BA_ "Match" SG_ 1009 BMS_CellDeltaVolt "BMS_CellDeltaVolt";
BA_ "GenSigCycleTime" SG_ 1009 BMS_CellDeltaVolt 1000;
BA_ "Origin" SG_ 1009 BMS_BattUnderVolt "ev";
BA_ "Match" SG_ 1009 BMS_BattUnderVolt "BMS_BattUnderVolt";
BA_ "GenSigCycleTime" SG_ 1009 BMS_BattUnderVolt 1000;
BA_ "Origin" SG_ 1009 BMS_BattOverVolt "ev";
BA_ "Match" SG_ 1009 BMS_BattOverVolt "BMS_BattOverVolt";
BA_ "GenSigCycleTime" SG_ 1009 BMS_BattOverVolt 1000;
BA_ "Origin" SG_ 1009 BMS_BattUnderTemp "ev";
BA_ "Match" SG_ 1009 BMS_BattUnderTemp "BMS_BattUnderTemp";
BA_ "GenSigCycleTime" SG_ 1009 BMS_BattUnderTemp 1000;
BA_ "Origin" SG_ 1009 BMS_SOC_Plaucheck "ev";
BA_ "Match" SG_ 1009 BMS_SOC_Plaucheck "BMS_SOC_Plaucheck";
BA_ "GenSigCycleTime" SG_ 1009 BMS_SOC_Plaucheck 1000;
BA_ "Origin" SG_ 1009 BMS_DeltaTemp "ev";
BA_ "Match" SG_ 1009 BMS_DeltaTemp "BMS_DeltaTemp";
BA_ "GenSigCycleTime" SG_ 1009 BMS_DeltaTemp 1000;
BA_ "Origin" SG_ 1009 BMS_CANComErr "ev";
BA_ "Match" SG_ 1009 BMS_CANComErr "BMS_CANComErr";
BA_ "GenSigCycleTime" SG_ 1009 BMS_CANComErr 1000;
BA_ "Origin" SG_ 1009 BMS_BattSOCLow "ev";
BA_ "Match" SG_ 1009 BMS_BattSOCLow "BMS_BattSOCLow";
BA_ "GenSigCycleTime" SG_ 1009 BMS_BattSOCLow 1000;
BA_ "Origin" SG_ 1009 BMS_BattSOCTooLow "ev";
BA_ "Match" SG_ 1009 BMS_BattSOCTooLow "BMS_BattSOCTooLow";
BA_ "GenSigCycleTime" SG_ 1009 BMS_BattSOCTooLow 1000;
BA_ "Origin" SG_ 1009 BMS_BattSOCHigh "ev";
BA_ "Match" SG_ 1009 BMS_BattSOCHigh "BMS_BattSOCHigh";
BA_ "GenSigCycleTime" SG_ 1009 BMS_BattSOCHigh 1000;
BA_ "Origin" SG_ 1009 BMS_ChrgnCurrLager "ev";
BA_ "Match" SG_ 1009 BMS_ChrgnCurrLager "BMS_ChrgnCurrLager";
BA_ "GenSigCycleTime" SG_ 1009 BMS_ChrgnCurrLager 1000;
BA_ "Origin" SG_ 1009 BMS_DischrgnCurrLager "ev";
BA_ "Match" SG_ 1009 BMS_DischrgnCurrLager "BMS_DischrgnCurrLager";
BA_ "GenSigCycleTime" SG_ 1009 BMS_DischrgnCurrLager 1000;
BA_ "Origin" SG_ 1009 BMS_ModuleMismatchWarn "ev";
BA_ "Match" SG_ 1009 BMS_ModuleMismatchWarn "BMS_ModuleMismatchWarn";
BA_ "GenSigCycleTime" SG_ 1009 BMS_ModuleMismatchWarn 1000;
BA_ "Origin" SG_ 1009 BMS_cohrnc "ev";
BA_ "Match" SG_ 1009 BMS_cohrnc "BMS_cohrnc";
BA_ "GenSigCycleTime" SG_ 1009 BMS_cohrnc 1000;
BA_ "Origin" SG_ 1009 BMS_moduleNumber "ev";
BA_ "Match" SG_ 1009 BMS_moduleNumber "BMS_moduleNumber";
BA_ "GenSigStartValue" SG_ 1009 BMS_moduleNumber 1;
BA_ "GenSigCycleTime" SG_ 1009 BMS_moduleNumber 1000;
BA_ "Origin" SG_ 1009 BMS_NumModuleTempSnsr "ev";
BA_ "Match" SG_ 1009 BMS_NumModuleTempSnsr "BMS_NumModuleTempSnsr";
BA_ "GenSigStartValue" SG_ 1009 BMS_NumModuleTempSnsr 1;
BA_ "GenSigCycleTime" SG_ 1009 BMS_NumModuleTempSnsr 1000;
BA_ "Origin" SG_ 1009 BMS_NumCell "ev";
BA_ "Match" SG_ 1009 BMS_NumCell "BMS_NumCell";
BA_ "GenSigStartValue" SG_ 1009 BMS_NumCell 1;
BA_ "GenSigCycleTime" SG_ 1009 BMS_NumCell 1000;
BA_ "TransparentInitValue" SG_ 1009 BMS30_0x3F1 "0 0 0 1 1 1 0 0 ";
BA_ "GenSigCycleTime" SG_ 1009 BMS30_0x3F1 1000;
BA_ "Origin" SG_ 1010 BMS_CellVoltMin "ev";
BA_ "Match" SG_ 1010 BMS_CellVoltMin "BMS_CellVoltMin";
BA_ "GenSigCycleTime" SG_ 1010 BMS_CellVoltMin 1000;
BA_ "Origin" SG_ 1010 BMS_NumberCellVoltMin "ev";
BA_ "Match" SG_ 1010 BMS_NumberCellVoltMin "BMS_NumberCellVoltMin";
BA_ "GenSigCycleTime" SG_ 1010 BMS_NumberCellVoltMin 1000;
BA_ "Origin" SG_ 1010 BMS_CellMaxVolt "ev";
BA_ "Match" SG_ 1010 BMS_CellMaxVolt "BMS_CellMaxVolt";
BA_ "GenSigCycleTime" SG_ 1010 BMS_CellMaxVolt 1000;
BA_ "Origin" SG_ 1010 BMS_NumberCellMaxVolt "ev";
BA_ "Match" SG_ 1010 BMS_NumberCellMaxVolt "BMS_NumberCellMaxVolt";
BA_ "GenSigCycleTime" SG_ 1010 BMS_NumberCellMaxVolt 1000;
BA_ "Origin" SG_ 1010 BMS_CellBalanceSts "ev";
BA_ "Match" SG_ 1010 BMS_CellBalanceSts "BMS_CellBalanceSts";
BA_ "GenSigCycleTime" SG_ 1010 BMS_CellBalanceSts 1000;
BA_ "Origin" SG_ 1010 BMS_RlyCounterSts "ev";
BA_ "Match" SG_ 1010 BMS_RlyCounterSts "BMS_RlyCounterSts";
BA_ "GenSigCycleTime" SG_ 1010 BMS_RlyCounterSts 1000;
BA_ "Origin" SG_ 1010 BMS_SOH_R "ev";
BA_ "Match" SG_ 1010 BMS_SOH_R "BMS_SOH_R";
BA_ "GenSigCycleTime" SG_ 1010 BMS_SOH_R 1000;
BA_ "Origin" SG_ 1011 BMS_ModuleMinTemp "ev";
BA_ "Match" SG_ 1011 BMS_ModuleMinTemp "BMS_ModuleMinTemp";
BA_ "GenSigStartValue" SG_ 1011 BMS_ModuleMinTemp 65;
BA_ "GenSigCycleTime" SG_ 1011 BMS_ModuleMinTemp 1000;
BA_ "Origin" SG_ 1011 BMS_ModuleNumCellMinTemp "ev";
BA_ "Match" SG_ 1011 BMS_ModuleNumCellMinTemp "BMS_ModuleNumCellMinTemp";
BA_ "GenSigStartValue" SG_ 1011 BMS_ModuleNumCellMinTemp 1;
BA_ "GenSigCycleTime" SG_ 1011 BMS_ModuleNumCellMinTemp 1000;
BA_ "Origin" SG_ 1011 BMS_ModuleNumCellMaxTemp "ev";
BA_ "Match" SG_ 1011 BMS_ModuleNumCellMaxTemp "BMS_ModuleNumCellMaxTemp";
BA_ "GenSigStartValue" SG_ 1011 BMS_ModuleNumCellMaxTemp 1;
BA_ "GenSigCycleTime" SG_ 1011 BMS_ModuleNumCellMaxTemp 1000;
BA_ "Origin" SG_ 1011 BMS_ModuleMaxTemp "ev";
BA_ "Match" SG_ 1011 BMS_ModuleMaxTemp "BMS_ModuleMaxTemp";
BA_ "GenSigStartValue" SG_ 1011 BMS_ModuleMaxTemp 65;
BA_ "GenSigCycleTime" SG_ 1011 BMS_ModuleMaxTemp 1000;
BA_ "Origin" SG_ 1011 BMS_NumCellMinTemp "ev";
BA_ "Match" SG_ 1011 BMS_NumCellMinTemp "BMS_NumCellMinTemp";
BA_ "GenSigStartValue" SG_ 1011 BMS_NumCellMinTemp 1;
BA_ "GenSigCycleTime" SG_ 1011 BMS_NumCellMinTemp 1000;
BA_ "Origin" SG_ 1011 BMS_NumCellMaxTemp "ev";
BA_ "Match" SG_ 1011 BMS_NumCellMaxTemp "BMS_NumCellMaxTemp";
BA_ "GenSigStartValue" SG_ 1011 BMS_NumCellMaxTemp 1;
BA_ "GenSigCycleTime" SG_ 1011 BMS_NumCellMaxTemp 1000;
BA_ "Origin" SG_ 1011 BMS_PackMismatchWarn "ev";
BA_ "Match" SG_ 1011 BMS_PackMismatchWarn "BMS_PackMismatchWarn";
BA_ "GenSigCycleTime" SG_ 1011 BMS_PackMismatchWarn 1000;
BA_ "Origin" SG_ 1011 BMS_OverChargeErr "ev";
BA_ "Match" SG_ 1011 BMS_OverChargeErr "BMS_OverChargeErr";
BA_ "GenSigCycleTime" SG_ 1011 BMS_OverChargeErr 1000;
BA_ "Origin" SG_ 1011 BMS_IsolationErr "ev";
BA_ "Match" SG_ 1011 BMS_IsolationErr "BMS_IsolationErr";
BA_ "GenSigCycleTime" SG_ 1011 BMS_IsolationErr 1000;
BA_ "Origin" SG_ 1011 BMS_HVILErr "ev";
BA_ "Match" SG_ 1011 BMS_HVILErr "BMS_HVILErr";
BA_ "GenSigCycleTime" SG_ 1011 BMS_HVILErr 1000;
BA_ "Origin" SG_ 1011 BMS_BattOverTempWarn "ev";
BA_ "Match" SG_ 1011 BMS_BattOverTempWarn "BMS_BattOverTempWarn";
BA_ "GenSigCycleTime" SG_ 1011 BMS_BattOverTempWarn 1000;
BA_ "Origin" SG_ 1011 BMS_ModuleNumberCellMinVolt "ev";
BA_ "Match" SG_ 1011 BMS_ModuleNumberCellMinVolt "BMS_ModuleNumberCellMinVolt";
BA_ "GenSigStartValue" SG_ 1011 BMS_ModuleNumberCellMinVolt 1;
BA_ "GenSigCycleTime" SG_ 1011 BMS_ModuleNumberCellMinVolt 1000;
BA_ "Origin" SG_ 1011 BMS_ModuleNumberCellMaxVolt "ev";
BA_ "Match" SG_ 1011 BMS_ModuleNumberCellMaxVolt "BMS_ModuleNumberCellMaxVolt";
BA_ "GenSigStartValue" SG_ 1011 BMS_ModuleNumberCellMaxVolt 1;
BA_ "GenSigCycleTime" SG_ 1011 BMS_ModuleNumberCellMaxVolt 1000;
BA_ "Origin" SG_ 130 NetEngTrq "fuel";
BA_ "Match" SG_ 130 NetEngTrq "NetEngTrq";
BA_ "GenSigStartValue" SG_ 130 NetEngTrq 32767;
BA_ "GenSigCycleTime" SG_ 130 NetEngTrq 10;
BA_ "Origin" SG_ 130 DrvEngTrqReq "fuel";
BA_ "Match" SG_ 130 DrvEngTrqReq "DrvEngTrqReq";
BA_ "GenSigStartValue" SG_ 130 DrvEngTrqReq 32767;
BA_ "GenSigCycleTime" SG_ 130 DrvEngTrqReq 10;
BA_ "TransparentInitValue" SG_ 130 ECM4_0x82 "0 127 255 127 255 0 0 0 ";
BA_ "GenSigCycleTime" SG_ 130 ECM4_0x82 10;
BA_ "Origin" SG_ 132 HCU_RaceLaunchAvail_0x84 "fuel";
BA_ "Match" SG_ 132 HCU_RaceLaunchAvail_0x84 "HCU_RaceLaunchAvail";
BA_ "GenSigCycleTime" SG_ 132 HCU_RaceLaunchAvail_0x84 10;
BA_ "Origin" SG_ 132 HCU_RaceLaunchSts_0x84 "fuel";
BA_ "Match" SG_ 132 HCU_RaceLaunchSts_0x84 "HCU_RaceLaunchSts";
BA_ "GenSigCycleTime" SG_ 132 HCU_RaceLaunchSts_0x84 10;
BA_ "TransparentInitValue" SG_ 132 ECM7_0x84 "0 0 0 0 0 0 0 0 ";
BA_ "GenSigCycleTime" SG_ 132 ECM7_0x84 10;
BA_ "Origin" SG_ 158 HCU_PowertrainSts_0x9e "fuel";
BA_ "Match" SG_ 158 HCU_PowertrainSts_0x9e "HCU_PowertrainSts";
BA_ "GenSigCycleTime" SG_ 158 HCU_PowertrainSts_0x9e 10;
BA_ "Origin" SG_ 158 HCU_TotDrvReqPower_0x9e "fuel";
BA_ "Match" SG_ 158 HCU_TotDrvReqPower_0x9e "HCU_TotDrvReqPower";
BA_ "GenSigStartValue" SG_ 158 HCU_TotDrvReqPower_0x9e 100;
BA_ "GenSigCycleTime" SG_ 158 HCU_TotDrvReqPower_0x9e 10;
BA_ "Origin" SG_ 158 TgtRcprtnTrqSts "fuel";
BA_ "Match" SG_ 158 TgtRcprtnTrqSts "TgtRcprtnTrqSts";
BA_ "GenSigCycleTime" SG_ 158 TgtRcprtnTrqSts 10;
BA_ "TransparentInitValue" SG_ 158 HCU_HC16_0x9E "0 0 0 1 144 0 0 0 ";
BA_ "GenSigCycleTime" SG_ 158 HCU_HC16_0x9E 10;
BA_ "Origin" SG_ 258 AccelPedlPosnDiagc "fuel";
BA_ "Match" SG_ 258 AccelPedlPosnDiagc "AccelPedlPosnDiagc";
BA_ "GenSigCycleTime" SG_ 258 AccelPedlPosnDiagc 20;
BA_ "TransparentInitValue" SG_ 258 ECM9_0x102 "0 0 0 0 0 0 0 0 ";
BA_ "GenSigCycleTime" SG_ 258 ECM9_0x102 20;
BA_ "Origin" SG_ 335 BMS_BattSOC_P0 "fuel";
BA_ "Match" SG_ 335 BMS_BattSOC_P0 "BMS_BattSOC_P0";
BA_ "GenSigCycleTime" SG_ 335 BMS_BattSOC_P0 20;
BA_ "TransparentInitValue" SG_ 335 BMS65_0x14F "0 0 0 0 0 0 0 0 ";
BA_ "GenSigCycleTime" SG_ 335 BMS65_0x14F 20;
BA_ "Origin" SG_ 486 MultiColorNr1 "fuel";
BA_ "Match" SG_ 486 MultiColorNr1 "MultiColorNr1";
BA_ "GenSigStartValue" SG_ 486 MultiColorNr1 8;
BA_ "GenSigSendType" SG_ 486 MultiColorNr1 2;
BA_ "Origin" SG_ 486 MultiColorNr2 "fuel";
BA_ "Match" SG_ 486 MultiColorNr2 "MultiColorNr2";
BA_ "GenSigStartValue" SG_ 486 MultiColorNr2 9;
BA_ "GenSigSendType" SG_ 486 MultiColorNr2 2;
BA_ "Origin" SG_ 486 MultiColorNr3 "fuel";
BA_ "Match" SG_ 486 MultiColorNr3 "MultiColorNr3";
BA_ "GenSigStartValue" SG_ 486 MultiColorNr3 1;
BA_ "GenSigSendType" SG_ 486 MultiColorNr3 2;
BA_ "Origin" SG_ 486 MultiColorNr4 "fuel";
BA_ "Match" SG_ 486 MultiColorNr4 "MultiColorNr4";
BA_ "GenSigSendType" SG_ 486 MultiColorNr4 2;
BA_ "Origin" SG_ 486 MultiColorNr5 "fuel";
BA_ "Match" SG_ 486 MultiColorNr5 "MultiColorNr5";
BA_ "GenSigSendType" SG_ 486 MultiColorNr5 2;
BA_ "Origin" SG_ 486 MultiColorNr6 "fuel";
BA_ "Match" SG_ 486 MultiColorNr6 "MultiColorNr6";
BA_ "GenSigSendType" SG_ 486 MultiColorNr6 2;
BA_ "Origin" SG_ 486 MultiColorNr7 "fuel";
BA_ "Match" SG_ 486 MultiColorNr7 "MultiColorNr7";
BA_ "GenSigSendType" SG_ 486 MultiColorNr7 2;
BA_ "Origin" SG_ 486 MultiColorNr8 "fuel";
BA_ "Match" SG_ 486 MultiColorNr8 "MultiColorNr8";
BA_ "GenSigSendType" SG_ 486 MultiColorNr8 2;
BA_ "TransparentInitValue" SG_ 486 HUT36_0x1E6 "16 18 2 0 0 0 0 0 ";
BA_ "GenSigSendType" SG_ 486 HUT36_0x1E6 2;
BA_ "Origin" SG_ 492 MultiColorNr9 "fuel";
BA_ "Match" SG_ 492 MultiColorNr9 "MultiColorNr9";
BA_ "GenSigSendType" SG_ 492 MultiColorNr9 2;
BA_ "Origin" SG_ 492 MultiColorNr10 "fuel";
BA_ "Match" SG_ 492 MultiColorNr10 "MultiColorNr10";
BA_ "GenSigSendType" SG_ 492 MultiColorNr10 2;
BA_ "Origin" SG_ 492 MultiColorNr11 "fuel";
BA_ "Match" SG_ 492 MultiColorNr11 "MultiColorNr11";
BA_ "GenSigSendType" SG_ 492 MultiColorNr11 2;
BA_ "Origin" SG_ 492 MultiColorNr12 "fuel";
BA_ "Match" SG_ 492 MultiColorNr12 "MultiColorNr12";
BA_ "GenSigSendType" SG_ 492 MultiColorNr12 2;
BA_ "Origin" SG_ 492 MultiColorNr13 "fuel";
BA_ "Match" SG_ 492 MultiColorNr13 "MultiColorNr13";
BA_ "GenSigSendType" SG_ 492 MultiColorNr13 2;
BA_ "Origin" SG_ 492 MultiColorNr14 "fuel";
BA_ "Match" SG_ 492 MultiColorNr14 "MultiColorNr14";
BA_ "GenSigSendType" SG_ 492 MultiColorNr14 2;
BA_ "Origin" SG_ 492 MultiColorNr15 "fuel";
BA_ "Match" SG_ 492 MultiColorNr15 "MultiColorNr15";
BA_ "GenSigSendType" SG_ 492 MultiColorNr15 2;
BA_ "Origin" SG_ 492 MultiColorNr16 "fuel";
BA_ "Match" SG_ 492 MultiColorNr16 "MultiColorNr16";
BA_ "GenSigSendType" SG_ 492 MultiColorNr16 2;
BA_ "TransparentInitValue" SG_ 492 HUT37_0x1EC "0 0 0 0 0 0 0 0 ";
BA_ "GenSigSendType" SG_ 492 HUT37_0x1EC 2;
BA_ "Origin" SG_ 724 DPF_Warning "fuel";
BA_ "Match" SG_ 724 DPF_Warning "DPF_Warning";
BA_ "GenSigCycleTime" SG_ 724 DPF_Warning 100;
BA_ "Origin" SG_ 724 WIFSensorFailSts "fuel";
BA_ "Match" SG_ 724 WIFSensorFailSts "WIFSensorFailSts";
BA_ "GenSigCycleTime" SG_ 724 WIFSensorFailSts 100;
BA_ "Origin" SG_ 724 GlowPlugLmpCmd "fuel";
BA_ "Match" SG_ 724 GlowPlugLmpCmd "GlowPlugLmpCmd";
BA_ "GenSigCycleTime" SG_ 724 GlowPlugLmpCmd 100;
BA_ "Origin" SG_ 724 UreaLampCmd "fuel";
BA_ "Match" SG_ 724 UreaLampCmd "UreaLampCmd";
BA_ "GenSigCycleTime" SG_ 724 UreaLampCmd 100;
BA_ "Origin" SG_ 724 Urea_Level "fuel";
BA_ "Match" SG_ 724 Urea_Level "Urea_Level";
BA_ "GenSigCycleTime" SG_ 724 Urea_Level 100;
BA_ "Origin" SG_ 724 UreaRemainDist "fuel";
BA_ "Match" SG_ 724 UreaRemainDist "UreaRemainDist";
BA_ "GenSigCycleTime" SG_ 724 UreaRemainDist 100;
BA_ "Origin" SG_ 724 SCRSysWarnDisplay "fuel";
BA_ "Match" SG_ 724 SCRSysWarnDisplay "SCRSysWarnDisplay";
BA_ "GenSigCycleTime" SG_ 724 SCRSysWarnDisplay 100;
BA_ "Origin" SG_ 724 WIFFullLmpCmd "fuel";
BA_ "Match" SG_ 724 WIFFullLmpCmd "WIFFullLmpCmd";
BA_ "GenSigCycleTime" SG_ 724 WIFFullLmpCmd 100;
BA_ "Origin" SG_ 724 DPF_Activation "fuel";
BA_ "Match" SG_ 724 DPF_Activation "DPF_Activation";
BA_ "GenSigCycleTime" SG_ 724 DPF_Activation 100;
BA_ "TransparentInitValue" SG_ 724 ECM16_0x2D4 "0 0 0 0 0 0 0 0 ";
BA_ "GenSigCycleTime" SG_ 724 ECM16_0x2D4 100;
BA_ "Origin" SG_ 763 VMDR_TmpMonFctnSts "fuel";
BA_ "Match" SG_ 763 VMDR_TmpMonFctnSts "VMDR_TmpMonFctnSts";
BA_ "GenSigCycleTime" SG_ 763 VMDR_TmpMonFctnSts 100;
BA_ "Origin" SG_ 763 VMDR_InitAlarmDlySetSts "fuel";
BA_ "Match" SG_ 763 VMDR_InitAlarmDlySetSts "VMDR_InitAlarmDlySetSts";
BA_ "GenSigCycleTime" SG_ 763 VMDR_InitAlarmDlySetSts 100;
BA_ "Origin" SG_ 763 VMDR_FctnSts "fuel";
BA_ "Match" SG_ 763 VMDR_FctnSts "VMDR_FctnSts";
BA_ "GenSigCycleTime" SG_ 763 VMDR_FctnSts 100;
BA_ "TransparentInitValue" SG_ 763 VMDR1_0x2FB "0 0 0 0 0 0 0 0 ";
BA_ "GenSigCycleTime" SG_ 763 VMDR1_0x2FB 100;
BA_ "Origin" SG_ 848 EngOilLvlWrn "fuel";
BA_ "Match" SG_ 848 EngOilLvlWrn "EngOilLvlWrn";
BA_ "GenSigCycleTime" SG_ 848 EngOilLvlWrn 500;
BA_ "Origin" SG_ 848 EngOilLowPresWrn "fuel";
BA_ "Match" SG_ 848 EngOilLowPresWrn "EngOilLowPresWrn";
BA_ "GenSigCycleTime" SG_ 848 EngOilLowPresWrn 500;
BA_ "Origin" SG_ 848 EngOilPres "fuel";
BA_ "Match" SG_ 848 EngOilPres "EngOilPres";
BA_ "GenSigCycleTime" SG_ 848 EngOilPres 500;
BA_ "Origin" SG_ 848 EngOilTemp "fuel";
BA_ "Match" SG_ 848 EngOilTemp "EngOilTemp";
BA_ "GenSigCycleTime" SG_ 848 EngOilTemp 500;
BA_ "TransparentInitValue" SG_ 848 ECM24_0x350 "0 0 0 0 0 0 0 0 ";
BA_ "GenSigCycleTime" SG_ 848 ECM24_0x350 500;
BA_ "Origin" SG_ 1560 DVR_Phy_Req "fuel";
BA_ "Match" SG_ 1560 DVR_Phy_Req "DVR_Phy_Req";
BA_ "Origin" SG_ 1561 DVR_Phy_Resp "fuel";
BA_ "Match" SG_ 1561 DVR_Phy_Resp "DVR_Phy_Resp";
BA_ "Origin" SG_ 1303 Destination_DVR_NM "fuel";
BA_ "Match" SG_ 1303 Destination_DVR_NM "Destination_DVR_NM";
BA_ "Origin" SG_ 1303 OpCode_DVR_NM "fuel";
BA_ "Match" SG_ 1303 OpCode_DVR_NM "OpCode_DVR_NM";
VAL_ 482 HCU_PhoneChrgnModeResp 0 "inactive" 1 "active" ;
VAL_ 482 HCU_PhoneChrgnReqResp 0 "inactive" 1 "active" ;
VAL_ 482 HCU_HUTChrgnModeResp 0 "inactive" 1 "active" ;
VAL_ 482 HCU_HUTChrgnReqResp 0 "inactive" 1 "active" ;
VAL_ 482 HCU_TboxEngStrtReq 0 "NO Request" 1 "Request" ;
VAL_ 482 HCU_TotalScore 0 "Valid value" 5 "Valid value" 6 "Reserved" 7 "Reserved" ;
VAL_ 483 BMS_ChrgTimResp 0 "inactive" 1 "active" ;
VAL_ 510 T_BOX_RemtDrvSeatHeatgLvlSet_Nin 0 "No action" 1 "OFF" 2 "Level1_Low" 3 "Level2" 4 "Level3" 5 "Level4" 6 "Level5" 7 "Level6" 8 "Level7" 9 "Level8" 10 "Level9_High" 11 "Reserved" 15 "Reserved" ;
VAL_ 510 T_BOX_RemtPassSeatHeatgLvlSet_Ni 0 "No action" 1 "OFF" 2 "Level1_Low" 3 "Level2" 4 "Level3" 5 "Level4" 6 "Level5" 7 "Level6" 8 "Level7" 9 "Level8" 10 "Level9_High" 11 "Reserved" 15 "Reserved" ;
VAL_ 510 T_BOX_RemtSecRowLeSeatHeatgLvlSe 0 "No action" 1 "OFF" 2 "Level1_Low" 3 "Level2" 4 "Level3" 5 "Level4" 6 "Level5" 7 "Level6" 8 "Level7" 9 "Level8" 10 "Level9_High" 11 "Reserved" 15 "Reserved" ;
VAL_ 510 T_BOX_RemtSecRowRiSeatHeatgLvlSe 0 "No action" 1 "OFF" 2 "Level1_Low" 3 "Level2" 4 "Level3" 5 "Level4" 6 "Level5" 7 "Level6" 8 "Level7" 9 "Level8" 10 "Level9_High" 11 "Reserved" 15 "Reserved" ;
VAL_ 510 T_BOX_ChrgTim_Hour 0 "Valid hour" 23 "Valid hour" 24 "Reserved" 30 "Reserved" 31 "Invalid" ;
VAL_ 510 T_BOX_ChrgTim_Minutes 0 "Valid minute" 59 "Valid minute" 60 "Reserved" 62 "Reserved" 63 "Invalid" ;
VAL_ 510 T_BOX_ChrgTim_Second 0 "Valid second" 59 "Valid second" 60 "Reserved" 62 "Reserved" 63 "Invalid" ;
VAL_ 510 T_BOX_ChrgTim_Year_Left 0 "Valid year" 9 "Valid year" 10 "Reserved" 14 "Reserved" 15 "Invalid" ;
VAL_ 510 T_BOX_ChrgTim_Year_Right 0 "Valid year" 9 "Valid year" 10 "Reserved" 14 "Reserved" 15 "Invalid" ;
VAL_ 510 T_BOX_ChrgTim_Month 0 "Invalid" 1 "Valid month" 12 "Valid month" 13 "Reserved" 15 "Reserved" ;
VAL_ 510 T_BOX_ChrgTim_Day 0 "Invalid" 1 "Valid day" 31 "Valid day" ;
VAL_ 513 HCU_V2LReminder 0 "Default" 1 "Need_press_start_stop_button_to_use_V2L" 2 "V2L_failed_to_activate_execute" 3 "Reserved" ;
VAL_ 513 HCU_SOCMngmntSts 0 "OFF" 1 "ON" ;
VAL_ 513 HCU_ARFSts 0 "OFF" 1 "ON" ;
VAL_ 513 HCU_ASFCSts 0 "OFF" 1 "ON" ;
VAL_ 513 HCU_AGSSts 0 "OFF" 1 "ON" ;
VAL_ 513 PDCU_AvailabilityOfARF 0 "Available" 1 "Prohibited_error" 2 "Prohibited_sensor_missing" 3 "Prohibited_intelligent_function_activated" 4 "Prohibited_ESP_activated" 5 "Deactivated" ;
VAL_ 513 PDCU_lossenPedalPrompt 0 "No_Prompt" 1 "Prompt" ;
VAL_ 513 PDCU_EvSave_disl 0 "Not_Active" 1 "Active" ;
VAL_ 515 HUT_OD_Obj0_ID 0 "Valid values" 9 "Valid values" 10 "Invalid values" 15 "Invalid values" ;
VAL_ 515 HUT_OD_Obj0_type 0 "No target" 1 "Pedestrian or Biker" 2 "Vehicle" 3 "Ground Locker or Barrier" 4 "Unknown type" 5 "Invalid values" 7 "Invalid values" ;
VAL_ 515 HUT_OD_Obj0_Confidence 0 "0-1" 10 "0-1" 11 "Invalid values" 15 "Invalid values" ;
VAL_ 515 HUT_OD_Obj0_width 0 "Valid values" 126 "Valid values" 127 "Invalid values" ;
VAL_ 515 HUT_OD_Obj0_Ground_Pos_X 0 "Valid values" 4000 "Valid values" 4001 "Reserved" 4094 "Reserved" 4095 "Invalid values" ;
VAL_ 515 HUT_OD_Obj0_Ground_Pos_Y 0 "Valid values" 4000 "Valid values" 4001 "Reserved" 4094 "Reserved" 4095 "Invalid values" ;
VAL_ 515 HTU_OD_Obj1_ID 0 "Valid values" 9 "Valid values" 10 "Invalid values" 15 "Invalid values" ;
VAL_ 515 HUT_OD_Obj1_type 0 "No target" 1 "Pedestrian or Biker" 2 "Vehicle" 3 "Ground Locker or Barrier" 4 "Unknown type" 5 "Invalid values" 7 "Invalid values" ;
VAL_ 515 HUT_OD_Obj1_Confidence 0 "0-1" 10 "0-1" 11 "Invalid values" 15 "Invalid values" ;
VAL_ 515 HUT_OD_Obj1_width 0 "Valid values" 126 "Valid values" 127 "Invalid values" ;
VAL_ 515 HUT_OD_Obj1_Ground_Pos_X 0 "Valid values" 4000 "Valid values" 4001 "Reserved" 4094 "Reserved" 4095 "Invalid values" ;
VAL_ 515 HUT_OD_Obj1_Ground_Pos_Y 0 "Valid values" 4000 "Valid values" 4001 "Reserved" 4094 "Reserved" 4095 "Invalid values" ;
VAL_ 515 HUT_OD_Obj2_ID 0 "Valid values" 9 "Valid values" 10 "Invalid values" 15 "Invalid values" ;
VAL_ 515 HUT_OD_Obj2_type 0 "No target" 1 "Pedestrian or Biker" 2 "Vehicle" 3 "Ground Locker or Barrier" 4 "Unknown type" 5 "Invalid values" 7 "Invalid values" ;
VAL_ 515 HUT_OD_Obj2_Confidence 0 "0-1" 10 "0-1" 11 "Invalid values" 15 "Invalid values" ;
VAL_ 515 HUT_OD_Obj2_width 0 "Valid values" 126 "Valid values" 127 "Invalid values" ;
VAL_ 515 HUT_OD_Obj2_Ground_Pos_X 0 "Valid values" 4000 "Valid values" 4001 "Reserved" 4094 "Reserved" 4095 "Invalid values" ;
VAL_ 515 HUT_OD_Obj2_Ground_Pos_Y 0 "Valid values" 4000 "Valid values" 4001 "Reserved" 4094 "Reserved" 4095 "Invalid values" ;
VAL_ 515 HUT_OD_Obj3_ID 0 "Valid values" 9 "Valid values" 10 "Invalid values" 15 "Invalid values" ;
VAL_ 515 HUT_OD_Obj3_type 0 "No target" 1 "Pedestrian or Biker" 2 "Vehicle" 3 "Ground Locker or Barrier" 4 "Unknown type" 5 "Invalid values" 7 "Invalid values" ;
VAL_ 515 HUT_OD_Obj3_Confidence 0 "0-1" 10 "0-1" 11 "Invalid values" 15 "Invalid values" ;
VAL_ 515 HUT_OD_Obj3_width 0 "Valid values" 126 "Valid values" 127 "Invalid values" ;
VAL_ 515 HUT_OD_Obj3_Ground_Pos_X 0 "Valid values" 4000 "Valid values" 4001 "Reserved" 4094 "Reserved" 4095 "Invalid values" ;
VAL_ 515 HUT_OD_Obj3_Ground_Pos_Y 0 "Valid values" 4000 "Valid values" 4001 "Reserved" 4094 "Reserved" 4095 "Invalid values" ;
VAL_ 515 HUT_OD_Obj4_ID 0 "Valid values" 9 "Valid values" 10 "Invalid values" 15 "Invalid values" ;
VAL_ 515 HUT_OD_Obj4_type 0 "No target" 1 "Pedestrian or Biker" 2 "Vehicle" 3 "Ground Locker or Barrier" 4 "Unknown type" 5 "Invalid values" 7 "Invalid values" ;
VAL_ 515 HUT_OD_Obj4_Confidence 0 "0-1" 10 "0-1" 11 "Invalid values" 15 "Invalid values" ;
VAL_ 515 HUT_OD_Obj4_width 0 "Valid values" 126 "Valid values" 127 "Invalid values" ;
VAL_ 515 HUT_OD_Obj4_Ground_Pos_X 0 "Valid values" 4000 "Valid values" 4001 "Reserved" 4094 "Reserved" 4095 "Invalid values" ;
VAL_ 515 HUT_OD_Obj4_Ground_Pos_Y 0 "Valid values" 4000 "Valid values" 4001 "Reserved" 4094 "Reserved" 4095 "Invalid values" ;
VAL_ 515 HUT_OD_Obj5_ID 0 "Valid values" 9 "Valid values" 10 "Invalid values" 15 "Invalid values" ;
VAL_ 515 HUT_OD_Obj5_type 0 "No target" 1 "Pedestrian or Biker" 2 "Vehicle" 3 "Ground Locker or Barrier" 4 "Unknown type" 5 "Invalid values" 7 "Invalid values" ;
VAL_ 515 HUT_OD_Obj5_Confidence 0 "0-1" 10 "0-1" 11 "Invalid values" 15 "Invalid values" ;
VAL_ 515 HUT_OD_Obj5_width 0 "Valid values" 126 "Valid values" 127 "Invalid values" ;
VAL_ 515 HUT_OD_Obj5_Ground_Pos_X 0 "Valid values" 4000 "Valid values" 4001 "Reserved" 4094 "Reserved" 4095 "Invalid values" ;
VAL_ 515 HUT_OD_Obj5_Ground_Pos_Y 0 "Valid values" 4000 "Valid values" 4001 "Reserved" 4094 "Reserved" 4095 "Invalid values" ;
VAL_ 515 HUT_OD_Obj6_ID 0 "Valid values" 9 "Valid values" 10 "Invalid values" 15 "Invalid values" ;
VAL_ 515 HUT_OD_Obj6_type 0 "No target" 1 "Pedestrian or Biker" 2 "Vehicle" 3 "Ground Locker or Barrier" 4 "Unknown type" 5 "Invalid values" 7 "Invalid values" ;
VAL_ 515 HUT_OD_Obj6_Confidence 0 "0-1" 10 "0-1" 11 "Invalid values" 15 "Invalid values" ;
VAL_ 515 HUT_OD_Obj6_width 0 "Valid values" 126 "Valid values" 127 "Invalid values" ;
VAL_ 515 HUT_OD_Obj6_Ground_Pos_X 0 "Valid values" 4000 "Valid values" 4001 "Reserved" 4094 "Reserved" 4095 "Invalid values" ;
VAL_ 515 HUT_OD_Obj6_Ground_Pos_Y 0 "Valid values" 4000 "Valid values" 4001 "Reserved" 4094 "Reserved" 4095 "Invalid values" ;
VAL_ 616 HCU_ChrgDchrgSts 0 "Charging" 1 "Discharging" 2 "Invalid" 3 "Reserved" ;
VAL_ 616 HCU_BattLowTempWarn 0 "Normal" 1 "Battery temperature is too low, plug in heating" 2 "Reserved" 3 "Reserved" ;
VAL_ 616 HCU_BattLowTempHeatSts 0 "Normal" 1 "Battery heating complete" 2 "Reserved" 3 "Reserved" ;
VAL_ 645 BMS_BattHeatRunaway 0 "inactive" 1 "running thermalrunaway" 2 "parking thermalrunaway" 3 "reserved" ;
VAL_ 645 BMS_DisSOC1 0 "Valid value" 100 "Valid value" 101 "Reserved" 254 "Reserved" 255 "Invalid" ;
VAL_ 690 ExpertModReq_HUT_HCU 0 "AutoNormal Mode" 1 "EV Mode" 2 "Save Mode" 3 "Reserved" ;
VAL_ 708 BMS_BattSOCLimResp 0 "100%" 1 "50%" 2 "60%" 3 "70%" 4 "80%" 5 "90%" 6 "Invalid" 7 "reserved" ;
VAL_ 743 RFPosnLmpWorkCmd 0 "OFF" 1 "ON" ;
VAL_ 743 LFPosnLmpWorkCmd 0 "OFF" 1 "ON" ;
VAL_ 743 HiBeamWorkCmd 0 "OFF" 1 "ON" ;
VAL_ 743 LowBeamWorkCmd 0 "OFF" 1 "ON" ;
VAL_ 743 RTurnLmpWorkCmd 0 "OFF" 1 "ON" ;
VAL_ 743 LTurnLampWorkCmd 0 "OFF" 1 "ON" ;
VAL_ 743 RDayRunngLmpWorkCmd 0 "OFF" 1 "ON" ;
VAL_ 743 LDayRunngLmpWorkCmd 0 "OFF" 1 "ON" ;
VAL_ 743 RFFogLmpWorkCmd 0 "OFF" 1 "ON" ;
VAL_ 743 LFFogLmpWorkCmd 0 "OFF" 1 "ON" ;
VAL_ 743 LicPlateLmpWorkCmd 0 "OFF" 1 "ON" ;
VAL_ 743 ReversLampWorkCmd 0 "OFF" 1 "ON" ;
VAL_ 743 BrkLmpWorkCmd 0 "OFF" 1 "ON" ;
VAL_ 743 RFogLmpWorkCmd 0 "OFF" 1 "ON" ;
VAL_ 743 RRPosnLmpWorkCmd 0 "OFF" 1 "ON" ;
VAL_ 743 LRPosnLmpWorkCmd 0 "OFF" 1 "ON" ;
VAL_ 788 HCU_ACLineDisconnect 0 "Init" 1 "Not connect" 2 "connect" 3 "Reserved" ;
VAL_ 788 HCU_ChargSts 0 "Default" 1 "Charging(Ã¥Â…Â…Ã§Â”ÂµÃ¤Â¸Â­)" 2 "Delaying" 3 "Charge complete" 4 "Charge stopped" 5 "Charge Initialize" 6 "Charging Heating(Ã¦ÂÂ’Ã¦ÂžÂªÃ¤Â»Â…Ã¥ÂŠÂ Ã§ÂƒÂ­)" 7 "Fault" ;
VAL_ 788 HCU_IntelBattTempMagSts 0 "Off" 1 "On" ;
VAL_ 790 OBC_ModSts 0 "Discharging" 1 "Init" 2 "Standby" 3 "Heating" 4 "Charging Normal" 5 "Reserved" 7 "Reserved" 8 "Fault" 9 "Reduced Power" 10 "Reserved" 11 "Sleep (Shutdown)" 12 "OFF" 13 "Reserved" 15 "Reserved" ;
VAL_ 791 OBC_ConnectSts 0 "Not connected" 1 "Connected" 2 "Error" 3 "Discharge connected" ;
VAL_ 829 T_BOX_RemtLRTempSet 0 "No action" 1 "Valid Value(Phys = 0.5 * raw + 16)" 31 "Valid Value(Phys = 0.5 * raw + 16)" 32 "Reserved" 63 "Reserved" ;
VAL_ 829 T_BOX_RemtRRTempSet 0 "No action" 1 "Valid Value(Phys = 0.5 * raw + 16)" 31 "Valid Value(Phys = 0.5 * raw + 16)" 32 "Reserved" 63 "Reserved" ;
VAL_ 829 T_BOX_RemtRearAutoCtrl 0 "No action" 1 "OFF" 2 "ON" 3 "Reserved" ;
VAL_ 829 T_BOX_RemtSecRowLeSeatVentnLvlSe 0 "No Action" 1 "OFF" 2 "Level1_Low" 3 "Level2_Middle" 4 "Level3_High" 5 "Reserved" 7 "Reserved" ;
VAL_ 829 T_BOX_RemtSecRowRiSeatVentnLvlSe 0 "No Action" 1 "OFF" 2 "Level1_Low" 3 "Level2_Middle" 4 "Level3_High" 5 "Reserved" 7 "Reserved" ;
VAL_ 829 T_BOX_MbrMonrEnReq 0 "No action" 1 "Disable" 2 "Enable" 3 "Reserved" ;
VAL_ 829 ReleAlarm_APP 0 "No Action" 1 "Relieve alarm" 2 "Alarm" 3 "Reserved" ;
VAL_ 829 T_BOX_RemtSteerWheelHeatCtrl 0 "No Action" 1 "OFF" 2 "ON" 3 "Reserved" ;
VAL_ 829 T_BOX_AVPActvReq 0 "No Request" 1 "Request HAVP" 2 "Request PAVP" 3 "Reserved" ;
VAL_ 850 BMS_IntelEngIdlChrgnSts 0 "Default" 1 "ON" 2 "Off" 3 "Reserved" ;
VAL_ 850 BMS_BattKeepTempSts 0 "Off" 1 "On" ;
VAL_ 865 HCU_HVILSts 0 "Init" 1 "Normal" 2 "Error" 3 "Reserved" ;
VAL_ 865 HCU_BMSSleepCmd 0 "no sleep" 1 "sleep" ;
VAL_ 865 HCU_P2MActHvDcCurr_RM 0 "Valid value" 20000 "Valid value" 20001 "Reserved" 65533 "Reserved" 65534 "Error" 65535 "Invalid" ;
VAL_ 865 HCU_P2MActHvDcVolt_RM 0 "Valid value" 60000 "Valid value" 60001 "Reserved" 65533 "Reserved" 65534 "Error" 65535 "Invalid" ;
VAL_ 865 HCU_DTCNumber1 0 "Valid values" 1023 "Valid values" ;
VAL_ 865 HCU_DTCNumber2 0 "Valid values" 1023 "Valid values" ;
VAL_ 865 HCU_MotorAmount_RM 0 "Reserved" 1 "Valid value" 253 "Valid value" 254 "Invalid value" 255 "Invalid value" ;
VAL_ 909 HCU_PowertrainSts_RM 1 "ON" 2 "OFF" 3 "Other Mode" ;
VAL_ 909 HCU_BrkPowflag_RM 0 "No power" 1 "Power" ;
VAL_ 909 HCU_ChargSts_RM 1 "Parking charging" 2 "Driving charging" 3 "Uncharged" 4 "Charge end" 5 "Reserved" 7 "Reserved" ;
VAL_ 909 HCU_PTDrvMod_RM 1 "EV Mode" 2 "Hybrid Mode" 3 "Fuel oil Mode" ;
VAL_ 909 HCU_Powerflag_RM 0 "No power" 1 "Power" ;
VAL_ 909 HCU_AccelPedalPosn_Diag_RM 0 "Vaild value" 100 "Vaild value" ;
VAL_ 909 HCU_BrkPedalSts_RM 0 "0%" 101 "Brake pedal pressed" ;
VAL_ 909 HCU_WakeUpSrc 0 "Power up via ignition switch" 1 "Power up via reservation of AC" 2 "Power up via AC Immediate Charging" 3 "Power up via AC Delay Charging" 4 "Power up via DC Charging" 5 "Power up via intelligent DCDC charging" 6 "Power up via battery warm keep by charger requirement" 7 "Power up via battery reservation heating" 8 "Power up via intelligent battery temperature management" 9 "Power up via low temperature hearing before charge" 10 "Power up via V2L" 11 "Reserved" 15 "Reserved" ;
VAL_ 909 HCU_CurrHybSysSts 0 "Vaild value" 500 "Vaild value" ;
VAL_ 937 BMS_ISC_ROhm_Warn 0 "Valid value" 50 "Valid value" 51 "Reserved" 254 "Reserved" 255 "Invalid" ;
VAL_ 937 BMS_ISC_SOC_Warn 0 "Valid value" 100 "Valid value" 101 "Reserved" 254 "Reserved" 255 "Invalid" ;
VAL_ 937 BMS_ISC_T_Warn 0 "Valid value" 165 "Valid value" 166 "Reserved" 254 "Reserved" 255 "invalid" ;
VAL_ 937 BMS_ISC_V_Warn 0 "Valid value" 50 "Valid value" 51 "Reserved" 254 "Reserved" 255 "Invalid" ;
VAL_ 942 BMS_SocJumpWarn_RM 0 "No warning" 1 "warning" ;
VAL_ 942 BMS_PackOverChrgWarn_RM 0 "No warning" 1 "warning" ;
VAL_ 942 BMS_ChrgSts_RM 0 "Uncharged" 1 "Parking charging" 2 "Driving charging" 3 "Charge end" ;
VAL_ 942 BMS_IsolationRValue_RM 0 "Valid value" 60000 "Valid value" 60001 "Reseved" 65535 "Reseved" ;
VAL_ 942 BMS_PackCurr_RM 0 "Valid value" 20000 "Valid value" 20001 "Reserved" 32767 "Reserved" ;
VAL_ 942 BMS_SocOverWarn_RM 0 "No warning" 1 "warning" ;
VAL_ 942 BMS_BattOverTempRank_RM 0 "Normal" 1 "Waining" ;
VAL_ 942 BMS_BattOverVoltRank_RM 0 "Normal" 1 "Waining" ;
VAL_ 942 BMS_BattSOCLowRank_RM 0 "Normal" 1 "Waining" ;
VAL_ 942 BMS_VCUIsolateErr_RM 0 "Normal" 1 "Waining" ;
VAL_ 942 BMS_BattUnderVoltRank_RM 0 "Normal" 1 "Waining" ;
VAL_ 942 BMS_CellDeltaVoltRank_RM 0 "Normal" 1 "Waining" ;
VAL_ 942 BMS_CellOverVoltRank_RM 0 "Normal" 1 "Waining" ;
VAL_ 942 BMS_CellUnderVoltRank_RM 0 "Normal" 1 "Waining" ;
VAL_ 942 BMS_DeltaTempRank_RM 0 "Normal" 1 "Waining" ;
VAL_ 942 BMS_PackMismatchWarn_RM 0 "No warning" 1 "warning" ;
VAL_ 942 BMS_PackVolt_RM 0 "Valid value" 10000 "Valid value" 10001 "Reserved" 16383 "Reserved" ;
VAL_ 957 DCDC_Tempwarning_RM 0 "No warning" 1 "warning" ;
VAL_ 957 DCDC_ActSts_RM 0 "Initial value" 1 "On" 2 "Off" 3 "Reserved" ;
VAL_ 957 DCDC_FailStswarning_RM 0 "No warning" 1 "warning" ;
VAL_ 959 BMS_ChrgDurationTime 0 "Valid value" 1022 "Valid value" 1023 "Invalid" ;
VAL_ 963 P2M_MotorSerNumber_RM 0 "Reserved" 1 "Valid value" 253 "Valid value" 254 "Invalid value" 255 "Invalid value" ;
VAL_ 963 P2M_InvActTemp_RM 0 "Valid value" 250 "Valid value" 251 "Reserved" 253 "Reserved" 254 "Error" 255 "Invalid value" ;
VAL_ 963 P2M_ActSpd_RM 0 "Valid value" 65531 "Valid value" 65532 "Rerserved" 65533 "Rerserved" 65534 "Error" 65535 "Invalid value" ;
VAL_ 963 P2M_ActTrq_RM 0 "Valid value" 65531 "Valid value" 65532 "Reserved" 65533 "Reserved" 65534 "Error" 65535 "Invalid value" ;
VAL_ 967 P2M_ActTemp_RM 0 "Valid value" 250 "Valid value" 251 "Reserved" 253 "Reserved" 254 "Error" 255 "Invalid value" ;
VAL_ 967 P2M_OperMode_RM 0 "Reserved" 1 "Consume power" 2 "Generate electricity" 3 "Shut down" 4 "Ready" 5 "Reserved" 253 "Reserved" 254 "Error" 255 "Invalid value" ;
VAL_ 967 P2M_InvTempwarning_RM 0 "Normal" 1 "Warning" ;
VAL_ 967 P2M_Tempwarning_RM 0 "Normal" 1 "Warning" ;
VAL_ 976 BMS_BattTempMax 0 "Valid value" 130 "Valid value" 131 "Reserved" 254 "Reserved" 255 "invalid" ;
VAL_ 976 BMS_BattTempMin 0 "Valid value" 130 "Valid value" 131 "Reserved" 254 "Reserved" 255 "invalid" ;
VAL_ 977 BMS_SingleCellVolt_1 0 "Valid value" 60000 "Valid value" 60001 "Reserved" 65535 "Reserved" ;
VAL_ 977 BMS_SingleCellVolt_2 0 "Valid value" 60000 "Valid value" 60001 "Reserved" 65535 "Reserved" ;
VAL_ 977 BMS_SingleCellVolt_3 0 "Valid value" 60000 "Valid value" 60001 "Reserved" 65535 "Reserved" ;
VAL_ 977 BMS_SingleCellVolt_4 0 "Valid value" 60000 "Valid value" 60001 "Reserved" 65535 "Reserved" ;
VAL_ 977 BMS_SingleCellVolt_5 0 "Valid value" 60000 "Valid value" 60001 "Reserved" 65535 "Reserved" ;
VAL_ 977 BMS_SingleCellVolt_6 0 "Valid value" 60000 "Valid value" 60001 "Reserved" 65535 "Reserved" ;
VAL_ 977 BMS_SingleCellVolt_7 0 "Valid value" 60000 "Valid value" 60001 "Reserved" 65535 "Reserved" ;
VAL_ 977 BMS_SingleCellVolt_8 0 "Valid value" 60000 "Valid value" 60001 "Reserved" 65535 "Reserved" ;
VAL_ 977 BMS_SingleCellVolt_9 0 "Valid value" 60000 "Valid value" 60001 "Reserved" 65535 "Reserved" ;
VAL_ 977 BMS_SingleCellVolt_10 0 "Valid value" 60000 "Valid value" 60001 "Reserved" 65535 "Reserved" ;
VAL_ 977 BMS_SingleCellVolt_11 0 "Valid value" 60000 "Valid value" 60001 "Reserved" 65535 "Reserved" ;
VAL_ 977 BMS_SingleCellVolt_12 0 "Valid value" 60000 "Valid value" 60001 "Reserved" 65535 "Reserved" ;
VAL_ 977 BMS_BattModuleTe_11 0 "Valid value" 165 "Valid value" 166 "Reserved" 254 "Reserved" 255 "invalid" ;
VAL_ 977 BMS_BattModuleTe_12 0 "Valid value" 165 "Valid value" 166 "Reserved" 254 "Reserved" 255 "invalid" ;
VAL_ 977 BMS_BattModuleTe_21 0 "Valid value" 165 "Valid value" 166 "Reserved" 254 "Reserved" 255 "invalid" ;
VAL_ 977 BMS_BattModuleTe_22 0 "Valid value" 165 "Valid value" 166 "Reserved" 254 "Reserved" 255 "invalid" ;
VAL_ 977 BMS_BattModuleTe_31 0 "Valid value" 165 "Valid value" 166 "Reserved" 254 "Reserved" 255 "invalid" ;
VAL_ 977 BMS_BattModuleTe_32 0 "Valid value" 165 "Valid value" 166 "Reserved" 254 "Reserved" 255 "invalid" ;
VAL_ 977 BMS_BattModuleTe_41 0 "Valid value" 165 "Valid value" 166 "Reserved" 254 "Reserved" 255 "invalid" ;
VAL_ 977 BMS_BattModuleTe_42 0 "Valid value" 165 "Valid value" 166 "Reserved" 254 "Reserved" 255 "invalid" ;
VAL_ 977 BMS_BattModuleTe_51 0 "Valid value" 165 "Valid value" 166 "Reserved" 254 "Reserved" 255 "invalid" ;
VAL_ 977 BMS_BattModuleTe_52 0 "Valid value" 165 "Valid value" 166 "Reserved" 254 "Reserved" 255 "invalid" ;
VAL_ 977 BMS_BattModuleTe_61 0 "Valid value" 165 "Valid value" 166 "Reserved" 254 "Reserved" 255 "invalid" ;
VAL_ 977 BMS_BattModuleTe_62 0 "Valid value" 165 "Valid value" 166 "Reserved" 254 "Reserved" 255 "invalid" ;
VAL_ 977 BMS_BattModuleTe_71 0 "Valid value" 165 "Valid value" 166 "Reserved" 254 "Reserved" 255 "invalid" ;
VAL_ 977 BMS_BattModuleTe_72 0 "Valid value" 165 "Valid value" 166 "Reserved" 254 "Reserved" 255 "invalid" ;
VAL_ 977 BMS_BattModuleTe_81 0 "Valid value" 165 "Valid value" 166 "Reserved" 254 "Reserved" 255 "invalid" ;
VAL_ 977 BMS_BattModuleTe_82 0 "Valid value" 165 "Valid value" 166 "Reserved" 254 "Reserved" 255 "invalid" ;
VAL_ 978 BMS_SingleCellVolt_13 0 "Valid value" 60000 "Valid value" 60001 "Reserved" 65535 "Reserved" ;
VAL_ 978 BMS_SingleCellVolt_14 0 "Valid value" 60000 "Valid value" 60001 "Reserved" 65535 "Reserved" ;
VAL_ 978 BMS_SingleCellVolt_15 0 "Valid value" 60000 "Valid value" 60001 "Reserved" 65535 "Reserved" ;
VAL_ 978 BMS_SingleCellVolt_16 0 "Valid value" 60000 "Valid value" 60001 "Reserved" 65535 "Reserved" ;
VAL_ 978 BMS_SingleCellVolt_17 0 "Valid value" 60000 "Valid value" 60001 "Reserved" 65535 "Reserved" ;
VAL_ 978 BMS_SingleCellVolt_18 0 "Valid value" 60000 "Valid value" 60001 "Reserved" 65535 "Reserved" ;
VAL_ 978 BMS_SingleCellVolt_19 0 "Valid value" 60000 "Valid value" 60001 "Reserved" 65535 "Reserved" ;
VAL_ 978 BMS_SingleCellVolt_20 0 "Valid value" 60000 "Valid value" 60001 "Reserved" 65535 "Reserved" ;
VAL_ 978 BMS_SingleCellVolt_21 0 "Valid value" 60000 "Valid value" 60001 "Reserved" 65535 "Reserved" ;
VAL_ 978 BMS_SingleCellVolt_22 0 "Valid value" 60000 "Valid value" 60001 "Reserved" 65535 "Reserved" ;
VAL_ 978 BMS_SingleCellVolt_23 0 "Valid value" 60000 "Valid value" 60001 "Reserved" 65535 "Reserved" ;
VAL_ 978 BMS_SingleCellVolt_24 0 "Valid value" 60000 "Valid value" 60001 "Reserved" 65535 "Reserved" ;
VAL_ 978 BMS_SingleCellVolt_25 0 "Valid value" 60000 "Valid value" 60001 "Reserved" 65535 "Reserved" ;
VAL_ 978 BMS_SingleCellVolt_26 0 "Valid value" 60000 "Valid value" 60001 "Reserved" 65535 "Reserved" ;
VAL_ 978 BMS_SingleCellVolt_27 0 "Valid value" 60000 "Valid value" 60001 "Reserved" 65535 "Reserved" ;
VAL_ 978 BMS_SingleCellVolt_28 0 "Valid value" 60000 "Valid value" 60001 "Reserved" 65535 "Reserved" ;
VAL_ 978 BMS_SingleCellVolt_29 0 "Valid value" 60000 "Valid value" 60001 "Reserved" 65535 "Reserved" ;
VAL_ 978 BMS_SingleCellVolt_30 0 "Valid value" 60000 "Valid value" 60001 "Reserved" 65535 "Reserved" ;
VAL_ 978 BMS_SingleCellVolt_31 0 "Valid value" 60000 "Valid value" 60001 "Reserved" 65535 "Reserved" ;
VAL_ 978 BMS_SingleCellVolt_32 0 "Valid value" 60000 "Valid value" 60001 "Reserved" 65535 "Reserved" ;
VAL_ 978 BMS_SingleCellVolt_33 0 "Valid value" 60000 "Valid value" 60001 "Reserved" 65535 "Reserved" ;
VAL_ 978 BMS_SingleCellVolt_34 0 "Valid value" 60000 "Valid value" 60001 "Reserved" 65535 "Reserved" ;
VAL_ 978 BMS_SingleCellVolt_35 0 "Valid value" 60000 "Valid value" 60001 "Reserved" 65535 "Reserved" ;
VAL_ 978 BMS_SingleCellVolt_36 0 "Valid value" 60000 "Valid value" 60001 "Reserved" 65535 "Reserved" ;
VAL_ 978 BMS_SingleCellVolt_37 0 "Valid value" 60000 "Valid value" 60001 "Reserved" 65535 "Reserved" ;
VAL_ 978 BMS_SingleCellVolt_38 0 "Valid value" 60000 "Valid value" 60001 "Reserved" 65535 "Reserved" ;
VAL_ 978 BMS_SingleCellVolt_39 0 "Valid value" 60000 "Valid value" 60001 "Reserved" 65535 "Reserved" ;
VAL_ 978 BMS_SingleCellVolt_40 0 "Valid value" 60000 "Valid value" 60001 "Reserved" 65535 "Reserved" ;
VAL_ 979 BMS_SingleCellVolt_41 0 "Valid value" 60000 "Valid value" 60001 "Reserved" 65535 "Reserved" ;
VAL_ 979 BMS_SingleCellVolt_42 0 "Valid value" 60000 "Valid value" 60001 "Reserved" 65535 "Reserved" ;
VAL_ 979 BMS_SingleCellVolt_43 0 "Valid value" 60000 "Valid value" 60001 "Reserved" 65535 "Reserved" ;
VAL_ 979 BMS_SingleCellVolt_44 0 "Valid value" 60000 "Valid value" 60001 "Reserved" 65535 "Reserved" ;
VAL_ 979 BMS_SingleCellVolt_45 0 "Valid value" 60000 "Valid value" 60001 "Reserved" 65535 "Reserved" ;
VAL_ 979 BMS_SingleCellVolt_46 0 "Valid value" 60000 "Valid value" 60001 "Reserved" 65535 "Reserved" ;
VAL_ 979 BMS_SingleCellVolt_47 0 "Valid value" 60000 "Valid value" 60001 "Reserved" 65535 "Reserved" ;
VAL_ 979 BMS_SingleCellVolt_48 0 "Valid value" 60000 "Valid value" 60001 "Reserved" 65535 "Reserved" ;
VAL_ 979 BMS_SingleCellVolt_49 0 "Valid value" 60000 "Valid value" 60001 "Reserved" 65535 "Reserved" ;
VAL_ 979 BMS_SingleCellVolt_50 0 "Valid value" 60000 "Valid value" 60001 "Reserved" 65535 "Reserved" ;
VAL_ 979 BMS_SingleCellVolt_51 0 "Valid value" 60000 "Valid value" 60001 "Reserved" 65535 "Reserved" ;
VAL_ 979 BMS_SingleCellVolt_52 0 "Valid value" 60000 "Valid value" 60001 "Reserved" 65535 "Reserved" ;
VAL_ 979 BMS_SingleCellVolt_53 0 "Valid value" 60000 "Valid value" 60001 "Reserved" 65535 "Reserved" ;
VAL_ 979 BMS_SingleCellVolt_54 0 "Valid value" 60000 "Valid value" 60001 "Reserved" 65535 "Reserved" ;
VAL_ 979 BMS_SingleCellVolt_55 0 "Valid value" 60000 "Valid value" 60001 "Reserved" 65535 "Reserved" ;
VAL_ 979 BMS_SingleCellVolt_56 0 "Valid value" 60000 "Valid value" 60001 "Reserved" 65535 "Reserved" ;
VAL_ 979 BMS_SingleCellVolt_57 0 "Valid value" 60000 "Valid value" 60001 "Reserved" 65535 "Reserved" ;
VAL_ 979 BMS_SingleCellVolt_58 0 "Valid value" 60000 "Valid value" 60001 "Reserved" 65535 "Reserved" ;
VAL_ 979 BMS_SingleCellVolt_59 0 "Valid value" 60000 "Valid value" 60001 "Reserved" 65535 "Reserved" ;
VAL_ 979 BMS_SingleCellVolt_60 0 "Valid value" 60000 "Valid value" 60001 "Reserved" 65535 "Reserved" ;
VAL_ 979 BMS_SingleCellVolt_61 0 "Valid value" 60000 "Valid value" 60001 "Reserved" 65535 "Reserved" ;
VAL_ 979 BMS_SingleCellVolt_62 0 "Valid value" 60000 "Valid value" 60001 "Reserved" 65535 "Reserved" ;
VAL_ 979 BMS_SingleCellVolt_63 0 "Valid value" 60000 "Valid value" 60001 "Reserved" 65535 "Reserved" ;
VAL_ 979 BMS_SingleCellVolt_64 0 "Valid value" 60000 "Valid value" 60001 "Reserved" 65535 "Reserved" ;
VAL_ 979 BMS_SingleCellVolt_65 0 "Valid value" 60000 "Valid value" 60001 "Reserved" 65535 "Reserved" ;
VAL_ 979 BMS_SingleCellVolt_66 0 "Valid value" 60000 "Valid value" 60001 "Reserved" 65535 "Reserved" ;
VAL_ 979 BMS_SingleCellVolt_67 0 "Valid value" 60000 "Valid value" 60001 "Reserved" 65535 "Reserved" ;
VAL_ 979 BMS_SingleCellVolt_68 0 "Valid value" 60000 "Valid value" 60001 "Reserved" 65535 "Reserved" ;
VAL_ 980 BMS_SingleCellVolt_69 0 "Valid value" 60000 "Valid value" 60001 "Reserved" 65535 "Reserved" ;
VAL_ 980 BMS_SingleCellVolt_70 0 "Valid value" 60000 "Valid value" 60001 "Reserved" 65535 "Reserved" ;
VAL_ 980 BMS_SingleCellVolt_71 0 "Valid value" 60000 "Valid value" 60001 "Reserved" 65535 "Reserved" ;
VAL_ 980 BMS_SingleCellVolt_72 0 "Valid value" 60000 "Valid value" 60001 "Reserved" 65535 "Reserved" ;
VAL_ 980 BMS_SingleCellVolt_73 0 "Valid value" 60000 "Valid value" 60001 "Reserved" 65535 "Reserved" ;
VAL_ 980 BMS_SingleCellVolt_74 0 "Valid value" 60000 "Valid value" 60001 "Reserved" 65535 "Reserved" ;
VAL_ 980 BMS_SingleCellVolt_75 0 "Valid value" 60000 "Valid value" 60001 "Reserved" 65535 "Reserved" ;
VAL_ 980 BMS_SingleCellVolt_76 0 "Valid value" 60000 "Valid value" 60001 "Reserved" 65535 "Reserved" ;
VAL_ 980 BMS_SingleCellVolt_77 0 "Valid value" 60000 "Valid value" 60001 "Reserved" 65535 "Reserved" ;
VAL_ 980 BMS_SingleCellVolt_78 0 "Valid value" 60000 "Valid value" 60001 "Reserved" 65535 "Reserved" ;
VAL_ 980 BMS_SingleCellVolt_79 0 "Valid value" 60000 "Valid value" 60001 "Reserved" 65535 "Reserved" ;
VAL_ 980 BMS_SingleCellVolt_80 0 "Valid value" 60000 "Valid value" 60001 "Reserved" 65535 "Reserved" ;
VAL_ 980 BMS_SingleCellVolt_81 0 "Valid value" 60000 "Valid value" 60001 "Reserved" 65535 "Reserved" ;
VAL_ 980 BMS_SingleCellVolt_82 0 "Valid value" 60000 "Valid value" 60001 "Reserved" 65535 "Reserved" ;
VAL_ 980 BMS_SingleCellVolt_83 0 "Valid value" 60000 "Valid value" 60001 "Reserved" 65535 "Reserved" ;
VAL_ 980 BMS_SingleCellVolt_84 0 "Valid value" 60000 "Valid value" 60001 "Reserved" 65535 "Reserved" ;
VAL_ 980 BMS_SingleCellVolt_85 0 "Valid value" 60000 "Valid value" 60001 "Reserved" 65535 "Reserved" ;
VAL_ 980 BMS_SingleCellVolt_86 0 "Valid value" 60000 "Valid value" 60001 "Reserved" 65535 "Reserved" ;
VAL_ 980 BMS_SingleCellVolt_87 0 "Valid value" 60000 "Valid value" 60001 "Reserved" 65535 "Reserved" ;
VAL_ 980 BMS_SingleCellVolt_88 0 "Valid value" 60000 "Valid value" 60001 "Reserved" 65535 "Reserved" ;
VAL_ 980 BMS_SingleCellVolt_89 0 "Valid value" 60000 "Valid value" 60001 "Reserved" 65535 "Reserved" ;
VAL_ 980 BMS_SingleCellVolt_90 0 "Valid value" 60000 "Valid value" 60001 "Reserved" 65535 "Reserved" ;
VAL_ 980 BMS_SingleCellVolt_91 0 "Valid value" 60000 "Valid value" 60001 "Reserved" 65535 "Reserved" ;
VAL_ 980 BMS_SingleCellVolt_92 0 "Valid value" 60000 "Valid value" 60001 "Reserved" 65535 "Reserved" ;
VAL_ 980 BMS_SingleCellVolt_93 0 "Valid value" 60000 "Valid value" 60001 "Reserved" 65535 "Reserved" ;
VAL_ 980 BMS_SingleCellVolt_94 0 "Valid value" 60000 "Valid value" 60001 "Reserved" 65535 "Reserved" ;
VAL_ 980 BMS_SingleCellVolt_95 0 "Valid value" 60000 "Valid value" 60001 "Reserved" 65535 "Reserved" ;
VAL_ 980 BMS_SingleCellVolt_96 0 "Valid value" 60000 "Valid value" 60001 "Reserved" 65535 "Reserved" ;
VAL_ 981 BMS_SingleCellVolt_97 0 "Valid value" 60000 "Valid value" 60001 "Reserved" 65535 "Reserved" ;
VAL_ 981 BMS_SingleCellVolt_98 0 "Valid value" 60000 "Valid value" 60001 "Reserved" 65535 "Reserved" ;
VAL_ 981 BMS_SingleCellVolt_99 0 "Valid value" 60000 "Valid value" 60001 "Reserved" 65535 "Reserved" ;
VAL_ 981 BMS_SingleCellVolt_100 0 "Valid value" 60000 "Valid value" 60001 "Reserved" 65535 "Reserved" ;
VAL_ 981 BMS_SingleCellVolt_101 0 "Valid value" 60000 "Valid value" 60001 "Reserved" 65535 "Reserved" ;
VAL_ 981 BMS_SingleCellVolt_102 0 "Valid value" 60000 "Valid value" 60001 "Reserved" 65535 "Reserved" ;
VAL_ 981 BMS_SingleCellVolt_103 0 "Valid value" 60000 "Valid value" 60001 "Reserved" 65535 "Reserved" ;
VAL_ 981 BMS_SingleCellVolt_104 0 "Valid value" 60000 "Valid value" 60001 "Reserved" 65535 "Reserved" ;
VAL_ 981 BMS_SingleCellVolt_105 0 "Valid value" 60000 "Valid value" 60001 "Reserved" 65535 "Reserved" ;
VAL_ 981 BMS_SingleCellVolt_106 0 "Valid value" 60000 "Valid value" 60001 "Reserved" 65535 "Reserved" ;
VAL_ 981 BMS_SingleCellVolt_107 0 "Valid value" 60000 "Valid value" 60001 "Reserved" 65535 "Reserved" ;
VAL_ 981 BMS_SingleCellVolt_108 0 "Valid value" 60000 "Valid value" 60001 "Reserved" 65535 "Reserved" ;
VAL_ 981 BMS_BattModuleTe_13 0 "Valid value" 165 "Valid value" 166 "Reserved" 254 "Reserved" 255 "invalid" ;
VAL_ 981 BMS_BattModuleTe_23 0 "Valid value" 165 "Valid value" 166 "Reserved" 254 "Reserved" 255 "invalid" ;
VAL_ 981 BMS_BattModuleTe_33 0 "Valid value" 165 "Valid value" 166 "Reserved" 254 "Reserved" 255 "invalid" ;
VAL_ 981 BMS_DTCNumber 0 "Default" 1 "Valid value" 501 "Valid value" 502 "Resrved" 511 "Resrved" ;
VAL_ 981 BMS_BattModuleTe_91 0 "Valid value" 165 "Valid value" 166 "Reserved" 254 "Reserved" 255 "invalid" ;
VAL_ 981 BMS_BattModuleTe_92 0 "Valid value" 165 "Valid value" 166 "Reserved" 254 "Reserved" 255 "invalid" ;
VAL_ 981 BMS_DTCNumber1 0 "Default" 1 "Valid value" 501 "Valid value" 502 "Resrved" 511 "Resrved" ;
VAL_ 981 BMS_DTCNumber2 0 "Default" 1 "Valid value" 501 "Valid value" 502 "Resrved" 511 "Resrved" ;
VAL_ 1009 BMS_SOCLowWarn 0 "Normal" 1 "Need to charge" ;
VAL_ 1009 BMS_CellUnderVolt 0 "Normal" 1 "warning" ;
VAL_ 1009 BMS_CellOverVolt 0 "Normal" 1 "warning" ;
VAL_ 1009 BMS_CellDeltaVolt 0 "Normal" 1 "warning" ;
VAL_ 1009 BMS_BattUnderVolt 0 "Normal" 1 "warning" ;
VAL_ 1009 BMS_BattOverVolt 0 "Normal" 1 "warning" ;
VAL_ 1009 BMS_BattUnderTemp 0 "Normal" 1 "warning" ;
VAL_ 1009 BMS_SOC_Plaucheck 0 "Normal" 1 "warningÃ¯Â¼ÂˆÃ¯Â¼Âž10%Ã¯Â¼Â‰" ;
VAL_ 1009 BMS_DeltaTemp 0 "Normal" 1 "warning" ;
VAL_ 1009 BMS_CANComErr 0 "Normal" 1 "warning" ;
VAL_ 1009 BMS_BattSOCLow 0 "Normal" 1 "warning" ;
VAL_ 1009 BMS_BattSOCTooLow 0 "Normal" 1 "warning" ;
VAL_ 1009 BMS_BattSOCHigh 0 "Normal" 1 "warning" ;
VAL_ 1009 BMS_ChrgnCurrLager 0 "Normal" 1 "warning" ;
VAL_ 1009 BMS_DischrgnCurrLager 0 "Normal" 1 "warning" ;
VAL_ 1009 BMS_ModuleMismatchWarn 0 "Normal" 1 "warning" ;
VAL_ 1009 BMS_cohrnc 0 "Normal" 1 "warning" ;
VAL_ 1009 BMS_moduleNumber 0 "Module1~Module9" 8 "Module1~Module9" ;
VAL_ 1009 BMS_NumModuleTempSnsr 0 "sensor1~sensor18" 15 "sensor1~sensor18" ;
VAL_ 1009 BMS_NumCell 0 "Cell1~Cell108" 107 "Cell1~Cell108" 108 "Reserved" 255 "Reserved" ;
VAL_ 1010 BMS_CellVoltMin 0 "Valid value" 65535 "Valid value" ;
VAL_ 1010 BMS_NumberCellVoltMin 0 "Cell1~Cell108" 107 "Cell1~Cell108" 108 "Reserved" 255 "Reserved" ;
VAL_ 1010 BMS_CellMaxVolt 0 "Valid value" 65535 "Valid value" ;
VAL_ 1010 BMS_NumberCellMaxVolt 0 "Cell1~Cell108" 107 "Cell1~Cell108" 108 "Reserved" 255 "Reserved" ;
VAL_ 1010 BMS_CellBalanceSts 0 "not active" 1 "active normally" 2 "reserved" 3 "reserved" ;
VAL_ 1010 BMS_RlyCounterSts 0 "Normal" 1 "positive relay OUL(over use of life)" 2 "negative relay OUL" 3 "Precharge relay OUL" ;
VAL_ 1010 BMS_SOH_R 0 "Valid value" 1000 "Valid value" 1001 "Reserved" 1022 "Reserved" 1023 "Invalid" ;
VAL_ 1011 BMS_ModuleMinTemp 0 "Valid Value" 130 "Valid Value" 131 "Reserved" 254 "Reserved" 255 "Invalid" ;
VAL_ 1011 BMS_ModuleNumCellMinTemp 0 "Module1~Module9" 8 "Module1~Module9" ;
VAL_ 1011 BMS_ModuleNumCellMaxTemp 0 "Module1~Module9" 8 "Module1~Module9" ;
VAL_ 1011 BMS_ModuleMaxTemp 0 "Valid Value" 130 "Valid Value" 131 "Reserved" 254 "Reserved" 255 "Invalid" ;
VAL_ 1011 BMS_NumCellMinTemp 0 "Module1~Module17" 17 "Module1~Module17" ;
VAL_ 1011 BMS_NumCellMaxTemp 0 "Module1~Module17" 17 "Module1~Module17" ;
VAL_ 1011 BMS_PackMismatchWarn 0 "Normal" 1 "warning" ;
VAL_ 1011 BMS_OverChargeErr 0 "Normal" 1 "warning" ;
VAL_ 1011 BMS_IsolationErr 0 "Normal" 1 "warning" ;
VAL_ 1011 BMS_HVILErr 0 "Normal" 1 "warning" ;
VAL_ 1011 BMS_BattOverTempWarn 0 "Normal" 1 "warning 1 (55~65Ã‚ÂºC)" 2 "warning 2 (Ã¢Â‰Â¥65Ã‚ÂºC)" 3 "Reserved" ;
VAL_ 1011 BMS_ModuleNumberCellMinVolt 0 "Number1~number9" 8 "Number1~number9" ;
VAL_ 1011 BMS_ModuleNumberCellMaxVolt 0 "Number1~number9" 8 "Number1~number9" ;
VAL_ 130 NetEngTrq 0 "Valid values" 65534 "Valid values" 65535 "Invalid" ;
VAL_ 130 DrvEngTrqReq 0 "Valid values" 65535 "Valid values" ;
VAL_ 132 HCU_RaceLaunchAvail_0x84 0 "Race Launch is available" 1 "Race Launch is not available due to ESP is not OFF" 2 "Race Launch is not available due to temporary hybrid system limitations" 3 "Reserved" ;
VAL_ 132 HCU_RaceLaunchSts_0x84 0 "Inactive" 1 "Active" 2 "Timeout protection" 3 "Reserved" 7 "Reserved" ;
VAL_ 158 HCU_PowertrainSts_0x9e 0 "Sleep" 1 "Initialize Mode" 2 "power up" 3 "power down" 4 "Cellphone APP" 5 "run" 6 "Charging" 7 "Error Mode" 8 "Limphome" 9 "Emergency Mode" 10 "Service Mode" 11 "Prepare Sleep" 12 "Ready" 13 "Reserved" 15 "Reserved" ;
VAL_ 158 HCU_TotDrvReqPower_0x9e 0 "Valid Value" 200 "Valid Value" 201 "invalid" 255 "invalid" ;
VAL_ 158 TgtRcprtnTrqSts 0 "Not Initialized" 1 "Normal" 2 "Faulty" 3 "Reserved" ;
VAL_ 258 AccelPedlPosnDiagc 0 "Valid values" 255 "Valid values" ;
VAL_ 335 BMS_BattSOC_P0 0 "Valid value" 1000 "Valid value" 1001 "Reserved" 1022 "Reserved" 1023 "Invalid" ;
VAL_ 486 MultiColorNr1 0 "No command" 1 "Valid" 64 "Valid" 65 "Reserved" 127 "Reserved" ;
VAL_ 486 MultiColorNr2 0 "No command" 1 "Valid" 64 "Valid" 65 "Reserved" 127 "Reserved" ;
VAL_ 486 MultiColorNr3 0 "No command" 1 "Valid" 64 "Valid" 65 "Reserved" 127 "Reserved" ;
VAL_ 486 MultiColorNr4 0 "No command" 1 "Valid" 64 "Valid" 65 "Reserved" 127 "Reserved" ;
VAL_ 486 MultiColorNr5 0 "No command" 1 "Valid" 64 "Valid" 65 "Reserved" 127 "Reserved" ;
VAL_ 486 MultiColorNr6 0 "No command" 1 "Valid" 64 "Valid" 65 "Reserved" 127 "Reserved" ;
VAL_ 486 MultiColorNr7 0 "No command" 1 "Valid" 64 "Valid" 65 "Reserved" 127 "Reserved" ;
VAL_ 486 MultiColorNr8 0 "No command" 1 "Valid" 64 "Valid" 65 "Reserved" 127 "Reserved" ;
VAL_ 492 MultiColorNr9 0 "No command" 1 "Valid" 64 "Valid" 65 "Reserved" 127 "Reserved" ;
VAL_ 492 MultiColorNr10 0 "No command" 1 "Valid" 64 "Valid" 65 "Reserved" 127 "Reserved" ;
VAL_ 492 MultiColorNr11 0 "No command" 1 "Valid" 64 "Valid" 65 "Reserved" 127 "Reserved" ;
VAL_ 492 MultiColorNr12 0 "No command" 1 "Valid" 64 "Valid" 65 "Reserved" 127 "Reserved" ;
VAL_ 492 MultiColorNr13 0 "No command" 1 "Valid" 64 "Valid" 65 "Reserved" 127 "Reserved" ;
VAL_ 492 MultiColorNr14 0 "No command" 1 "Valid" 64 "Valid" 65 "Reserved" 127 "Reserved" ;
VAL_ 492 MultiColorNr15 0 "No command" 1 "Valid" 64 "Valid" 65 "Reserved" 127 "Reserved" ;
VAL_ 492 MultiColorNr16 0 "No command" 1 "Valid" 64 "Valid" 65 "Reserved" 127 "Reserved" ;
VAL_ 724 DPF_Warning 0 "No self-cleaning" 1 "Please place self-cleaning" 2 "Please start the car and keep idle" 3 "In the clean" 4 "Clean finishi,thank you for waiting" 5 "Reserved" 6 "Invalid" 7 "Invalid" ;
VAL_ 724 WIFSensorFailSts 0 "No failure" 1 "Failure" 2 "Reserved" 3 "Not available" ;
VAL_ 724 GlowPlugLmpCmd 0 "Off" 1 "On" 2 "Reserved" 3 "Not available" ;
VAL_ 724 UreaLampCmd 0 "Off" 1 "On" 2 "Flsah" 3 "Reserved" ;
VAL_ 724 Urea_Level 0 "0%" 1 "5%" 2 "10%" 3 "15%" 4 "20%" 5 "25%" 6 "30%" 7 "35%" 8 "40%" 9 "45%" 10 "50%" 11 "55%" 12 "60%" 13 "65%" 14 "70%" 15 "75%" 16 "80%" 17 "85%" 18 "90%" 19 "95%" 20 "100%" 21 "Reserved" ;
VAL_ 724 UreaRemainDist 0 "Valid value" 4095 "Valid value" ;
VAL_ 724 SCRSysWarnDisplay 0 "No warnÃ¤Â¸ÂÃ¦ÂÂÃ§Â¤Âº(Ã©Â»Â˜Ã¨Â®Â¤Ã¥Â€Â¼)" 1 "Urea level lowÃ¥Â°Â¿Ã§Â´Â Ã¦Â¶Â²Ã¤Â½ÂÃ¤Â½ÂŽ,Ã¨Â¯Â·Ã¥ÂŠÂ Ã¦Â³Â¨" 2 "Urea level tool lowÃ¥Â°Â¿Ã§Â´Â Ã¦Â¶Â²Ã¤Â½ÂÃ¦ÂžÂÃ¤Â½ÂŽ,Ã¨Â¯Â·Ã¥ÂŠÂ Ã¦Â³Â¨" 3 "Empty tank,next start prohibitÃ¥Â°Â¿Ã§Â´Â Ã§Â½ÂÃ§Â©Âº,Ã§Â¦ÂÃ¦Â­Â¢Ã¤Â¸Â‹Ã¦Â¬Â¡Ã¥ÂÂ¯Ã¥ÂŠÂ¨" 4 "Incorrect ureaÃ¥Â°Â¿Ã§Â´Â Ã¤Â¸ÂÃ¥ÂÂˆÃ¦Â Â¼,Ã¨Â¯Â·Ã¦Â£Â€Ã¦ÂŸÂ¥" 5 "Incorrect urea over limit dist Ã¥Â°Â¿Ã§Â´Â Ã¤Â¸ÂÃ¥ÂÂˆÃ¦Â Â¼Ã¨Â¡ÂŒÃ©Â©Â¶Ã¨Â¶Â…Ã¨Â¿Â‡50km" 6 "Urea fill intercept,please refillÃ¥Â°Â¿Ã§Â´Â Ã¥ÂŠÂ Ã¦Â³Â¨Ã¤Â¸Â­Ã¦Â­Â¢,Ã¨Â¯Â·Ã©Â‡ÂÃ¦Â–Â°Ã¥ÂŠÂ Ã¦Â³Â¨" 7 "Urea fill intercept over limit distÃ¥Â°Â¿Ã§Â´Â Ã¥ÂŠÂ Ã¦Â³Â¨Ã¤Â¸Â­Ã¦Â­Â¢Ã¨Â¡ÂŒÃ©Â©Â¶Ã¨Â¶Â…Ã¨Â¿Â‡50km" 8 "Engine start prohibitÃ¥Â°Â¿Ã§Â´Â Ã§Â³Â»Ã§Â»ÂŸÃ§Â¦ÂÃ¦Â­Â¢Ã¥ÂÂ‘Ã¥ÂŠÂ¨Ã¦ÂœÂºÃ¥ÂÂ¯Ã¥ÂŠÂ¨" 9 "SCR system fault,please checkÃ¥Â°Â¿Ã§Â´Â Ã§Â³Â»Ã§Â»ÂŸÃ¦Â•Â…Ã©ÂšÂœ,Ã¨Â¯Â·Ã¥Â…Â¥Ã§Â«Â™Ã¦Â£Â€Ã¦ÂŸÂ¥" 10 "SCR system fault over limit DistÃ¥Â°Â¿Ã§Â´Â Ã§Â³Â»Ã§Â»ÂŸÃ¦Â•Â…Ã©ÂšÂœÃ¨Â¡ÂŒÃ©Â©Â¶Ã¨Â¶Â…Ã¨Â¿Â‡50km" 11 "Driving dist over limition with fault, next start prohibitÃ¥Â°Â¿Ã§Â´Â Ã§Â³Â»Ã§Â»ÂŸÃ¦Â•Â…Ã©ÂšÂœÃ§Â¦ÂÃ¦Â­Â¢Ã¤Â¸Â‹Ã¦Â¬Â¡Ã¥ÂÂ¯Ã¥ÂŠÂ¨" 12 "Reserved" 15 "Reserved" ;
VAL_ 724 WIFFullLmpCmd 0 "Off" 1 "On" 2 "Reserved" 3 "Not available" ;
VAL_ 724 DPF_Activation 0 "No action" 1 "Active" 2 "Reserved" 3 "Invalid" ;
VAL_ 763 VMDR_TmpMonFctnSts 0 "NO set temporary disable" 1 "Set temporary disable" ;
VAL_ 763 VMDR_InitAlarmDlySetSts 0 "NO set delay" 1 "Set delay" ;
VAL_ 763 VMDR_FctnSts 0 "Invalid" 1 "Function normal" 2 "Function disable" 3 "Function fault" ;
VAL_ 848 EngOilLvlWrn 0 "No alarm" 1 "Oillevelmin alarm" 2 "Overfill alarm" 3 "Error" ;
VAL_ 848 EngOilLowPresWrn 0 "No alarm" 1 "Alarm" ;
VAL_ 848 EngOilPres 0 "Valid values" 120 "Valid values" 121 "Reserve" 126 "Reserve" 127 "Invalid value" ;
VAL_ 848 EngOilTemp 0 "Valid values" 200 "Valid values" 201 "Reserve" 254 "Reserve" 255 "Invalid value" ;
